VERSION "created by canmatrix"

NS_ :

BS_:

BU_: RadarRearRight RadarRearLeft

BO_ 1310 RRR_Obj07A: 64 Vector__XXX
 SG_ RRR_Obj07A_CRC : 0|16@1+ (1,0) [0|65535] "" Vector__XXX
 SG_ RRR_Obj07A_Ay : 103|9@1+ (0.0625,-16) [-16|15.9375] "m/s^2" Vector__XXX
 SG_ RRR_Obj07A_HeadingYawAngle : 112|9@1+ (0.0175,-4.48) [-3.15|3.15] "rad" Vector__XXX
 SG_ RRR_Obj07A_Length : 121|7@1+ (0.125,0) [0|15.875] "m" Vector__XXX
 SG_ RRR_Obj07A_Width : 128|7@1+ (0.125,0) [0|15.875] "m" Vector__XXX
 SG_ RRR_Obj07A_Height : 135|7@1+ (0.125,0) [0|15.875] "m" Vector__XXX
 SG_ RRR_Obj07A_DxVnce : 142|12@1+ (0.01,0) [0|30] "m^2" Vector__XXX
 SG_ RRR_Obj07A_DyVnce : 154|12@1+ (0.01,0) [0|30] "m^2" Vector__XXX
 SG_ RRR_Obj07A_DzVnce : 166|10@1+ (0.01,0) [0|10] "m^2" Vector__XXX
 SG_ RRR_Obj07A_AliveCtr : 16|8@1+ (1,0) [0|254] "" Vector__XXX
 SG_ RRR_Obj07A_VxVnce : 176|12@1+ (0.01,0) [0|30] "m^2/s^2" Vector__XXX
 SG_ RRR_Obj07A_VyVnce : 188|12@1+ (0.01,0) [0|30] "m^2/s^2" Vector__XXX
 SG_ RRR_Obj07A_AxVnce : 200|12@1+ (0.01,0) [0|30] "m^2/s^4" Vector__XXX
 SG_ RRR_Obj07A_AyVnce : 212|12@1+ (0.01,0) [0|30] "m^2/s^4" Vector__XXX
 SG_ RRR_Obj07A_RefPosIndex : 224|4@1+ (1,0) [0|15] "" Vector__XXX
 SG_ RRR_Obj07A_DxDyCoVnce : 228|12@1+ (0.01,0) [0|30] "m^2" Vector__XXX
 SG_ RRR_Obj07A_DxVxCoVnce : 240|12@1+ (0.01,0) [0|30] "m^2/s" Vector__XXX
 SG_ RRR_Obj07A_BlockCtr : 24|4@1+ (1,0) [0|15] "" Vector__XXX
 SG_ RRR_Obj07A_DyVxCoVnce : 252|12@1+ (0.01,0) [0|30] "m^2/s" Vector__XXX
 SG_ RRR_Obj07A_DxVyCoVnce : 264|12@1+ (0.01,0) [0|30] "m^2/s" Vector__XXX
 SG_ RRR_Obj07A_DyVyCoVnce : 276|12@1+ (0.01,0) [0|30] "m^2/s" Vector__XXX
 SG_ RRR_Obj07A_VxVyCoVnce : 288|12@1+ (0.01,0) [0|30] "m^2/s^2" Vector__XXX
 SG_ RRR_Obj07A_DxAxCoVnce : 300|12@1+ (0.01,0) [0|30] "m^2/s^2" Vector__XXX
 SG_ RRR_Obj07A_DyAxCoVnce : 312|12@1+ (0.01,0) [0|30] "m^2/s^2" Vector__XXX
 SG_ RRR_Obj07A_VxAxCoVnce : 324|12@1+ (0.01,0) [0|30] "m^2/s^3" Vector__XXX
 SG_ RRR_Obj07A_ObjectID : 32|7@1+ (1,0) [0|127] "" Vector__XXX
 SG_ RRR_Obj07A_VyAxCoVnce : 336|12@1+ (0.01,0) [0|30] "m^2/s^3" Vector__XXX
 SG_ RRR_Obj07A_DxAyCoVnce : 348|12@1+ (0.01,0) [0|30] "m^2/s^2" Vector__XXX
 SG_ RRR_Obj07A_DyAyCoVnce : 360|12@1+ (0.01,0) [0|30] "m^2/s^2" Vector__XXX
 SG_ RRR_Obj07A_VxAyCoVnce : 372|12@1+ (0.01,0) [0|30] "m^2/s^3" Vector__XXX
 SG_ RRR_Obj07A_VyAyCoVnce : 384|12@1+ (0.01,0) [0|30] "m^2/s^3" Vector__XXX
 SG_ RRR_Obj07A_AxAyCoVnce : 396|12@1+ (0.01,0) [0|30] "m^2/s^4" Vector__XXX
 SG_ RRR_Obj07A_Measured : 39|1@1+ (1,0) [0|1] "" Vector__XXX
 SG_ RRR_Obj07A_HeadingYawVnce : 408|12@1+ (0.0003,0) [0|1] "rad^2" Vector__XXX
 SG_ RRR_Obj07A_Dx : 40|13@1+ (0.0625,-256) [-256|255.9375] "m" Vector__XXX
 SG_ RRR_Obj07A_LengthVnce : 420|12@1+ (0.01,0) [0|30] "m^2" Vector__XXX
 SG_ RRR_Obj07A_WidthVnce : 432|12@1+ (0.01,0) [0|30] "m^2" Vector__XXX
 SG_ RRR_Obj07A_HeightVnce : 444|12@1+ (0.01,0) [0|30] "m^2" Vector__XXX
 SG_ RRR_Obj07A_ExistProb : 456|6@1+ (2,0) [0|100] "%" Vector__XXX
 SG_ RRR_Obj07A_ProbObstacle : 462|6@1+ (2,0) [0|100] "%" Vector__XXX
 SG_ RRR_Obj07A_ProbNonObstacle : 468|6@1+ (2,0) [0|100] "%" Vector__XXX
 SG_ RRR_Obj07A_ProbMobileObst : 474|6@1+ (2,0) [0|100] "%" Vector__XXX
 SG_ RRR_Obj07A_FV : 487|8@0+ (1,0) [0|255] "" Vector__XXX
 SG_ RRR_Obj07A_MAC : 495|24@0+ (1,0) [0|16777215] "" Vector__XXX
 SG_ RRR_Obj07A_Dz : 53|6@1+ (0.25,-5) [-5|10.75] "m" Vector__XXX
 SG_ RRR_Obj07A_Dy : 59|11@1+ (0.125,-128) [-128|127.875] "m" Vector__XXX
 SG_ RRR_Obj07A_Valid : 70|1@1+ (1,0) [0|1] "" Vector__XXX
 SG_ RRR_Obj07A_Vx : 71|12@1+ (0.0625,-128) [-128|127.9375] "m/s" Vector__XXX
 SG_ RRR_Obj07A_Vy : 83|10@1+ (0.125,-64) [-64|63.875] "m/s" Vector__XXX
 SG_ RRR_Obj07A_Ax : 93|10@1+ (0.03125,-16) [-16|15.96875] "m/s^2" Vector__XXX

BO_ 1311 RRR_Obj07B: 16 Vector__XXX
 SG_ RRR_Obj07B_CRC : 0|16@1+ (1,0) [0|65535] "" Vector__XXX
 SG_ RRR_Obj07B_MAC : 111|24@0+ (1,0) [0|16777215] "" Vector__XXX
 SG_ RRR_Obj07B_AliveCtr : 16|8@1+ (1,0) [0|254] "" Vector__XXX
 SG_ RRR_Obj07B_BlockCtr : 24|4@1+ (1,0) [0|15] "" Vector__XXX
 SG_ RRR_Obj07B_ProbMob4PlusWhl : 28|6@1+ (2,0) [0|100] "%" Vector__XXX
 SG_ RRR_Obj07B_ProbMob2Whl : 34|6@1+ (2,0) [0|100] "%" Vector__XXX
 SG_ RRR_Obj07B_ProbMobPed : 40|6@1+ (2,0) [0|100] "%" Vector__XXX
 SG_ RRR_Obj07B_Prob4PlusWhlCAR : 46|6@1+ (2,0) [0|100] "%" Vector__XXX
 SG_ RRR_Obj07B_Prob4PlusWhlbHGV : 52|6@1+ (2,0) [0|100] "%" Vector__XXX
 SG_ RRR_Obj07B_ProbGNDReflex : 58|6@1+ (2,0) [0|100] "%" Vector__XXX
 SG_ RRR_Obj07B_ProbStatBarrier : 64|6@1+ (2,0) [0|100] "%" Vector__XXX
 SG_ RRR_Obj07B_ProbStatObst : 70|6@1+ (2,0) [0|100] "%" Vector__XXX
 SG_ RRR_Obj07B_MovingProbability : 76|6@1+ (2,0) [0|100] "%" Vector__XXX
 SG_ RRR_Obj07B_MovingObserved : 82|6@1+ (2,0) [0|100] "%" Vector__XXX
 SG_ RRR_Obj07B_FV : 103|8@0+ (1,0) [0|255] "" Vector__XXX

BO_ 1312 RRR_Obj08A: 64 Vector__XXX
 SG_ RRR_Obj08A_CRC : 0|16@1+ (1,0) [0|65535] "" Vector__XXX
 SG_ RRR_Obj08A_Ay : 103|9@1+ (0.0625,-16) [-16|15.9375] "m/s^2" Vector__XXX
 SG_ RRR_Obj08A_HeadingYawAngle : 112|9@1+ (0.0175,-4.48) [-3.15|3.15] "rad" Vector__XXX
 SG_ RRR_Obj08A_Length : 121|7@1+ (0.125,0) [0|15.875] "m" Vector__XXX
 SG_ RRR_Obj08A_Width : 128|7@1+ (0.125,0) [0|15.875] "m" Vector__XXX
 SG_ RRR_Obj08A_Height : 135|7@1+ (0.125,0) [0|15.875] "m" Vector__XXX
 SG_ RRR_Obj08A_DxVnce : 142|12@1+ (0.01,0) [0|30] "m^2" Vector__XXX
 SG_ RRR_Obj08A_DyVnce : 154|12@1+ (0.01,0) [0|30] "m^2" Vector__XXX
 SG_ RRR_Obj08A_DzVnce : 166|10@1+ (0.01,0) [0|10] "m^2" Vector__XXX
 SG_ RRR_Obj08A_AliveCtr : 16|8@1+ (1,0) [0|254] "" Vector__XXX
 SG_ RRR_Obj08A_VxVnce : 176|12@1+ (0.01,0) [0|30] "m^2/s^2" Vector__XXX
 SG_ RRR_Obj08A_VyVnce : 188|12@1+ (0.01,0) [0|30] "m^2/s^2" Vector__XXX
 SG_ RRR_Obj08A_AxVnce : 200|12@1+ (0.01,0) [0|30] "m^2/s^4" Vector__XXX
 SG_ RRR_Obj08A_AyVnce : 212|12@1+ (0.01,0) [0|30] "m^2/s^4" Vector__XXX
 SG_ RRR_Obj08A_RefPosIndex : 224|4@1+ (1,0) [0|15] "" Vector__XXX
 SG_ RRR_Obj08A_DxDyCoVnce : 228|12@1+ (0.01,0) [0|30] "m^2" Vector__XXX
 SG_ RRR_Obj08A_DxVxCoVnce : 240|12@1+ (0.01,0) [0|30] "m^2/s" Vector__XXX
 SG_ RRR_Obj08A_BlockCtr : 24|4@1+ (1,0) [0|15] "" Vector__XXX
 SG_ RRR_Obj08A_DyVxCoVnce : 252|12@1+ (0.01,0) [0|30] "m^2/s" Vector__XXX
 SG_ RRR_Obj08A_DxVyCoVnce : 264|12@1+ (0.01,0) [0|30] "m^2/s" Vector__XXX
 SG_ RRR_Obj08A_DyVyCoVnce : 276|12@1+ (0.01,0) [0|30] "m^2/s" Vector__XXX
 SG_ RRR_Obj08A_VxVyCoVnce : 288|12@1+ (0.01,0) [0|30] "m^2/s^2" Vector__XXX
 SG_ RRR_Obj08A_DxAxCoVnce : 300|12@1+ (0.01,0) [0|30] "m^2/s^2" Vector__XXX
 SG_ RRR_Obj08A_DyAxCoVnce : 312|12@1+ (0.01,0) [0|30] "m^2/s^2" Vector__XXX
 SG_ RRR_Obj08A_VxAxCoVnce : 324|12@1+ (0.01,0) [0|30] "m^2/s^3" Vector__XXX
 SG_ RRR_Obj08A_ObjectID : 32|7@1+ (1,0) [0|127] "" Vector__XXX
 SG_ RRR_Obj08A_VyAxCoVnce : 336|12@1+ (0.01,0) [0|30] "m^2/s^3" Vector__XXX
 SG_ RRR_Obj08A_DxAyCoVnce : 348|12@1+ (0.01,0) [0|30] "m^2/s^2" Vector__XXX
 SG_ RRR_Obj08A_DyAyCoVnce : 360|12@1+ (0.01,0) [0|30] "m^2/s^2" Vector__XXX
 SG_ RRR_Obj08A_VxAyCoVnce : 372|12@1+ (0.01,0) [0|30] "m^2/s^3" Vector__XXX
 SG_ RRR_Obj08A_VyAyCoVnce : 384|12@1+ (0.01,0) [0|30] "m^2/s^3" Vector__XXX
 SG_ RRR_Obj08A_AxAyCoVnce : 396|12@1+ (0.01,0) [0|30] "m^2/s^4" Vector__XXX
 SG_ RRR_Obj08A_Measured : 39|1@1+ (1,0) [0|1] "" Vector__XXX
 SG_ RRR_Obj08A_HeadingYawVnce : 408|12@1+ (0.0003,0) [0|1] "rad^2" Vector__XXX
 SG_ RRR_Obj08A_Dx : 40|13@1+ (0.0625,-256) [-256|255.9375] "m" Vector__XXX
 SG_ RRR_Obj08A_LengthVnce : 420|12@1+ (0.01,0) [0|30] "m^2" Vector__XXX
 SG_ RRR_Obj08A_WidthVnce : 432|12@1+ (0.01,0) [0|30] "m^2" Vector__XXX
 SG_ RRR_Obj08A_HeightVnce : 444|12@1+ (0.01,0) [0|30] "m^2" Vector__XXX
 SG_ RRR_Obj08A_ExistProb : 456|6@1+ (2,0) [0|100] "%" Vector__XXX
 SG_ RRR_Obj08A_ProbObstacle : 462|6@1+ (2,0) [0|100] "%" Vector__XXX
 SG_ RRR_Obj08A_ProbNonObstacle : 468|6@1+ (2,0) [0|100] "%" Vector__XXX
 SG_ RRR_Obj08A_ProbMobileObst : 474|6@1+ (2,0) [0|100] "%" Vector__XXX
 SG_ RRR_Obj08A_FV : 487|8@0+ (1,0) [0|255] "" Vector__XXX
 SG_ RRR_Obj08A_MAC : 495|24@0+ (1,0) [0|16777215] "" Vector__XXX
 SG_ RRR_Obj08A_Dz : 53|6@1+ (0.25,-5) [-5|10.75] "m" Vector__XXX
 SG_ RRR_Obj08A_Dy : 59|11@1+ (0.125,-128) [-128|127.875] "m" Vector__XXX
 SG_ RRR_Obj08A_Valid : 70|1@1+ (1,0) [0|1] "" Vector__XXX
 SG_ RRR_Obj08A_Vx : 71|12@1+ (0.0625,-128) [-128|127.9375] "m/s" Vector__XXX
 SG_ RRR_Obj08A_Vy : 83|10@1+ (0.125,-64) [-64|63.875] "m/s" Vector__XXX
 SG_ RRR_Obj08A_Ax : 93|10@1+ (0.03125,-16) [-16|15.96875] "m/s^2" Vector__XXX

BO_ 1313 RRR_Obj08B: 16 Vector__XXX
 SG_ RRR_Obj08B_CRC : 0|16@1+ (1,0) [0|65535] "" Vector__XXX
 SG_ RRR_Obj08B_MAC : 111|24@0+ (1,0) [0|16777215] "" Vector__XXX
 SG_ RRR_Obj08B_AliveCtr : 16|8@1+ (1,0) [0|254] "" Vector__XXX
 SG_ RRR_Obj08B_BlockCtr : 24|4@1+ (1,0) [0|15] "" Vector__XXX
 SG_ RRR_Obj08B_ProbMob4PlusWhl : 28|6@1+ (2,0) [0|100] "%" Vector__XXX
 SG_ RRR_Obj08B_ProbMob2Whl : 34|6@1+ (2,0) [0|100] "%" Vector__XXX
 SG_ RRR_Obj08B_ProbMobPed : 40|6@1+ (2,0) [0|100] "%" Vector__XXX
 SG_ RRR_Obj08B_Prob4PlusWhlCAR : 46|6@1+ (2,0) [0|100] "%" Vector__XXX
 SG_ RRR_Obj08B_Prob4PlusWhlbHGV : 52|6@1+ (2,0) [0|100] "%" Vector__XXX
 SG_ RRR_Obj08B_ProbGNDReflex : 58|6@1+ (2,0) [0|100] "%" Vector__XXX
 SG_ RRR_Obj08B_ProbStatBarrier : 64|6@1+ (2,0) [0|100] "%" Vector__XXX
 SG_ RRR_Obj08B_ProbStatObst : 70|6@1+ (2,0) [0|100] "%" Vector__XXX
 SG_ RRR_Obj08B_MovingProbability : 76|6@1+ (2,0) [0|100] "%" Vector__XXX
 SG_ RRR_Obj08B_MovingObserved : 82|6@1+ (2,0) [0|100] "%" Vector__XXX
 SG_ RRR_Obj08B_FV : 103|8@0+ (1,0) [0|255] "" Vector__XXX

BO_ 1314 RRR_Obj09A: 64 Vector__XXX
 SG_ RRR_Obj09A_CRC : 0|16@1+ (1,0) [0|65535] "" Vector__XXX
 SG_ RRR_Obj09A_Ay : 103|9@1+ (0.0625,-16) [-16|15.9375] "m/s^2" Vector__XXX
 SG_ RRR_Obj09A_HeadingYawAngle : 112|9@1+ (0.0175,-4.48) [-3.15|3.15] "rad" Vector__XXX
 SG_ RRR_Obj09A_Length : 121|7@1+ (0.125,0) [0|15.875] "m" Vector__XXX
 SG_ RRR_Obj09A_Width : 128|7@1+ (0.125,0) [0|15.875] "m" Vector__XXX
 SG_ RRR_Obj09A_Height : 135|7@1+ (0.125,0) [0|15.875] "m" Vector__XXX
 SG_ RRR_Obj09A_DxVnce : 142|12@1+ (0.01,0) [0|30] "m^2" Vector__XXX
 SG_ RRR_Obj09A_DyVnce : 154|12@1+ (0.01,0) [0|30] "m^2" Vector__XXX
 SG_ RRR_Obj09A_DzVnce : 166|10@1+ (0.01,0) [0|10] "m^2" Vector__XXX
 SG_ RRR_Obj09A_AliveCtr : 16|8@1+ (1,0) [0|254] "" Vector__XXX
 SG_ RRR_Obj09A_VxVnce : 176|12@1+ (0.01,0) [0|30] "m^2/s^2" Vector__XXX
 SG_ RRR_Obj09A_VyVnce : 188|12@1+ (0.01,0) [0|30] "m^2/s^2" Vector__XXX
 SG_ RRR_Obj09A_AxVnce : 200|12@1+ (0.01,0) [0|30] "m^2/s^4" Vector__XXX
 SG_ RRR_Obj09A_AyVnce : 212|12@1+ (0.01,0) [0|30] "m^2/s^4" Vector__XXX
 SG_ RRR_Obj09A_RefPosIndex : 224|4@1+ (1,0) [0|15] "" Vector__XXX
 SG_ RRR_Obj09A_DxDyCoVnce : 228|12@1+ (0.01,0) [0|30] "m^2" Vector__XXX
 SG_ RRR_Obj09A_DxVxCoVnce : 240|12@1+ (0.01,0) [0|30] "m^2/s" Vector__XXX
 SG_ RRR_Obj09A_BlockCtr : 24|4@1+ (1,0) [0|15] "" Vector__XXX
 SG_ RRR_Obj09A_DyVxCoVnce : 252|12@1+ (0.01,0) [0|30] "m^2/s" Vector__XXX
 SG_ RRR_Obj09A_DxVyCoVnce : 264|12@1+ (0.01,0) [0|30] "m^2/s" Vector__XXX
 SG_ RRR_Obj09A_DyVyCoVnce : 276|12@1+ (0.01,0) [0|30] "m^2/s" Vector__XXX
 SG_ RRR_Obj09A_VxVyCoVnce : 288|12@1+ (0.01,0) [0|30] "m^2/s^2" Vector__XXX
 SG_ RRR_Obj09A_DxAxCoVnce : 300|12@1+ (0.01,0) [0|30] "m^2/s^2" Vector__XXX
 SG_ RRR_Obj09A_DyAxCoVnce : 312|12@1+ (0.01,0) [0|30] "m^2/s^2" Vector__XXX
 SG_ RRR_Obj09A_VxAxCoVnce : 324|12@1+ (0.01,0) [0|30] "m^2/s^3" Vector__XXX
 SG_ RRR_Obj09A_ObjectID : 32|7@1+ (1,0) [0|127] "" Vector__XXX
 SG_ RRR_Obj09A_VyAxCoVnce : 336|12@1+ (0.01,0) [0|30] "m^2/s^3" Vector__XXX
 SG_ RRR_Obj09A_DxAyCoVnce : 348|12@1+ (0.01,0) [0|30] "m^2/s^2" Vector__XXX
 SG_ RRR_Obj09A_DyAyCoVnce : 360|12@1+ (0.01,0) [0|30] "m^2/s^2" Vector__XXX
 SG_ RRR_Obj09A_VxAyCoVnce : 372|12@1+ (0.01,0) [0|30] "m^2/s^3" Vector__XXX
 SG_ RRR_Obj09A_VyAyCoVnce : 384|12@1+ (0.01,0) [0|30] "m^2/s^3" Vector__XXX
 SG_ RRR_Obj09A_AxAyCoVnce : 396|12@1+ (0.01,0) [0|30] "m^2/s^4" Vector__XXX
 SG_ RRR_Obj09A_Measured : 39|1@1+ (1,0) [0|1] "" Vector__XXX
 SG_ RRR_Obj09A_HeadingYawVnce : 408|12@1+ (0.0003,0) [0|1] "rad^2" Vector__XXX
 SG_ RRR_Obj09A_Dx : 40|13@1+ (0.0625,-256) [-256|255.9375] "m" Vector__XXX
 SG_ RRR_Obj09A_LengthVnce : 420|12@1+ (0.01,0) [0|30] "m^2" Vector__XXX
 SG_ RRR_Obj09A_WidthVnce : 432|12@1+ (0.01,0) [0|30] "m^2" Vector__XXX
 SG_ RRR_Obj09A_HeightVnce : 444|12@1+ (0.01,0) [0|30] "m^2" Vector__XXX
 SG_ RRR_Obj09A_ExistProb : 456|6@1+ (2,0) [0|100] "%" Vector__XXX
 SG_ RRR_Obj09A_ProbObstacle : 462|6@1+ (2,0) [0|100] "%" Vector__XXX
 SG_ RRR_Obj09A_ProbNonObstacle : 468|6@1+ (2,0) [0|100] "%" Vector__XXX
 SG_ RRR_Obj09A_ProbMobileObst : 474|6@1+ (2,0) [0|100] "%" Vector__XXX
 SG_ RRR_Obj09A_FV : 487|8@0+ (1,0) [0|255] "" Vector__XXX
 SG_ RRR_Obj09A_MAC : 495|24@0+ (1,0) [0|16777215] "" Vector__XXX
 SG_ RRR_Obj09A_Dz : 53|6@1+ (0.25,-5) [-5|10.75] "m" Vector__XXX
 SG_ RRR_Obj09A_Dy : 59|11@1+ (0.125,-128) [-128|127.875] "m" Vector__XXX
 SG_ RRR_Obj09A_Valid : 70|1@1+ (1,0) [0|1] "" Vector__XXX
 SG_ RRR_Obj09A_Vx : 71|12@1+ (0.0625,-128) [-128|127.9375] "m/s" Vector__XXX
 SG_ RRR_Obj09A_Vy : 83|10@1+ (0.125,-64) [-64|63.875] "m/s" Vector__XXX
 SG_ RRR_Obj09A_Ax : 93|10@1+ (0.03125,-16) [-16|15.96875] "m/s^2" Vector__XXX

BO_ 1315 RRR_Obj09B: 16 Vector__XXX
 SG_ RRR_Obj09B_CRC : 0|16@1+ (1,0) [0|65535] "" Vector__XXX
 SG_ RRR_Obj09B_MAC : 111|24@0+ (1,0) [0|16777215] "" Vector__XXX
 SG_ RRR_Obj09B_AliveCtr : 16|8@1+ (1,0) [0|254] "" Vector__XXX
 SG_ RRR_Obj09B_BlockCtr : 24|4@1+ (1,0) [0|15] "" Vector__XXX
 SG_ RRR_Obj09B_ProbMob4PlusWhl : 28|6@1+ (2,0) [0|100] "%" Vector__XXX
 SG_ RRR_Obj09B_ProbMob2Whl : 34|6@1+ (2,0) [0|100] "%" Vector__XXX
 SG_ RRR_Obj09B_ProbMobPed : 40|6@1+ (2,0) [0|100] "%" Vector__XXX
 SG_ RRR_Obj09B_Prob4PlusWhlCAR : 46|6@1+ (2,0) [0|100] "%" Vector__XXX
 SG_ RRR_Obj09B_Prob4PlusWhlbHGV : 52|6@1+ (2,0) [0|100] "%" Vector__XXX
 SG_ RRR_Obj09B_ProbGNDReflex : 58|6@1+ (2,0) [0|100] "%" Vector__XXX
 SG_ RRR_Obj09B_ProbStatBarrier : 64|6@1+ (2,0) [0|100] "%" Vector__XXX
 SG_ RRR_Obj09B_ProbStatObst : 70|6@1+ (2,0) [0|100] "%" Vector__XXX
 SG_ RRR_Obj09B_MovingProbability : 76|6@1+ (2,0) [0|100] "%" Vector__XXX
 SG_ RRR_Obj09B_MovingObserved : 82|6@1+ (2,0) [0|100] "%" Vector__XXX
 SG_ RRR_Obj09B_FV : 103|8@0+ (1,0) [0|255] "" Vector__XXX

BO_ 1316 RRR_Obj10A: 64 Vector__XXX
 SG_ RRR_Obj10A_CRC : 0|16@1+ (1,0) [0|65535] "" Vector__XXX
 SG_ RRR_Obj10A_Ay : 103|9@1+ (0.0625,-16) [-16|15.9375] "m/s^2" Vector__XXX
 SG_ RRR_Obj10A_HeadingYawAngle : 112|9@1+ (0.0175,-4.48) [-3.15|3.15] "rad" Vector__XXX
 SG_ RRR_Obj10A_Length : 121|7@1+ (0.125,0) [0|15.875] "m" Vector__XXX
 SG_ RRR_Obj10A_Width : 128|7@1+ (0.125,0) [0|15.875] "m" Vector__XXX
 SG_ RRR_Obj10A_Height : 135|7@1+ (0.125,0) [0|15.875] "m" Vector__XXX
 SG_ RRR_Obj10A_DxVnce : 142|12@1+ (0.01,0) [0|30] "m^2" Vector__XXX
 SG_ RRR_Obj10A_DyVnce : 154|12@1+ (0.01,0) [0|30] "m^2" Vector__XXX
 SG_ RRR_Obj10A_DzVnce : 166|10@1+ (0.01,0) [0|10] "m^2" Vector__XXX
 SG_ RRR_Obj10A_AliveCtr : 16|8@1+ (1,0) [0|254] "" Vector__XXX
 SG_ RRR_Obj10A_VxVnce : 176|12@1+ (0.01,0) [0|30] "m^2/s^2" Vector__XXX
 SG_ RRR_Obj10A_VyVnce : 188|12@1+ (0.01,0) [0|30] "m^2/s^2" Vector__XXX
 SG_ RRR_Obj10A_AxVnce : 200|12@1+ (0.01,0) [0|30] "m^2/s^4" Vector__XXX
 SG_ RRR_Obj10A_AyVnce : 212|12@1+ (0.01,0) [0|30] "m^2/s^4" Vector__XXX
 SG_ RRR_Obj10A_RefPosIndex : 224|4@1+ (1,0) [0|15] "" Vector__XXX
 SG_ RRR_Obj10A_DxDyCoVnce : 228|12@1+ (0.01,0) [0|30] "m^2" Vector__XXX
 SG_ RRR_Obj10A_DxVxCoVnce : 240|12@1+ (0.01,0) [0|30] "m^2/s" Vector__XXX
 SG_ RRR_Obj10A_BlockCtr : 24|4@1+ (1,0) [0|15] "" Vector__XXX
 SG_ RRR_Obj10A_DyVxCoVnce : 252|12@1+ (0.01,0) [0|30] "m^2/s" Vector__XXX
 SG_ RRR_Obj10A_DxVyCoVnce : 264|12@1+ (0.01,0) [0|30] "m^2/s" Vector__XXX
 SG_ RRR_Obj10A_DyVyCoVnce : 276|12@1+ (0.01,0) [0|30] "m^2/s" Vector__XXX
 SG_ RRR_Obj10A_VxVyCoVnce : 288|12@1+ (0.01,0) [0|30] "m^2/s^2" Vector__XXX
 SG_ RRR_Obj10A_DxAxCoVnce : 300|12@1+ (0.01,0) [0|30] "m^2/s^2" Vector__XXX
 SG_ RRR_Obj10A_DyAxCoVnce : 312|12@1+ (0.01,0) [0|30] "m^2/s^2" Vector__XXX
 SG_ RRR_Obj10A_VxAxCoVnce : 324|12@1+ (0.01,0) [0|30] "m^2/s^3" Vector__XXX
 SG_ RRR_Obj10A_ObjectID : 32|7@1+ (1,0) [0|127] "" Vector__XXX
 SG_ RRR_Obj10A_VyAxCoVnce : 336|12@1+ (0.01,0) [0|30] "m^2/s^3" Vector__XXX
 SG_ RRR_Obj10A_DxAyCoVnce : 348|12@1+ (0.01,0) [0|30] "m^2/s^2" Vector__XXX
 SG_ RRR_Obj10A_DyAyCoVnce : 360|12@1+ (0.01,0) [0|30] "m^2/s^2" Vector__XXX
 SG_ RRR_Obj10A_VxAyCoVnce : 372|12@1+ (0.01,0) [0|30] "m^2/s^3" Vector__XXX
 SG_ RRR_Obj10A_VyAyCoVnce : 384|12@1+ (0.01,0) [0|30] "m^2/s^3" Vector__XXX
 SG_ RRR_Obj10A_AxAyCoVnce : 396|12@1+ (0.01,0) [0|30] "m^2/s^4" Vector__XXX
 SG_ RRR_Obj10A_Measured : 39|1@1+ (1,0) [0|1] "" Vector__XXX
 SG_ RRR_Obj10A_HeadingYawVnce : 408|12@1+ (0.0003,0) [0|1] "rad^2" Vector__XXX
 SG_ RRR_Obj10A_Dx : 40|13@1+ (0.0625,-256) [-256|255.9375] "m" Vector__XXX
 SG_ RRR_Obj10A_LengthVnce : 420|12@1+ (0.01,0) [0|30] "m^2" Vector__XXX
 SG_ RRR_Obj10A_WidthVnce : 432|12@1+ (0.01,0) [0|30] "m^2" Vector__XXX
 SG_ RRR_Obj10A_HeightVnce : 444|12@1+ (0.01,0) [0|30] "m^2" Vector__XXX
 SG_ RRR_Obj10A_ExistProb : 456|6@1+ (2,0) [0|100] "%" Vector__XXX
 SG_ RRR_Obj10A_ProbObstacle : 462|6@1+ (2,0) [0|100] "%" Vector__XXX
 SG_ RRR_Obj10A_ProbNonObstacle : 468|6@1+ (2,0) [0|100] "%" Vector__XXX
 SG_ RRR_Obj10A_ProbMobileObst : 474|6@1+ (2,0) [0|100] "%" Vector__XXX
 SG_ RRR_Obj10A_FV : 487|8@0+ (1,0) [0|255] "" Vector__XXX
 SG_ RRR_Obj10A_MAC : 495|24@0+ (1,0) [0|16777215] "" Vector__XXX
 SG_ RRR_Obj10A_Dz : 53|6@1+ (0.25,-5) [-5|10.75] "m" Vector__XXX
 SG_ RRR_Obj10A_Dy : 59|11@1+ (0.125,-128) [-128|127.875] "m" Vector__XXX
 SG_ RRR_Obj10A_Valid : 70|1@1+ (1,0) [0|1] "" Vector__XXX
 SG_ RRR_Obj10A_Vx : 71|12@1+ (0.0625,-128) [-128|127.9375] "m/s" Vector__XXX
 SG_ RRR_Obj10A_Vy : 83|10@1+ (0.125,-64) [-64|63.875] "m/s" Vector__XXX
 SG_ RRR_Obj10A_Ax : 93|10@1+ (0.03125,-16) [-16|15.96875] "m/s^2" Vector__XXX

BO_ 1317 RRR_Obj10B: 16 Vector__XXX
 SG_ RRR_Obj10B_CRC : 0|16@1+ (1,0) [0|65535] "" Vector__XXX
 SG_ RRR_Obj10B_MAC : 111|24@0+ (1,0) [0|16777215] "" Vector__XXX
 SG_ RRR_Obj10B_AliveCtr : 16|8@1+ (1,0) [0|254] "" Vector__XXX
 SG_ RRR_Obj10B_BlockCtr : 24|4@1+ (1,0) [0|15] "" Vector__XXX
 SG_ RRR_Obj10B_ProbMob4PlusWhl : 28|6@1+ (2,0) [0|100] "%" Vector__XXX
 SG_ RRR_Obj10B_ProbMob2Whl : 34|6@1+ (2,0) [0|100] "%" Vector__XXX
 SG_ RRR_Obj10B_ProbMobPed : 40|6@1+ (2,0) [0|100] "%" Vector__XXX
 SG_ RRR_Obj10B_Prob4PlusWhlCAR : 46|6@1+ (2,0) [0|100] "%" Vector__XXX
 SG_ RRR_Obj10B_Prob4PlusWhlbHGV : 52|6@1+ (2,0) [0|100] "%" Vector__XXX
 SG_ RRR_Obj10B_ProbGNDReflex : 58|6@1+ (2,0) [0|100] "%" Vector__XXX
 SG_ RRR_Obj10B_ProbStatBarrier : 64|6@1+ (2,0) [0|100] "%" Vector__XXX
 SG_ RRR_Obj10B_ProbStatObst : 70|6@1+ (2,0) [0|100] "%" Vector__XXX
 SG_ RRR_Obj10B_MovingProbability : 76|6@1+ (2,0) [0|100] "%" Vector__XXX
 SG_ RRR_Obj10B_MovingObserved : 82|6@1+ (2,0) [0|100] "%" Vector__XXX
 SG_ RRR_Obj10B_FV : 103|8@0+ (1,0) [0|255] "" Vector__XXX

BO_ 1318 RRR_Obj11A: 64 Vector__XXX
 SG_ RRR_Obj11A_CRC : 0|16@1+ (1,0) [0|65535] "" Vector__XXX
 SG_ RRR_Obj11A_Ay : 103|9@1+ (0.0625,-16) [-16|15.9375] "m/s^2" Vector__XXX
 SG_ RRR_Obj11A_HeadingYawAngle : 112|9@1+ (0.0175,-4.48) [-3.15|3.15] "rad" Vector__XXX
 SG_ RRR_Obj11A_Length : 121|7@1+ (0.125,0) [0|15.875] "m" Vector__XXX
 SG_ RRR_Obj11A_Width : 128|7@1+ (0.125,0) [0|15.875] "m" Vector__XXX
 SG_ RRR_Obj11A_Height : 135|7@1+ (0.125,0) [0|15.875] "m" Vector__XXX
 SG_ RRR_Obj11A_DxVnce : 142|12@1+ (0.01,0) [0|30] "m^2" Vector__XXX
 SG_ RRR_Obj11A_DyVnce : 154|12@1+ (0.01,0) [0|30] "m^2" Vector__XXX
 SG_ RRR_Obj11A_DzVnce : 166|10@1+ (0.01,0) [0|10] "m^2" Vector__XXX
 SG_ RRR_Obj11A_AliveCtr : 16|8@1+ (1,0) [0|254] "" Vector__XXX
 SG_ RRR_Obj11A_VxVnce : 176|12@1+ (0.01,0) [0|30] "m^2/s^2" Vector__XXX
 SG_ RRR_Obj11A_VyVnce : 188|12@1+ (0.01,0) [0|30] "m^2/s^2" Vector__XXX
 SG_ RRR_Obj11A_AxVnce : 200|12@1+ (0.01,0) [0|30] "m^2/s^4" Vector__XXX
 SG_ RRR_Obj11A_AyVnce : 212|12@1+ (0.01,0) [0|30] "m^2/s^4" Vector__XXX
 SG_ RRR_Obj11A_RefPosIndex : 224|4@1+ (1,0) [0|15] "" Vector__XXX
 SG_ RRR_Obj11A_DxDyCoVnce : 228|12@1+ (0.01,0) [0|30] "m^2" Vector__XXX
 SG_ RRR_Obj11A_DxVxCoVnce : 240|12@1+ (0.01,0) [0|30] "m^2/s" Vector__XXX
 SG_ RRR_Obj11A_BlockCtr : 24|4@1+ (1,0) [0|15] "" Vector__XXX
 SG_ RRR_Obj11A_DyVxCoVnce : 252|12@1+ (0.01,0) [0|30] "m^2/s" Vector__XXX
 SG_ RRR_Obj11A_DxVyCoVnce : 264|12@1+ (0.01,0) [0|30] "m^2/s" Vector__XXX
 SG_ RRR_Obj11A_DyVyCoVnce : 276|12@1+ (0.01,0) [0|30] "m^2/s" Vector__XXX
 SG_ RRR_Obj11A_VxVyCoVnce : 288|12@1+ (0.01,0) [0|30] "m^2/s^2" Vector__XXX
 SG_ RRR_Obj11A_DxAxCoVnce : 300|12@1+ (0.01,0) [0|30] "m^2/s^2" Vector__XXX
 SG_ RRR_Obj11A_DyAxCoVnce : 312|12@1+ (0.01,0) [0|30] "m^2/s^2" Vector__XXX
 SG_ RRR_Obj11A_VxAxCoVnce : 324|12@1+ (0.01,0) [0|30] "m^2/s^3" Vector__XXX
 SG_ RRR_Obj11A_ObjectID : 32|7@1+ (1,0) [0|127] "" Vector__XXX
 SG_ RRR_Obj11A_VyAxCoVnce : 336|12@1+ (0.01,0) [0|30] "m^2/s^3" Vector__XXX
 SG_ RRR_Obj11A_DxAyCoVnce : 348|12@1+ (0.01,0) [0|30] "m^2/s^2" Vector__XXX
 SG_ RRR_Obj11A_DyAyCoVnce : 360|12@1+ (0.01,0) [0|30] "m^2/s^2" Vector__XXX
 SG_ RRR_Obj11A_VxAyCoVnce : 372|12@1+ (0.01,0) [0|30] "m^2/s^3" Vector__XXX
 SG_ RRR_Obj11A_VyAyCoVnce : 384|12@1+ (0.01,0) [0|30] "m^2/s^3" Vector__XXX
 SG_ RRR_Obj11A_AxAyCoVnce : 396|12@1+ (0.01,0) [0|30] "m^2/s^4" Vector__XXX
 SG_ RRR_Obj11A_Measured : 39|1@1+ (1,0) [0|1] "" Vector__XXX
 SG_ RRR_Obj11A_HeadingYawVnce : 408|12@1+ (0.0003,0) [0|1] "rad^2" Vector__XXX
 SG_ RRR_Obj11A_Dx : 40|13@1+ (0.0625,-256) [-256|255.9375] "m" Vector__XXX
 SG_ RRR_Obj11A_LengthVnce : 420|12@1+ (0.01,0) [0|30] "m^2" Vector__XXX
 SG_ RRR_Obj11A_WidthVnce : 432|12@1+ (0.01,0) [0|30] "m^2" Vector__XXX
 SG_ RRR_Obj11A_HeightVnce : 444|12@1+ (0.01,0) [0|30] "m^2" Vector__XXX
 SG_ RRR_Obj11A_ExistProb : 456|6@1+ (2,0) [0|100] "%" Vector__XXX
 SG_ RRR_Obj11A_ProbObstacle : 462|6@1+ (2,0) [0|100] "%" Vector__XXX
 SG_ RRR_Obj11A_ProbNonObstacle : 468|6@1+ (2,0) [0|100] "%" Vector__XXX
 SG_ RRR_Obj11A_ProbMobileObst : 474|6@1+ (2,0) [0|100] "%" Vector__XXX
 SG_ RRR_Obj11A_FV : 487|8@0+ (1,0) [0|255] "" Vector__XXX
 SG_ RRR_Obj11A_MAC : 495|24@0+ (1,0) [0|16777215] "" Vector__XXX
 SG_ RRR_Obj11A_Dz : 53|6@1+ (0.25,-5) [-5|10.75] "m" Vector__XXX
 SG_ RRR_Obj11A_Dy : 59|11@1+ (0.125,-128) [-128|127.875] "m" Vector__XXX
 SG_ RRR_Obj11A_Valid : 70|1@1+ (1,0) [0|1] "" Vector__XXX
 SG_ RRR_Obj11A_Vx : 71|12@1+ (0.0625,-128) [-128|127.9375] "m/s" Vector__XXX
 SG_ RRR_Obj11A_Vy : 83|10@1+ (0.125,-64) [-64|63.875] "m/s" Vector__XXX
 SG_ RRR_Obj11A_Ax : 93|10@1+ (0.03125,-16) [-16|15.96875] "m/s^2" Vector__XXX

BO_ 1319 RRR_Obj11B: 16 Vector__XXX
 SG_ RRR_Obj11B_CRC : 0|16@1+ (1,0) [0|65535] "" Vector__XXX
 SG_ RRR_Obj11B_MAC : 111|24@0+ (1,0) [0|16777215] "" Vector__XXX
 SG_ RRR_Obj11B_AliveCtr : 16|8@1+ (1,0) [0|254] "" Vector__XXX
 SG_ RRR_Obj11B_BlockCtr : 24|4@1+ (1,0) [0|15] "" Vector__XXX
 SG_ RRR_Obj11B_ProbMob4PlusWhl : 28|6@1+ (2,0) [0|100] "%" Vector__XXX
 SG_ RRR_Obj11B_ProbMob2Whl : 34|6@1+ (2,0) [0|100] "%" Vector__XXX
 SG_ RRR_Obj11B_ProbMobPed : 40|6@1+ (2,0) [0|100] "%" Vector__XXX
 SG_ RRR_Obj11B_Prob4PlusWhlCAR : 46|6@1+ (2,0) [0|100] "%" Vector__XXX
 SG_ RRR_Obj11B_Prob4PlusWhlbHGV : 52|6@1+ (2,0) [0|100] "%" Vector__XXX
 SG_ RRR_Obj11B_ProbGNDReflex : 58|6@1+ (2,0) [0|100] "%" Vector__XXX
 SG_ RRR_Obj11B_ProbStatBarrier : 64|6@1+ (2,0) [0|100] "%" Vector__XXX
 SG_ RRR_Obj11B_ProbStatObst : 70|6@1+ (2,0) [0|100] "%" Vector__XXX
 SG_ RRR_Obj11B_MovingProbability : 76|6@1+ (2,0) [0|100] "%" Vector__XXX
 SG_ RRR_Obj11B_MovingObserved : 82|6@1+ (2,0) [0|100] "%" Vector__XXX
 SG_ RRR_Obj11B_FV : 103|8@0+ (1,0) [0|255] "" Vector__XXX

BO_ 1320 RRR_Obj12A: 64 Vector__XXX
 SG_ RRR_Obj12A_CRC : 0|16@1+ (1,0) [0|65535] "" Vector__XXX
 SG_ RRR_Obj12A_Ay : 103|9@1+ (0.0625,-16) [-16|15.9375] "m/s^2" Vector__XXX
 SG_ RRR_Obj12A_HeadingYawAngle : 112|9@1+ (0.0175,-4.48) [-3.15|3.15] "rad" Vector__XXX
 SG_ RRR_Obj12A_Length : 121|7@1+ (0.125,0) [0|15.875] "m" Vector__XXX
 SG_ RRR_Obj12A_Width : 128|7@1+ (0.125,0) [0|15.875] "m" Vector__XXX
 SG_ RRR_Obj12A_Height : 135|7@1+ (0.125,0) [0|15.875] "m" Vector__XXX
 SG_ RRR_Obj12A_DxVnce : 142|12@1+ (0.01,0) [0|30] "m^2" Vector__XXX
 SG_ RRR_Obj12A_DyVnce : 154|12@1+ (0.01,0) [0|30] "m^2" Vector__XXX
 SG_ RRR_Obj12A_DzVnce : 166|10@1+ (0.01,0) [0|10] "m^2" Vector__XXX
 SG_ RRR_Obj12A_AliveCtr : 16|8@1+ (1,0) [0|254] "" Vector__XXX
 SG_ RRR_Obj12A_VxVnce : 176|12@1+ (0.01,0) [0|30] "m^2/s^2" Vector__XXX
 SG_ RRR_Obj12A_VyVnce : 188|12@1+ (0.01,0) [0|30] "m^2/s^2" Vector__XXX
 SG_ RRR_Obj12A_AxVnce : 200|12@1+ (0.01,0) [0|30] "m^2/s^4" Vector__XXX
 SG_ RRR_Obj12A_AyVnce : 212|12@1+ (0.01,0) [0|30] "m^2/s^4" Vector__XXX
 SG_ RRR_Obj12A_RefPosIndex : 224|4@1+ (1,0) [0|15] "" Vector__XXX
 SG_ RRR_Obj12A_DxDyCoVnce : 228|12@1+ (0.01,0) [0|30] "m^2" Vector__XXX
 SG_ RRR_Obj12A_DxVxCoVnce : 240|12@1+ (0.01,0) [0|30] "m^2/s" Vector__XXX
 SG_ RRR_Obj12A_BlockCtr : 24|4@1+ (1,0) [0|15] "" Vector__XXX
 SG_ RRR_Obj12A_DyVxCoVnce : 252|12@1+ (0.01,0) [0|30] "m^2/s" Vector__XXX
 SG_ RRR_Obj12A_DxVyCoVnce : 264|12@1+ (0.01,0) [0|30] "m^2/s" Vector__XXX
 SG_ RRR_Obj12A_DyVyCoVnce : 276|12@1+ (0.01,0) [0|30] "m^2/s" Vector__XXX
 SG_ RRR_Obj12A_VxVyCoVnce : 288|12@1+ (0.01,0) [0|30] "m^2/s^2" Vector__XXX
 SG_ RRR_Obj12A_DxAxCoVnce : 300|12@1+ (0.01,0) [0|30] "m^2/s^2" Vector__XXX
 SG_ RRR_Obj12A_DyAxCoVnce : 312|12@1+ (0.01,0) [0|30] "m^2/s^2" Vector__XXX
 SG_ RRR_Obj12A_VxAxCoVnce : 324|12@1+ (0.01,0) [0|30] "m^2/s^3" Vector__XXX
 SG_ RRR_Obj12A_ObjectID : 32|7@1+ (1,0) [0|127] "" Vector__XXX
 SG_ RRR_Obj12A_VyAxCoVnce : 336|12@1+ (0.01,0) [0|30] "m^2/s^3" Vector__XXX
 SG_ RRR_Obj12A_DxAyCoVnce : 348|12@1+ (0.01,0) [0|30] "m^2/s^2" Vector__XXX
 SG_ RRR_Obj12A_DyAyCoVnce : 360|12@1+ (0.01,0) [0|30] "m^2/s^2" Vector__XXX
 SG_ RRR_Obj12A_VxAyCoVnce : 372|12@1+ (0.01,0) [0|30] "m^2/s^3" Vector__XXX
 SG_ RRR_Obj12A_VyAyCoVnce : 384|12@1+ (0.01,0) [0|30] "m^2/s^3" Vector__XXX
 SG_ RRR_Obj12A_AxAyCoVnce : 396|12@1+ (0.01,0) [0|30] "m^2/s^4" Vector__XXX
 SG_ RRR_Obj12A_Measured : 39|1@1+ (1,0) [0|1] "" Vector__XXX
 SG_ RRR_Obj12A_HeadingYawVnce : 408|12@1+ (0.0003,0) [0|1] "rad^2" Vector__XXX
 SG_ RRR_Obj12A_Dx : 40|13@1+ (0.0625,-256) [-256|255.9375] "m" Vector__XXX
 SG_ RRR_Obj12A_LengthVnce : 420|12@1+ (0.01,0) [0|30] "m^2" Vector__XXX
 SG_ RRR_Obj12A_WidthVnce : 432|12@1+ (0.01,0) [0|30] "m^2" Vector__XXX
 SG_ RRR_Obj12A_HeightVnce : 444|12@1+ (0.01,0) [0|30] "m^2" Vector__XXX
 SG_ RRR_Obj12A_ExistProb : 456|6@1+ (2,0) [0|100] "%" Vector__XXX
 SG_ RRR_Obj12A_ProbObstacle : 462|6@1+ (2,0) [0|100] "%" Vector__XXX
 SG_ RRR_Obj12A_ProbNonObstacle : 468|6@1+ (2,0) [0|100] "%" Vector__XXX
 SG_ RRR_Obj12A_ProbMobileObst : 474|6@1+ (2,0) [0|100] "%" Vector__XXX
 SG_ RRR_Obj12A_FV : 487|8@0+ (1,0) [0|255] "" Vector__XXX
 SG_ RRR_Obj12A_MAC : 495|24@0+ (1,0) [0|16777215] "" Vector__XXX
 SG_ RRR_Obj12A_Dz : 53|6@1+ (0.25,-5) [-5|10.75] "m" Vector__XXX
 SG_ RRR_Obj12A_Dy : 59|11@1+ (0.125,-128) [-128|127.875] "m" Vector__XXX
 SG_ RRR_Obj12A_Valid : 70|1@1+ (1,0) [0|1] "" Vector__XXX
 SG_ RRR_Obj12A_Vx : 71|12@1+ (0.0625,-128) [-128|127.9375] "m/s" Vector__XXX
 SG_ RRR_Obj12A_Vy : 83|10@1+ (0.125,-64) [-64|63.875] "m/s" Vector__XXX
 SG_ RRR_Obj12A_Ax : 93|10@1+ (0.03125,-16) [-16|15.96875] "m/s^2" Vector__XXX

BO_ 1321 RRR_Obj12B: 16 Vector__XXX
 SG_ RRR_Obj12B_CRC : 0|16@1+ (1,0) [0|65535] "" Vector__XXX
 SG_ RRR_Obj12B_MAC : 111|24@0+ (1,0) [0|16777215] "" Vector__XXX
 SG_ RRR_Obj12B_AliveCtr : 16|8@1+ (1,0) [0|254] "" Vector__XXX
 SG_ RRR_Obj12B_BlockCtr : 24|4@1+ (1,0) [0|15] "" Vector__XXX
 SG_ RRR_Obj12B_ProbMob4PlusWhl : 28|6@1+ (2,0) [0|100] "%" Vector__XXX
 SG_ RRR_Obj12B_ProbMob2Whl : 34|6@1+ (2,0) [0|100] "%" Vector__XXX
 SG_ RRR_Obj12B_ProbMobPed : 40|6@1+ (2,0) [0|100] "%" Vector__XXX
 SG_ RRR_Obj12B_Prob4PlusWhlCAR : 46|6@1+ (2,0) [0|100] "%" Vector__XXX
 SG_ RRR_Obj12B_Prob4PlusWhlbHGV : 52|6@1+ (2,0) [0|100] "%" Vector__XXX
 SG_ RRR_Obj12B_ProbGNDReflex : 58|6@1+ (2,0) [0|100] "%" Vector__XXX
 SG_ RRR_Obj12B_ProbStatBarrier : 64|6@1+ (2,0) [0|100] "%" Vector__XXX
 SG_ RRR_Obj12B_ProbStatObst : 70|6@1+ (2,0) [0|100] "%" Vector__XXX
 SG_ RRR_Obj12B_MovingProbability : 76|6@1+ (2,0) [0|100] "%" Vector__XXX
 SG_ RRR_Obj12B_MovingObserved : 82|6@1+ (2,0) [0|100] "%" Vector__XXX
 SG_ RRR_Obj12B_FV : 103|8@0+ (1,0) [0|255] "" Vector__XXX

BO_ 1322 RRR_Obj13A: 64 Vector__XXX
 SG_ RRR_Obj13A_CRC : 0|16@1+ (1,0) [0|65535] "" Vector__XXX
 SG_ RRR_Obj13A_Ay : 103|9@1+ (0.0625,-16) [-16|15.9375] "m/s^2" Vector__XXX
 SG_ RRR_Obj13A_HeadingYawAngle : 112|9@1+ (0.0175,-4.48) [-3.15|3.15] "rad" Vector__XXX
 SG_ RRR_Obj13A_Length : 121|7@1+ (0.125,0) [0|15.875] "m" Vector__XXX
 SG_ RRR_Obj13A_Width : 128|7@1+ (0.125,0) [0|15.875] "m" Vector__XXX
 SG_ RRR_Obj13A_Height : 135|7@1+ (0.125,0) [0|15.875] "m" Vector__XXX
 SG_ RRR_Obj13A_DxVnce : 142|12@1+ (0.01,0) [0|30] "m^2" Vector__XXX
 SG_ RRR_Obj13A_DyVnce : 154|12@1+ (0.01,0) [0|30] "m^2" Vector__XXX
 SG_ RRR_Obj13A_DzVnce : 166|10@1+ (0.01,0) [0|10] "m^2" Vector__XXX
 SG_ RRR_Obj13A_AliveCtr : 16|8@1+ (1,0) [0|254] "" Vector__XXX
 SG_ RRR_Obj13A_VxVnce : 176|12@1+ (0.01,0) [0|30] "m^2/s^2" Vector__XXX
 SG_ RRR_Obj13A_VyVnce : 188|12@1+ (0.01,0) [0|30] "m^2/s^2" Vector__XXX
 SG_ RRR_Obj13A_AxVnce : 200|12@1+ (0.01,0) [0|30] "m^2/s^4" Vector__XXX
 SG_ RRR_Obj13A_AyVnce : 212|12@1+ (0.01,0) [0|30] "m^2/s^4" Vector__XXX
 SG_ RRR_Obj13A_RefPosIndex : 224|4@1+ (1,0) [0|15] "" Vector__XXX
 SG_ RRR_Obj13A_DxDyCoVnce : 228|12@1+ (0.01,0) [0|30] "m^2" Vector__XXX
 SG_ RRR_Obj13A_DxVxCoVnce : 240|12@1+ (0.01,0) [0|30] "m^2/s" Vector__XXX
 SG_ RRR_Obj13A_BlockCtr : 24|4@1+ (1,0) [0|15] "" Vector__XXX
 SG_ RRR_Obj13A_DyVxCoVnce : 252|12@1+ (0.01,0) [0|30] "m^2/s" Vector__XXX
 SG_ RRR_Obj13A_DxVyCoVnce : 264|12@1+ (0.01,0) [0|30] "m^2/s" Vector__XXX
 SG_ RRR_Obj13A_DyVyCoVnce : 276|12@1+ (0.01,0) [0|30] "m^2/s" Vector__XXX
 SG_ RRR_Obj13A_VxVyCoVnce : 288|12@1+ (0.01,0) [0|30] "m^2/s^2" Vector__XXX
 SG_ RRR_Obj13A_DxAxCoVnce : 300|12@1+ (0.01,0) [0|30] "m^2/s^2" Vector__XXX
 SG_ RRR_Obj13A_DyAxCoVnce : 312|12@1+ (0.01,0) [0|30] "m^2/s^2" Vector__XXX
 SG_ RRR_Obj13A_VxAxCoVnce : 324|12@1+ (0.01,0) [0|30] "m^2/s^3" Vector__XXX
 SG_ RRR_Obj13A_ObjectID : 32|7@1+ (1,0) [0|127] "" Vector__XXX
 SG_ RRR_Obj13A_VyAxCoVnce : 336|12@1+ (0.01,0) [0|30] "m^2/s^3" Vector__XXX
 SG_ RRR_Obj13A_DxAyCoVnce : 348|12@1+ (0.01,0) [0|30] "m^2/s^2" Vector__XXX
 SG_ RRR_Obj13A_DyAyCoVnce : 360|12@1+ (0.01,0) [0|30] "m^2/s^2" Vector__XXX
 SG_ RRR_Obj13A_VxAyCoVnce : 372|12@1+ (0.01,0) [0|30] "m^2/s^3" Vector__XXX
 SG_ RRR_Obj13A_VyAyCoVnce : 384|12@1+ (0.01,0) [0|30] "m^2/s^3" Vector__XXX
 SG_ RRR_Obj13A_AxAyCoVnce : 396|12@1+ (0.01,0) [0|30] "m^2/s^4" Vector__XXX
 SG_ RRR_Obj13A_Measured : 39|1@1+ (1,0) [0|1] "" Vector__XXX
 SG_ RRR_Obj13A_HeadingYawVnce : 408|12@1+ (0.0003,0) [0|1] "rad^2" Vector__XXX
 SG_ RRR_Obj13A_Dx : 40|13@1+ (0.0625,-256) [-256|255.9375] "m" Vector__XXX
 SG_ RRR_Obj13A_LengthVnce : 420|12@1+ (0.01,0) [0|30] "m^2" Vector__XXX
 SG_ RRR_Obj13A_WidthVnce : 432|12@1+ (0.01,0) [0|30] "m^2" Vector__XXX
 SG_ RRR_Obj13A_HeightVnce : 444|12@1+ (0.01,0) [0|30] "m^2" Vector__XXX
 SG_ RRR_Obj13A_ExistProb : 456|6@1+ (2,0) [0|100] "%" Vector__XXX
 SG_ RRR_Obj13A_ProbObstacle : 462|6@1+ (2,0) [0|100] "%" Vector__XXX
 SG_ RRR_Obj13A_ProbNonObstacle : 468|6@1+ (2,0) [0|100] "%" Vector__XXX
 SG_ RRR_Obj13A_ProbMobileObst : 474|6@1+ (2,0) [0|100] "%" Vector__XXX
 SG_ RRR_Obj13A_FV : 487|8@0+ (1,0) [0|255] "" Vector__XXX
 SG_ RRR_Obj13A_MAC : 495|24@0+ (1,0) [0|16777215] "" Vector__XXX
 SG_ RRR_Obj13A_Dz : 53|6@1+ (0.25,-5) [-5|10.75] "m" Vector__XXX
 SG_ RRR_Obj13A_Dy : 59|11@1+ (0.125,-128) [-128|127.875] "m" Vector__XXX
 SG_ RRR_Obj13A_Valid : 70|1@1+ (1,0) [0|1] "" Vector__XXX
 SG_ RRR_Obj13A_Vx : 71|12@1+ (0.0625,-128) [-128|127.9375] "m/s" Vector__XXX
 SG_ RRR_Obj13A_Vy : 83|10@1+ (0.125,-64) [-64|63.875] "m/s" Vector__XXX
 SG_ RRR_Obj13A_Ax : 93|10@1+ (0.03125,-16) [-16|15.96875] "m/s^2" Vector__XXX

BO_ 1323 RRR_Obj13B: 16 Vector__XXX
 SG_ RRR_Obj13B_CRC : 0|16@1+ (1,0) [0|65535] "" Vector__XXX
 SG_ RRR_Obj13B_MAC : 111|24@0+ (1,0) [0|16777215] "" Vector__XXX
 SG_ RRR_Obj13B_AliveCtr : 16|8@1+ (1,0) [0|254] "" Vector__XXX
 SG_ RRR_Obj13B_BlockCtr : 24|4@1+ (1,0) [0|15] "" Vector__XXX
 SG_ RRR_Obj13B_ProbMob4PlusWhl : 28|6@1+ (2,0) [0|100] "%" Vector__XXX
 SG_ RRR_Obj13B_ProbMob2Whl : 34|6@1+ (2,0) [0|100] "%" Vector__XXX
 SG_ RRR_Obj13B_ProbMobPed : 40|6@1+ (2,0) [0|100] "%" Vector__XXX
 SG_ RRR_Obj13B_Prob4PlusWhlCAR : 46|6@1+ (2,0) [0|100] "%" Vector__XXX
 SG_ RRR_Obj13B_Prob4PlusWhlbHGV : 52|6@1+ (2,0) [0|100] "%" Vector__XXX
 SG_ RRR_Obj13B_ProbGNDReflex : 58|6@1+ (2,0) [0|100] "%" Vector__XXX
 SG_ RRR_Obj13B_ProbStatBarrier : 64|6@1+ (2,0) [0|100] "%" Vector__XXX
 SG_ RRR_Obj13B_ProbStatObst : 70|6@1+ (2,0) [0|100] "%" Vector__XXX
 SG_ RRR_Obj13B_MovingProbability : 76|6@1+ (2,0) [0|100] "%" Vector__XXX
 SG_ RRR_Obj13B_MovingObserved : 82|6@1+ (2,0) [0|100] "%" Vector__XXX
 SG_ RRR_Obj13B_FV : 103|8@0+ (1,0) [0|255] "" Vector__XXX

BO_ 1324 RRR_Obj14A: 64 Vector__XXX
 SG_ RRR_Obj14A_CRC : 0|16@1+ (1,0) [0|65535] "" Vector__XXX
 SG_ RRR_Obj14A_Ay : 103|9@1+ (0.0625,-16) [-16|15.9375] "m/s^2" Vector__XXX
 SG_ RRR_Obj14A_HeadingYawAngle : 112|9@1+ (0.0175,-4.48) [-3.15|3.15] "rad" Vector__XXX
 SG_ RRR_Obj14A_Length : 121|7@1+ (0.125,0) [0|15.875] "m" Vector__XXX
 SG_ RRR_Obj14A_Width : 128|7@1+ (0.125,0) [0|15.875] "m" Vector__XXX
 SG_ RRR_Obj14A_Height : 135|7@1+ (0.125,0) [0|15.875] "m" Vector__XXX
 SG_ RRR_Obj14A_DxVnce : 142|12@1+ (0.01,0) [0|30] "m^2" Vector__XXX
 SG_ RRR_Obj14A_DyVnce : 154|12@1+ (0.01,0) [0|30] "m^2" Vector__XXX
 SG_ RRR_Obj14A_DzVnce : 166|10@1+ (0.01,0) [0|10] "m^2" Vector__XXX
 SG_ RRR_Obj14A_AliveCtr : 16|8@1+ (1,0) [0|254] "" Vector__XXX
 SG_ RRR_Obj14A_VxVnce : 176|12@1+ (0.01,0) [0|30] "m^2/s^2" Vector__XXX
 SG_ RRR_Obj14A_VyVnce : 188|12@1+ (0.01,0) [0|30] "m^2/s^2" Vector__XXX
 SG_ RRR_Obj14A_AxVnce : 200|12@1+ (0.01,0) [0|30] "m^2/s^4" Vector__XXX
 SG_ RRR_Obj14A_AyVnce : 212|12@1+ (0.01,0) [0|30] "m^2/s^4" Vector__XXX
 SG_ RRR_Obj14A_RefPosIndex : 224|4@1+ (1,0) [0|15] "" Vector__XXX
 SG_ RRR_Obj14A_DxDyCoVnce : 228|12@1+ (0.01,0) [0|30] "m^2" Vector__XXX
 SG_ RRR_Obj14A_DxVxCoVnce : 240|12@1+ (0.01,0) [0|30] "m^2/s" Vector__XXX
 SG_ RRR_Obj14A_BlockCtr : 24|4@1+ (1,0) [0|15] "" Vector__XXX
 SG_ RRR_Obj14A_DyVxCoVnce : 252|12@1+ (0.01,0) [0|30] "m^2/s" Vector__XXX
 SG_ RRR_Obj14A_DxVyCoVnce : 264|12@1+ (0.01,0) [0|30] "m^2/s" Vector__XXX
 SG_ RRR_Obj14A_DyVyCoVnce : 276|12@1+ (0.01,0) [0|30] "m^2/s" Vector__XXX
 SG_ RRR_Obj14A_VxVyCoVnce : 288|12@1+ (0.01,0) [0|30] "m^2/s^2" Vector__XXX
 SG_ RRR_Obj14A_DxAxCoVnce : 300|12@1+ (0.01,0) [0|30] "m^2/s^2" Vector__XXX
 SG_ RRR_Obj14A_DyAxCoVnce : 312|12@1+ (0.01,0) [0|30] "m^2/s^2" Vector__XXX
 SG_ RRR_Obj14A_VxAxCoVnce : 324|12@1+ (0.01,0) [0|30] "m^2/s^3" Vector__XXX
 SG_ RRR_Obj14A_ObjectID : 32|7@1+ (1,0) [0|127] "" Vector__XXX
 SG_ RRR_Obj14A_VyAxCoVnce : 336|12@1+ (0.01,0) [0|30] "m^2/s^3" Vector__XXX
 SG_ RRR_Obj14A_DxAyCoVnce : 348|12@1+ (0.01,0) [0|30] "m^2/s^2" Vector__XXX
 SG_ RRR_Obj14A_DyAyCoVnce : 360|12@1+ (0.01,0) [0|30] "m^2/s^2" Vector__XXX
 SG_ RRR_Obj14A_VxAyCoVnce : 372|12@1+ (0.01,0) [0|30] "m^2/s^3" Vector__XXX
 SG_ RRR_Obj14A_VyAyCoVnce : 384|12@1+ (0.01,0) [0|30] "m^2/s^3" Vector__XXX
 SG_ RRR_Obj14A_AxAyCoVnce : 396|12@1+ (0.01,0) [0|30] "m^2/s^4" Vector__XXX
 SG_ RRR_Obj14A_Measured : 39|1@1+ (1,0) [0|1] "" Vector__XXX
 SG_ RRR_Obj14A_HeadingYawVnce : 408|12@1+ (0.0003,0) [0|1] "rad^2" Vector__XXX
 SG_ RRR_Obj14A_Dx : 40|13@1+ (0.0625,-256) [-256|255.9375] "m" Vector__XXX
 SG_ RRR_Obj14A_LengthVnce : 420|12@1+ (0.01,0) [0|30] "m^2" Vector__XXX
 SG_ RRR_Obj14A_WidthVnce : 432|12@1+ (0.01,0) [0|30] "m^2" Vector__XXX
 SG_ RRR_Obj14A_HeightVnce : 444|12@1+ (0.01,0) [0|30] "m^2" Vector__XXX
 SG_ RRR_Obj14A_ExistProb : 456|6@1+ (2,0) [0|100] "%" Vector__XXX
 SG_ RRR_Obj14A_ProbObstacle : 462|6@1+ (2,0) [0|100] "%" Vector__XXX
 SG_ RRR_Obj14A_ProbNonObstacle : 468|6@1+ (2,0) [0|100] "%" Vector__XXX
 SG_ RRR_Obj14A_ProbMobileObst : 474|6@1+ (2,0) [0|100] "%" Vector__XXX
 SG_ RRR_Obj14A_FV : 487|8@0+ (1,0) [0|255] "" Vector__XXX
 SG_ RRR_Obj14A_MAC : 495|24@0+ (1,0) [0|16777215] "" Vector__XXX
 SG_ RRR_Obj14A_Dz : 53|6@1+ (0.25,-5) [-5|10.75] "m" Vector__XXX
 SG_ RRR_Obj14A_Dy : 59|11@1+ (0.125,-128) [-128|127.875] "m" Vector__XXX
 SG_ RRR_Obj14A_Valid : 70|1@1+ (1,0) [0|1] "" Vector__XXX
 SG_ RRR_Obj14A_Vx : 71|12@1+ (0.0625,-128) [-128|127.9375] "m/s" Vector__XXX
 SG_ RRR_Obj14A_Vy : 83|10@1+ (0.125,-64) [-64|63.875] "m/s" Vector__XXX
 SG_ RRR_Obj14A_Ax : 93|10@1+ (0.03125,-16) [-16|15.96875] "m/s^2" Vector__XXX

BO_ 1325 RRR_Obj14B: 16 Vector__XXX
 SG_ RRR_Obj14B_CRC : 0|16@1+ (1,0) [0|65535] "" Vector__XXX
 SG_ RRR_Obj14B_MAC : 111|24@0+ (1,0) [0|16777215] "" Vector__XXX
 SG_ RRR_Obj14B_AliveCtr : 16|8@1+ (1,0) [0|254] "" Vector__XXX
 SG_ RRR_Obj14B_BlockCtr : 24|4@1+ (1,0) [0|15] "" Vector__XXX
 SG_ RRR_Obj14B_ProbMob4PlusWhl : 28|6@1+ (2,0) [0|100] "%" Vector__XXX
 SG_ RRR_Obj14B_ProbMob2Whl : 34|6@1+ (2,0) [0|100] "%" Vector__XXX
 SG_ RRR_Obj14B_ProbMobPed : 40|6@1+ (2,0) [0|100] "%" Vector__XXX
 SG_ RRR_Obj14B_Prob4PlusWhlCAR : 46|6@1+ (2,0) [0|100] "%" Vector__XXX
 SG_ RRR_Obj14B_Prob4PlusWhlbHGV : 52|6@1+ (2,0) [0|100] "%" Vector__XXX
 SG_ RRR_Obj14B_ProbGNDReflex : 58|6@1+ (2,0) [0|100] "%" Vector__XXX
 SG_ RRR_Obj14B_ProbStatBarrier : 64|6@1+ (2,0) [0|100] "%" Vector__XXX
 SG_ RRR_Obj14B_ProbStatObst : 70|6@1+ (2,0) [0|100] "%" Vector__XXX
 SG_ RRR_Obj14B_MovingProbability : 76|6@1+ (2,0) [0|100] "%" Vector__XXX
 SG_ RRR_Obj14B_MovingObserved : 82|6@1+ (2,0) [0|100] "%" Vector__XXX
 SG_ RRR_Obj14B_FV : 103|8@0+ (1,0) [0|255] "" Vector__XXX

BO_ 1326 RRR_Obj15A: 64 Vector__XXX
 SG_ RRR_Obj15A_CRC : 0|16@1+ (1,0) [0|65535] "" Vector__XXX
 SG_ RRR_Obj15A_Ay : 103|9@1+ (0.0625,-16) [-16|15.9375] "m/s^2" Vector__XXX
 SG_ RRR_Obj15A_HeadingYawAngle : 112|9@1+ (0.0175,-4.48) [-3.15|3.15] "rad" Vector__XXX
 SG_ RRR_Obj15A_Length : 121|7@1+ (0.125,0) [0|15.875] "m" Vector__XXX
 SG_ RRR_Obj15A_Width : 128|7@1+ (0.125,0) [0|15.875] "m" Vector__XXX
 SG_ RRR_Obj15A_Height : 135|7@1+ (0.125,0) [0|15.875] "m" Vector__XXX
 SG_ RRR_Obj15A_DxVnce : 142|12@1+ (0.01,0) [0|30] "m^2" Vector__XXX
 SG_ RRR_Obj15A_DyVnce : 154|12@1+ (0.01,0) [0|30] "m^2" Vector__XXX
 SG_ RRR_Obj15A_DzVnce : 166|10@1+ (0.01,0) [0|10] "m^2" Vector__XXX
 SG_ RRR_Obj15A_AliveCtr : 16|8@1+ (1,0) [0|254] "" Vector__XXX
 SG_ RRR_Obj15A_VxVnce : 176|12@1+ (0.01,0) [0|30] "m^2/s^2" Vector__XXX
 SG_ RRR_Obj15A_VyVnce : 188|12@1+ (0.01,0) [0|30] "m^2/s^2" Vector__XXX
 SG_ RRR_Obj15A_AxVnce : 200|12@1+ (0.01,0) [0|30] "m^2/s^4" Vector__XXX
 SG_ RRR_Obj15A_AyVnce : 212|12@1+ (0.01,0) [0|30] "m^2/s^4" Vector__XXX
 SG_ RRR_Obj15A_RefPosIndex : 224|4@1+ (1,0) [0|15] "" Vector__XXX
 SG_ RRR_Obj15A_DxDyCoVnce : 228|12@1+ (0.01,0) [0|30] "m^2" Vector__XXX
 SG_ RRR_Obj15A_DxVxCoVnce : 240|12@1+ (0.01,0) [0|30] "m^2/s" Vector__XXX
 SG_ RRR_Obj15A_BlockCtr : 24|4@1+ (1,0) [0|15] "" Vector__XXX
 SG_ RRR_Obj15A_DyVxCoVnce : 252|12@1+ (0.01,0) [0|30] "m^2/s" Vector__XXX
 SG_ RRR_Obj15A_DxVyCoVnce : 264|12@1+ (0.01,0) [0|30] "m^2/s" Vector__XXX
 SG_ RRR_Obj15A_DyVyCoVnce : 276|12@1+ (0.01,0) [0|30] "m^2/s" Vector__XXX
 SG_ RRR_Obj15A_VxVyCoVnce : 288|12@1+ (0.01,0) [0|30] "m^2/s^2" Vector__XXX
 SG_ RRR_Obj15A_DxAxCoVnce : 300|12@1+ (0.01,0) [0|30] "m^2/s^2" Vector__XXX
 SG_ RRR_Obj15A_DyAxCoVnce : 312|12@1+ (0.01,0) [0|30] "m^2/s^2" Vector__XXX
 SG_ RRR_Obj15A_VxAxCoVnce : 324|12@1+ (0.01,0) [0|30] "m^2/s^3" Vector__XXX
 SG_ RRR_Obj15A_ObjectID : 32|7@1+ (1,0) [0|127] "" Vector__XXX
 SG_ RRR_Obj15A_VyAxCoVnce : 336|12@1+ (0.01,0) [0|30] "m^2/s^3" Vector__XXX
 SG_ RRR_Obj15A_DxAyCoVnce : 348|12@1+ (0.01,0) [0|30] "m^2/s^2" Vector__XXX
 SG_ RRR_Obj15A_DyAyCoVnce : 360|12@1+ (0.01,0) [0|30] "m^2/s^2" Vector__XXX
 SG_ RRR_Obj15A_VxAyCoVnce : 372|12@1+ (0.01,0) [0|30] "m^2/s^3" Vector__XXX
 SG_ RRR_Obj15A_VyAyCoVnce : 384|12@1+ (0.01,0) [0|30] "m^2/s^3" Vector__XXX
 SG_ RRR_Obj15A_AxAyCoVnce : 396|12@1+ (0.01,0) [0|30] "m^2/s^4" Vector__XXX
 SG_ RRR_Obj15A_Measured : 39|1@1+ (1,0) [0|1] "" Vector__XXX
 SG_ RRR_Obj15A_HeadingYawVnce : 408|12@1+ (0.0003,0) [0|1] "rad^2" Vector__XXX
 SG_ RRR_Obj15A_Dx : 40|13@1+ (0.0625,-256) [-256|255.9375] "m" Vector__XXX
 SG_ RRR_Obj15A_LengthVnce : 420|12@1+ (0.01,0) [0|30] "m^2" Vector__XXX
 SG_ RRR_Obj15A_WidthVnce : 432|12@1+ (0.01,0) [0|30] "m^2" Vector__XXX
 SG_ RRR_Obj15A_HeightVnce : 444|12@1+ (0.01,0) [0|30] "m^2" Vector__XXX
 SG_ RRR_Obj15A_ExistProb : 456|6@1+ (2,0) [0|100] "%" Vector__XXX
 SG_ RRR_Obj15A_ProbObstacle : 462|6@1+ (2,0) [0|100] "%" Vector__XXX
 SG_ RRR_Obj15A_ProbNonObstacle : 468|6@1+ (2,0) [0|100] "%" Vector__XXX
 SG_ RRR_Obj15A_ProbMobileObst : 474|6@1+ (2,0) [0|100] "%" Vector__XXX
 SG_ RRR_Obj15A_FV : 487|8@0+ (1,0) [0|255] "" Vector__XXX
 SG_ RRR_Obj15A_MAC : 495|24@0+ (1,0) [0|16777215] "" Vector__XXX
 SG_ RRR_Obj15A_Dz : 53|6@1+ (0.25,-5) [-5|10.75] "m" Vector__XXX
 SG_ RRR_Obj15A_Dy : 59|11@1+ (0.125,-128) [-128|127.875] "m" Vector__XXX
 SG_ RRR_Obj15A_Valid : 70|1@1+ (1,0) [0|1] "" Vector__XXX
 SG_ RRR_Obj15A_Vx : 71|12@1+ (0.0625,-128) [-128|127.9375] "m/s" Vector__XXX
 SG_ RRR_Obj15A_Vy : 83|10@1+ (0.125,-64) [-64|63.875] "m/s" Vector__XXX
 SG_ RRR_Obj15A_Ax : 93|10@1+ (0.03125,-16) [-16|15.96875] "m/s^2" Vector__XXX

BO_ 1327 RRR_Obj15B: 16 Vector__XXX
 SG_ RRR_Obj15B_CRC : 0|16@1+ (1,0) [0|65535] "" Vector__XXX
 SG_ RRR_Obj15B_MAC : 111|24@0+ (1,0) [0|16777215] "" Vector__XXX
 SG_ RRR_Obj15B_AliveCtr : 16|8@1+ (1,0) [0|254] "" Vector__XXX
 SG_ RRR_Obj15B_BlockCtr : 24|4@1+ (1,0) [0|15] "" Vector__XXX
 SG_ RRR_Obj15B_ProbMob4PlusWhl : 28|6@1+ (2,0) [0|100] "%" Vector__XXX
 SG_ RRR_Obj15B_ProbMob2Whl : 34|6@1+ (2,0) [0|100] "%" Vector__XXX
 SG_ RRR_Obj15B_ProbMobPed : 40|6@1+ (2,0) [0|100] "%" Vector__XXX
 SG_ RRR_Obj15B_Prob4PlusWhlCAR : 46|6@1+ (2,0) [0|100] "%" Vector__XXX
 SG_ RRR_Obj15B_Prob4PlusWhlbHGV : 52|6@1+ (2,0) [0|100] "%" Vector__XXX
 SG_ RRR_Obj15B_ProbGNDReflex : 58|6@1+ (2,0) [0|100] "%" Vector__XXX
 SG_ RRR_Obj15B_ProbStatBarrier : 64|6@1+ (2,0) [0|100] "%" Vector__XXX
 SG_ RRR_Obj15B_ProbStatObst : 70|6@1+ (2,0) [0|100] "%" Vector__XXX
 SG_ RRR_Obj15B_MovingProbability : 76|6@1+ (2,0) [0|100] "%" Vector__XXX
 SG_ RRR_Obj15B_MovingObserved : 82|6@1+ (2,0) [0|100] "%" Vector__XXX
 SG_ RRR_Obj15B_FV : 103|8@0+ (1,0) [0|255] "" Vector__XXX

BO_ 1328 RRR_Obj16A: 64 Vector__XXX
 SG_ RRR_Obj16A_CRC : 0|16@1+ (1,0) [0|65535] "" Vector__XXX
 SG_ RRR_Obj16A_Ay : 103|9@1+ (0.0625,-16) [-16|15.9375] "m/s^2" Vector__XXX
 SG_ RRR_Obj16A_HeadingYawAngle : 112|9@1+ (0.0175,-4.48) [-3.15|3.15] "rad" Vector__XXX
 SG_ RRR_Obj16A_Length : 121|7@1+ (0.125,0) [0|15.875] "m" Vector__XXX
 SG_ RRR_Obj16A_Width : 128|7@1+ (0.125,0) [0|15.875] "m" Vector__XXX
 SG_ RRR_Obj16A_Height : 135|7@1+ (0.125,0) [0|15.875] "m" Vector__XXX
 SG_ RRR_Obj16A_DxVnce : 142|12@1+ (0.01,0) [0|30] "m^2" Vector__XXX
 SG_ RRR_Obj16A_DyVnce : 154|12@1+ (0.01,0) [0|30] "m^2" Vector__XXX
 SG_ RRR_Obj16A_DzVnce : 166|10@1+ (0.01,0) [0|10] "m^2" Vector__XXX
 SG_ RRR_Obj16A_AliveCtr : 16|8@1+ (1,0) [0|254] "" Vector__XXX
 SG_ RRR_Obj16A_VxVnce : 176|12@1+ (0.01,0) [0|30] "m^2/s^2" Vector__XXX
 SG_ RRR_Obj16A_VyVnce : 188|12@1+ (0.01,0) [0|30] "m^2/s^2" Vector__XXX
 SG_ RRR_Obj16A_AxVnce : 200|12@1+ (0.01,0) [0|30] "m^2/s^4" Vector__XXX
 SG_ RRR_Obj16A_AyVnce : 212|12@1+ (0.01,0) [0|30] "m^2/s^4" Vector__XXX
 SG_ RRR_Obj16A_RefPosIndex : 224|4@1+ (1,0) [0|15] "" Vector__XXX
 SG_ RRR_Obj16A_DxDyCoVnce : 228|12@1+ (0.01,0) [0|30] "m^2" Vector__XXX
 SG_ RRR_Obj16A_DxVxCoVnce : 240|12@1+ (0.01,0) [0|30] "m^2/s" Vector__XXX
 SG_ RRR_Obj16A_BlockCtr : 24|4@1+ (1,0) [0|15] "" Vector__XXX
 SG_ RRR_Obj16A_DyVxCoVnce : 252|12@1+ (0.01,0) [0|30] "m^2/s" Vector__XXX
 SG_ RRR_Obj16A_DxVyCoVnce : 264|12@1+ (0.01,0) [0|30] "m^2/s" Vector__XXX
 SG_ RRR_Obj16A_DyVyCoVnce : 276|12@1+ (0.01,0) [0|30] "m^2/s" Vector__XXX
 SG_ RRR_Obj16A_VxVyCoVnce : 288|12@1+ (0.01,0) [0|30] "m^2/s^2" Vector__XXX
 SG_ RRR_Obj16A_DxAxCoVnce : 300|12@1+ (0.01,0) [0|30] "m^2/s^2" Vector__XXX
 SG_ RRR_Obj16A_DyAxCoVnce : 312|12@1+ (0.01,0) [0|30] "m^2/s^2" Vector__XXX
 SG_ RRR_Obj16A_VxAxCoVnce : 324|12@1+ (0.01,0) [0|30] "m^2/s^3" Vector__XXX
 SG_ RRR_Obj16A_ObjectID : 32|7@1+ (1,0) [0|127] "" Vector__XXX
 SG_ RRR_Obj16A_VyAxCoVnce : 336|12@1+ (0.01,0) [0|30] "m^2/s^3" Vector__XXX
 SG_ RRR_Obj16A_DxAyCoVnce : 348|12@1+ (0.01,0) [0|30] "m^2/s^2" Vector__XXX
 SG_ RRR_Obj16A_DyAyCoVnce : 360|12@1+ (0.01,0) [0|30] "m^2/s^2" Vector__XXX
 SG_ RRR_Obj16A_VxAyCoVnce : 372|12@1+ (0.01,0) [0|30] "m^2/s^3" Vector__XXX
 SG_ RRR_Obj16A_VyAyCoVnce : 384|12@1+ (0.01,0) [0|30] "m^2/s^3" Vector__XXX
 SG_ RRR_Obj16A_AxAyCoVnce : 396|12@1+ (0.01,0) [0|30] "m^2/s^4" Vector__XXX
 SG_ RRR_Obj16A_Measured : 39|1@1+ (1,0) [0|1] "" Vector__XXX
 SG_ RRR_Obj16A_HeadingYawVnce : 408|12@1+ (0.0003,0) [0|1] "rad^2" Vector__XXX
 SG_ RRR_Obj16A_Dx : 40|13@1+ (0.0625,-256) [-256|255.9375] "m" Vector__XXX
 SG_ RRR_Obj16A_LengthVnce : 420|12@1+ (0.01,0) [0|30] "m^2" Vector__XXX
 SG_ RRR_Obj16A_WidthVnce : 432|12@1+ (0.01,0) [0|30] "m^2" Vector__XXX
 SG_ RRR_Obj16A_HeightVnce : 444|12@1+ (0.01,0) [0|30] "m^2" Vector__XXX
 SG_ RRR_Obj16A_ExistProb : 456|6@1+ (2,0) [0|100] "%" Vector__XXX
 SG_ RRR_Obj16A_ProbObstacle : 462|6@1+ (2,0) [0|100] "%" Vector__XXX
 SG_ RRR_Obj16A_ProbNonObstacle : 468|6@1+ (2,0) [0|100] "%" Vector__XXX
 SG_ RRR_Obj16A_ProbMobileObst : 474|6@1+ (2,0) [0|100] "%" Vector__XXX
 SG_ RRR_Obj16A_FV : 487|8@0+ (1,0) [0|255] "" Vector__XXX
 SG_ RRR_Obj16A_MAC : 495|24@0+ (1,0) [0|16777215] "" Vector__XXX
 SG_ RRR_Obj16A_Dz : 53|6@1+ (0.25,-5) [-5|10.75] "m" Vector__XXX
 SG_ RRR_Obj16A_Dy : 59|11@1+ (0.125,-128) [-128|127.875] "m" Vector__XXX
 SG_ RRR_Obj16A_Valid : 70|1@1+ (1,0) [0|1] "" Vector__XXX
 SG_ RRR_Obj16A_Vx : 71|12@1+ (0.0625,-128) [-128|127.9375] "m/s" Vector__XXX
 SG_ RRR_Obj16A_Vy : 83|10@1+ (0.125,-64) [-64|63.875] "m/s" Vector__XXX
 SG_ RRR_Obj16A_Ax : 93|10@1+ (0.03125,-16) [-16|15.96875] "m/s^2" Vector__XXX

BO_ 1329 RRR_Obj16B: 16 Vector__XXX
 SG_ RRR_Obj16B_CRC : 0|16@1+ (1,0) [0|65535] "" Vector__XXX
 SG_ RRR_Obj16B_MAC : 111|24@0+ (1,0) [0|16777215] "" Vector__XXX
 SG_ RRR_Obj16B_AliveCtr : 16|8@1+ (1,0) [0|254] "" Vector__XXX
 SG_ RRR_Obj16B_BlockCtr : 24|4@1+ (1,0) [0|15] "" Vector__XXX
 SG_ RRR_Obj16B_ProbMob4PlusWhl : 28|6@1+ (2,0) [0|100] "%" Vector__XXX
 SG_ RRR_Obj16B_ProbMob2Whl : 34|6@1+ (2,0) [0|100] "%" Vector__XXX
 SG_ RRR_Obj16B_ProbMobPed : 40|6@1+ (2,0) [0|100] "%" Vector__XXX
 SG_ RRR_Obj16B_Prob4PlusWhlCAR : 46|6@1+ (2,0) [0|100] "%" Vector__XXX
 SG_ RRR_Obj16B_Prob4PlusWhlbHGV : 52|6@1+ (2,0) [0|100] "%" Vector__XXX
 SG_ RRR_Obj16B_ProbGNDReflex : 58|6@1+ (2,0) [0|100] "%" Vector__XXX
 SG_ RRR_Obj16B_ProbStatBarrier : 64|6@1+ (2,0) [0|100] "%" Vector__XXX
 SG_ RRR_Obj16B_ProbStatObst : 70|6@1+ (2,0) [0|100] "%" Vector__XXX
 SG_ RRR_Obj16B_MovingProbability : 76|6@1+ (2,0) [0|100] "%" Vector__XXX
 SG_ RRR_Obj16B_MovingObserved : 82|6@1+ (2,0) [0|100] "%" Vector__XXX
 SG_ RRR_Obj16B_FV : 103|8@0+ (1,0) [0|255] "" Vector__XXX

BO_ 1330 RRR_Obj17A: 64 Vector__XXX
 SG_ RRR_Obj17A_CRC : 0|16@1+ (1,0) [0|65535] "" Vector__XXX
 SG_ RRR_Obj17A_Ay : 103|9@1+ (0.0625,-16) [-16|15.9375] "m/s^2" Vector__XXX
 SG_ RRR_Obj17A_HeadingYawAngle : 112|9@1+ (0.0175,-4.48) [-3.15|3.15] "rad" Vector__XXX
 SG_ RRR_Obj17A_Length : 121|7@1+ (0.125,0) [0|15.875] "m" Vector__XXX
 SG_ RRR_Obj17A_Width : 128|7@1+ (0.125,0) [0|15.875] "m" Vector__XXX
 SG_ RRR_Obj17A_Height : 135|7@1+ (0.125,0) [0|15.875] "m" Vector__XXX
 SG_ RRR_Obj17A_DxVnce : 142|12@1+ (0.01,0) [0|30] "m^2" Vector__XXX
 SG_ RRR_Obj17A_DyVnce : 154|12@1+ (0.01,0) [0|30] "m^2" Vector__XXX
 SG_ RRR_Obj17A_DzVnce : 166|10@1+ (0.01,0) [0|10] "m^2" Vector__XXX
 SG_ RRR_Obj17A_AliveCtr : 16|8@1+ (1,0) [0|254] "" Vector__XXX
 SG_ RRR_Obj17A_VxVnce : 176|12@1+ (0.01,0) [0|30] "m^2/s^2" Vector__XXX
 SG_ RRR_Obj17A_VyVnce : 188|12@1+ (0.01,0) [0|30] "m^2/s^2" Vector__XXX
 SG_ RRR_Obj17A_AxVnce : 200|12@1+ (0.01,0) [0|30] "m^2/s^4" Vector__XXX
 SG_ RRR_Obj17A_AyVnce : 212|12@1+ (0.01,0) [0|30] "m^2/s^4" Vector__XXX
 SG_ RRR_Obj17A_RefPosIndex : 224|4@1+ (1,0) [0|15] "" Vector__XXX
 SG_ RRR_Obj17A_DxDyCoVnce : 228|12@1+ (0.01,0) [0|30] "m^2" Vector__XXX
 SG_ RRR_Obj17A_DxVxCoVnce : 240|12@1+ (0.01,0) [0|30] "m^2/s" Vector__XXX
 SG_ RRR_Obj17A_BlockCtr : 24|4@1+ (1,0) [0|15] "" Vector__XXX
 SG_ RRR_Obj17A_DyVxCoVnce : 252|12@1+ (0.01,0) [0|30] "m^2/s" Vector__XXX
 SG_ RRR_Obj17A_DxVyCoVnce : 264|12@1+ (0.01,0) [0|30] "m^2/s" Vector__XXX
 SG_ RRR_Obj17A_DyVyCoVnce : 276|12@1+ (0.01,0) [0|30] "m^2/s" Vector__XXX
 SG_ RRR_Obj17A_VxVyCoVnce : 288|12@1+ (0.01,0) [0|30] "m^2/s^2" Vector__XXX
 SG_ RRR_Obj17A_DxAxCoVnce : 300|12@1+ (0.01,0) [0|30] "m^2/s^2" Vector__XXX
 SG_ RRR_Obj17A_DyAxCoVnce : 312|12@1+ (0.01,0) [0|30] "m^2/s^2" Vector__XXX
 SG_ RRR_Obj17A_VxAxCoVnce : 324|12@1+ (0.01,0) [0|30] "m^2/s^3" Vector__XXX
 SG_ RRR_Obj17A_ObjectID : 32|7@1+ (1,0) [0|127] "" Vector__XXX
 SG_ RRR_Obj17A_VyAxCoVnce : 336|12@1+ (0.01,0) [0|30] "m^2/s^3" Vector__XXX
 SG_ RRR_Obj17A_DxAyCoVnce : 348|12@1+ (0.01,0) [0|30] "m^2/s^2" Vector__XXX
 SG_ RRR_Obj17A_DyAyCoVnce : 360|12@1+ (0.01,0) [0|30] "m^2/s^2" Vector__XXX
 SG_ RRR_Obj17A_VxAyCoVnce : 372|12@1+ (0.01,0) [0|30] "m^2/s^3" Vector__XXX
 SG_ RRR_Obj17A_VyAyCoVnce : 384|12@1+ (0.01,0) [0|30] "m^2/s^3" Vector__XXX
 SG_ RRR_Obj17A_AxAyCoVnce : 396|12@1+ (0.01,0) [0|30] "m^2/s^4" Vector__XXX
 SG_ RRR_Obj17A_Measured : 39|1@1+ (1,0) [0|1] "" Vector__XXX
 SG_ RRR_Obj17A_HeadingYawVnce : 408|12@1+ (0.0003,0) [0|1] "rad^2" Vector__XXX
 SG_ RRR_Obj17A_Dx : 40|13@1+ (0.0625,-256) [-256|255.9375] "m" Vector__XXX
 SG_ RRR_Obj17A_LengthVnce : 420|12@1+ (0.01,0) [0|30] "m^2" Vector__XXX
 SG_ RRR_Obj17A_WidthVnce : 432|12@1+ (0.01,0) [0|30] "m^2" Vector__XXX
 SG_ RRR_Obj17A_HeightVnce : 444|12@1+ (0.01,0) [0|30] "m^2" Vector__XXX
 SG_ RRR_Obj17A_ExistProb : 456|6@1+ (2,0) [0|100] "%" Vector__XXX
 SG_ RRR_Obj17A_ProbObstacle : 462|6@1+ (2,0) [0|100] "%" Vector__XXX
 SG_ RRR_Obj17A_ProbNonObstacle : 468|6@1+ (2,0) [0|100] "%" Vector__XXX
 SG_ RRR_Obj17A_ProbMobileObst : 474|6@1+ (2,0) [0|100] "%" Vector__XXX
 SG_ RRR_Obj17A_FV : 487|8@0+ (1,0) [0|255] "" Vector__XXX
 SG_ RRR_Obj17A_MAC : 495|24@0+ (1,0) [0|16777215] "" Vector__XXX
 SG_ RRR_Obj17A_Dz : 53|6@1+ (0.25,-5) [-5|10.75] "m" Vector__XXX
 SG_ RRR_Obj17A_Dy : 59|11@1+ (0.125,-128) [-128|127.875] "m" Vector__XXX
 SG_ RRR_Obj17A_Valid : 70|1@1+ (1,0) [0|1] "" Vector__XXX
 SG_ RRR_Obj17A_Vx : 71|12@1+ (0.0625,-128) [-128|127.9375] "m/s" Vector__XXX
 SG_ RRR_Obj17A_Vy : 83|10@1+ (0.125,-64) [-64|63.875] "m/s" Vector__XXX
 SG_ RRR_Obj17A_Ax : 93|10@1+ (0.03125,-16) [-16|15.96875] "m/s^2" Vector__XXX

BO_ 1331 RRR_Obj17B: 16 Vector__XXX
 SG_ RRR_Obj17B_CRC : 0|16@1+ (1,0) [0|65535] "" Vector__XXX
 SG_ RRR_Obj17B_MAC : 111|24@0+ (1,0) [0|16777215] "" Vector__XXX
 SG_ RRR_Obj17B_AliveCtr : 16|8@1+ (1,0) [0|254] "" Vector__XXX
 SG_ RRR_Obj17B_BlockCtr : 24|4@1+ (1,0) [0|15] "" Vector__XXX
 SG_ RRR_Obj17B_ProbMob4PlusWhl : 28|6@1+ (2,0) [0|100] "%" Vector__XXX
 SG_ RRR_Obj17B_ProbMob2Whl : 34|6@1+ (2,0) [0|100] "%" Vector__XXX
 SG_ RRR_Obj17B_ProbMobPed : 40|6@1+ (2,0) [0|100] "%" Vector__XXX
 SG_ RRR_Obj17B_Prob4PlusWhlCAR : 46|6@1+ (2,0) [0|100] "%" Vector__XXX
 SG_ RRR_Obj17B_Prob4PlusWhlbHGV : 52|6@1+ (2,0) [0|100] "%" Vector__XXX
 SG_ RRR_Obj17B_ProbGNDReflex : 58|6@1+ (2,0) [0|100] "%" Vector__XXX
 SG_ RRR_Obj17B_ProbStatBarrier : 64|6@1+ (2,0) [0|100] "%" Vector__XXX
 SG_ RRR_Obj17B_ProbStatObst : 70|6@1+ (2,0) [0|100] "%" Vector__XXX
 SG_ RRR_Obj17B_MovingProbability : 76|6@1+ (2,0) [0|100] "%" Vector__XXX
 SG_ RRR_Obj17B_MovingObserved : 82|6@1+ (2,0) [0|100] "%" Vector__XXX
 SG_ RRR_Obj17B_FV : 103|8@0+ (1,0) [0|255] "" Vector__XXX

BO_ 1332 RRR_Obj18A: 64 Vector__XXX
 SG_ RRR_Obj18A_CRC : 0|16@1+ (1,0) [0|65535] "" Vector__XXX
 SG_ RRR_Obj18A_Ay : 103|9@1+ (0.0625,-16) [-16|15.9375] "m/s^2" Vector__XXX
 SG_ RRR_Obj18A_HeadingYawAngle : 112|9@1+ (0.0175,-4.48) [-3.15|3.15] "rad" Vector__XXX
 SG_ RRR_Obj18A_Length : 121|7@1+ (0.125,0) [0|15.875] "m" Vector__XXX
 SG_ RRR_Obj18A_Width : 128|7@1+ (0.125,0) [0|15.875] "m" Vector__XXX
 SG_ RRR_Obj18A_Height : 135|7@1+ (0.125,0) [0|15.875] "m" Vector__XXX
 SG_ RRR_Obj18A_DxVnce : 142|12@1+ (0.01,0) [0|30] "m^2" Vector__XXX
 SG_ RRR_Obj18A_DyVnce : 154|12@1+ (0.01,0) [0|30] "m^2" Vector__XXX
 SG_ RRR_Obj18A_DzVnce : 166|10@1+ (0.01,0) [0|10] "m^2" Vector__XXX
 SG_ RRR_Obj18A_AliveCtr : 16|8@1+ (1,0) [0|254] "" Vector__XXX
 SG_ RRR_Obj18A_VxVnce : 176|12@1+ (0.01,0) [0|30] "m^2/s^2" Vector__XXX
 SG_ RRR_Obj18A_VyVnce : 188|12@1+ (0.01,0) [0|30] "m^2/s^2" Vector__XXX
 SG_ RRR_Obj18A_AxVnce : 200|12@1+ (0.01,0) [0|30] "m^2/s^4" Vector__XXX
 SG_ RRR_Obj18A_AyVnce : 212|12@1+ (0.01,0) [0|30] "m^2/s^4" Vector__XXX
 SG_ RRR_Obj18A_RefPosIndex : 224|4@1+ (1,0) [0|15] "" Vector__XXX
 SG_ RRR_Obj18A_DxDyCoVnce : 228|12@1+ (0.01,0) [0|30] "m^2" Vector__XXX
 SG_ RRR_Obj18A_DxVxCoVnce : 240|12@1+ (0.01,0) [0|30] "m^2/s" Vector__XXX
 SG_ RRR_Obj18A_BlockCtr : 24|4@1+ (1,0) [0|15] "" Vector__XXX
 SG_ RRR_Obj18A_DyVxCoVnce : 252|12@1+ (0.01,0) [0|30] "m^2/s" Vector__XXX
 SG_ RRR_Obj18A_DxVyCoVnce : 264|12@1+ (0.01,0) [0|30] "m^2/s" Vector__XXX
 SG_ RRR_Obj18A_DyVyCoVnce : 276|12@1+ (0.01,0) [0|30] "m^2/s" Vector__XXX
 SG_ RRR_Obj18A_VxVyCoVnce : 288|12@1+ (0.01,0) [0|30] "m^2/s^2" Vector__XXX
 SG_ RRR_Obj18A_DxAxCoVnce : 300|12@1+ (0.01,0) [0|30] "m^2/s^2" Vector__XXX
 SG_ RRR_Obj18A_DyAxCoVnce : 312|12@1+ (0.01,0) [0|30] "m^2/s^2" Vector__XXX
 SG_ RRR_Obj18A_VxAxCoVnce : 324|12@1+ (0.01,0) [0|30] "m^2/s^3" Vector__XXX
 SG_ RRR_Obj18A_ObjectID : 32|7@1+ (1,0) [0|127] "" Vector__XXX
 SG_ RRR_Obj18A_VyAxCoVnce : 336|12@1+ (0.01,0) [0|30] "m^2/s^3" Vector__XXX
 SG_ RRR_Obj18A_DxAyCoVnce : 348|12@1+ (0.01,0) [0|30] "m^2/s^2" Vector__XXX
 SG_ RRR_Obj18A_DyAyCoVnce : 360|12@1+ (0.01,0) [0|30] "m^2/s^2" Vector__XXX
 SG_ RRR_Obj18A_VxAyCoVnce : 372|12@1+ (0.01,0) [0|30] "m^2/s^3" Vector__XXX
 SG_ RRR_Obj18A_VyAyCoVnce : 384|12@1+ (0.01,0) [0|30] "m^2/s^3" Vector__XXX
 SG_ RRR_Obj18A_AxAyCoVnce : 396|12@1+ (0.01,0) [0|30] "m^2/s^4" Vector__XXX
 SG_ RRR_Obj18A_Measured : 39|1@1+ (1,0) [0|1] "" Vector__XXX
 SG_ RRR_Obj18A_HeadingYawVnce : 408|12@1+ (0.0003,0) [0|1] "rad^2" Vector__XXX
 SG_ RRR_Obj18A_Dx : 40|13@1+ (0.0625,-256) [-256|255.9375] "m" Vector__XXX
 SG_ RRR_Obj18A_LengthVnce : 420|12@1+ (0.01,0) [0|30] "m^2" Vector__XXX
 SG_ RRR_Obj18A_WidthVnce : 432|12@1+ (0.01,0) [0|30] "m^2" Vector__XXX
 SG_ RRR_Obj18A_HeightVnce : 444|12@1+ (0.01,0) [0|30] "m^2" Vector__XXX
 SG_ RRR_Obj18A_ExistProb : 456|6@1+ (2,0) [0|100] "%" Vector__XXX
 SG_ RRR_Obj18A_ProbObstacle : 462|6@1+ (2,0) [0|100] "%" Vector__XXX
 SG_ RRR_Obj18A_ProbNonObstacle : 468|6@1+ (2,0) [0|100] "%" Vector__XXX
 SG_ RRR_Obj18A_ProbMobileObst : 474|6@1+ (2,0) [0|100] "%" Vector__XXX
 SG_ RRR_Obj18A_FV : 487|8@0+ (1,0) [0|255] "" Vector__XXX
 SG_ RRR_Obj18A_MAC : 495|24@0+ (1,0) [0|16777215] "" Vector__XXX
 SG_ RRR_Obj18A_Dz : 53|6@1+ (0.25,-5) [-5|10.75] "m" Vector__XXX
 SG_ RRR_Obj18A_Dy : 59|11@1+ (0.125,-128) [-128|127.875] "m" Vector__XXX
 SG_ RRR_Obj18A_Valid : 70|1@1+ (1,0) [0|1] "" Vector__XXX
 SG_ RRR_Obj18A_Vx : 71|12@1+ (0.0625,-128) [-128|127.9375] "m/s" Vector__XXX
 SG_ RRR_Obj18A_Vy : 83|10@1+ (0.125,-64) [-64|63.875] "m/s" Vector__XXX
 SG_ RRR_Obj18A_Ax : 93|10@1+ (0.03125,-16) [-16|15.96875] "m/s^2" Vector__XXX

BO_ 1333 RRR_Obj18B: 16 Vector__XXX
 SG_ RRR_Obj18B_CRC : 0|16@1+ (1,0) [0|65535] "" Vector__XXX
 SG_ RRR_Obj18B_MAC : 111|24@0+ (1,0) [0|16777215] "" Vector__XXX
 SG_ RRR_Obj18B_AliveCtr : 16|8@1+ (1,0) [0|254] "" Vector__XXX
 SG_ RRR_Obj18B_BlockCtr : 24|4@1+ (1,0) [0|15] "" Vector__XXX
 SG_ RRR_Obj18B_ProbMob4PlusWhl : 28|6@1+ (2,0) [0|100] "%" Vector__XXX
 SG_ RRR_Obj18B_ProbMob2Whl : 34|6@1+ (2,0) [0|100] "%" Vector__XXX
 SG_ RRR_Obj18B_ProbMobPed : 40|6@1+ (2,0) [0|100] "%" Vector__XXX
 SG_ RRR_Obj18B_Prob4PlusWhlCAR : 46|6@1+ (2,0) [0|100] "%" Vector__XXX
 SG_ RRR_Obj18B_Prob4PlusWhlbHGV : 52|6@1+ (2,0) [0|100] "%" Vector__XXX
 SG_ RRR_Obj18B_ProbGNDReflex : 58|6@1+ (2,0) [0|100] "%" Vector__XXX
 SG_ RRR_Obj18B_ProbStatBarrier : 64|6@1+ (2,0) [0|100] "%" Vector__XXX
 SG_ RRR_Obj18B_ProbStatObst : 70|6@1+ (2,0) [0|100] "%" Vector__XXX
 SG_ RRR_Obj18B_MovingProbability : 76|6@1+ (2,0) [0|100] "%" Vector__XXX
 SG_ RRR_Obj18B_MovingObserved : 82|6@1+ (2,0) [0|100] "%" Vector__XXX
 SG_ RRR_Obj18B_FV : 103|8@0+ (1,0) [0|255] "" Vector__XXX

BO_ 1334 RRR_Obj19A: 64 Vector__XXX
 SG_ RRR_Obj19A_CRC : 0|16@1+ (1,0) [0|65535] "" Vector__XXX
 SG_ RRR_Obj19A_Ay : 103|9@1+ (0.0625,-16) [-16|15.9375] "m/s^2" Vector__XXX
 SG_ RRR_Obj19A_HeadingYawAngle : 112|9@1+ (0.0175,-4.48) [-3.15|3.15] "rad" Vector__XXX
 SG_ RRR_Obj19A_Length : 121|7@1+ (0.125,0) [0|15.875] "m" Vector__XXX
 SG_ RRR_Obj19A_Width : 128|7@1+ (0.125,0) [0|15.875] "m" Vector__XXX
 SG_ RRR_Obj19A_Height : 135|7@1+ (0.125,0) [0|15.875] "m" Vector__XXX
 SG_ RRR_Obj19A_DxVnce : 142|12@1+ (0.01,0) [0|30] "m^2" Vector__XXX
 SG_ RRR_Obj19A_DyVnce : 154|12@1+ (0.01,0) [0|30] "m^2" Vector__XXX
 SG_ RRR_Obj19A_DzVnce : 166|10@1+ (0.01,0) [0|10] "m^2" Vector__XXX
 SG_ RRR_Obj19A_AliveCtr : 16|8@1+ (1,0) [0|254] "" Vector__XXX
 SG_ RRR_Obj19A_VxVnce : 176|12@1+ (0.01,0) [0|30] "m^2/s^2" Vector__XXX
 SG_ RRR_Obj19A_VyVnce : 188|12@1+ (0.01,0) [0|30] "m^2/s^2" Vector__XXX
 SG_ RRR_Obj19A_AxVnce : 200|12@1+ (0.01,0) [0|30] "m^2/s^4" Vector__XXX
 SG_ RRR_Obj19A_AyVnce : 212|12@1+ (0.01,0) [0|30] "m^2/s^4" Vector__XXX
 SG_ RRR_Obj19A_RefPosIndex : 224|4@1+ (1,0) [0|15] "" Vector__XXX
 SG_ RRR_Obj19A_DxDyCoVnce : 228|12@1+ (0.01,0) [0|30] "m^2" Vector__XXX
 SG_ RRR_Obj19A_DxVxCoVnce : 240|12@1+ (0.01,0) [0|30] "m^2/s" Vector__XXX
 SG_ RRR_Obj19A_BlockCtr : 24|4@1+ (1,0) [0|15] "" Vector__XXX
 SG_ RRR_Obj19A_DyVxCoVnce : 252|12@1+ (0.01,0) [0|30] "m^2/s" Vector__XXX
 SG_ RRR_Obj19A_DxVyCoVnce : 264|12@1+ (0.01,0) [0|30] "m^2/s" Vector__XXX
 SG_ RRR_Obj19A_DyVyCoVnce : 276|12@1+ (0.01,0) [0|30] "m^2/s" Vector__XXX
 SG_ RRR_Obj19A_VxVyCoVnce : 288|12@1+ (0.01,0) [0|30] "m^2/s^2" Vector__XXX
 SG_ RRR_Obj19A_DxAxCoVnce : 300|12@1+ (0.01,0) [0|30] "m^2/s^2" Vector__XXX
 SG_ RRR_Obj19A_DyAxCoVnce : 312|12@1+ (0.01,0) [0|30] "m^2/s^2" Vector__XXX
 SG_ RRR_Obj19A_VxAxCoVnce : 324|12@1+ (0.01,0) [0|30] "m^2/s^3" Vector__XXX
 SG_ RRR_Obj19A_ObjectID : 32|7@1+ (1,0) [0|127] "" Vector__XXX
 SG_ RRR_Obj19A_VyAxCoVnce : 336|12@1+ (0.01,0) [0|30] "m^2/s^3" Vector__XXX
 SG_ RRR_Obj19A_DxAyCoVnce : 348|12@1+ (0.01,0) [0|30] "m^2/s^2" Vector__XXX
 SG_ RRR_Obj19A_DyAyCoVnce : 360|12@1+ (0.01,0) [0|30] "m^2/s^2" Vector__XXX
 SG_ RRR_Obj19A_VxAyCoVnce : 372|12@1+ (0.01,0) [0|30] "m^2/s^3" Vector__XXX
 SG_ RRR_Obj19A_VyAyCoVnce : 384|12@1+ (0.01,0) [0|30] "m^2/s^3" Vector__XXX
 SG_ RRR_Obj19A_AxAyCoVnce : 396|12@1+ (0.01,0) [0|30] "m^2/s^4" Vector__XXX
 SG_ RRR_Obj19A_Measured : 39|1@1+ (1,0) [0|1] "" Vector__XXX
 SG_ RRR_Obj19A_HeadingYawVnce : 408|12@1+ (0.0003,0) [0|1] "rad^2" Vector__XXX
 SG_ RRR_Obj19A_Dx : 40|13@1+ (0.0625,-256) [-256|255.9375] "m" Vector__XXX
 SG_ RRR_Obj19A_LengthVnce : 420|12@1+ (0.01,0) [0|30] "m^2" Vector__XXX
 SG_ RRR_Obj19A_WidthVnce : 432|12@1+ (0.01,0) [0|30] "m^2" Vector__XXX
 SG_ RRR_Obj19A_HeightVnce : 444|12@1+ (0.01,0) [0|30] "m^2" Vector__XXX
 SG_ RRR_Obj19A_ExistProb : 456|6@1+ (2,0) [0|100] "%" Vector__XXX
 SG_ RRR_Obj19A_ProbObstacle : 462|6@1+ (2,0) [0|100] "%" Vector__XXX
 SG_ RRR_Obj19A_ProbNonObstacle : 468|6@1+ (2,0) [0|100] "%" Vector__XXX
 SG_ RRR_Obj19A_ProbMobileObst : 474|6@1+ (2,0) [0|100] "%" Vector__XXX
 SG_ RRR_Obj19A_FV : 487|8@0+ (1,0) [0|255] "" Vector__XXX
 SG_ RRR_Obj19A_MAC : 495|24@0+ (1,0) [0|16777215] "" Vector__XXX
 SG_ RRR_Obj19A_Dz : 53|6@1+ (0.25,-5) [-5|10.75] "m" Vector__XXX
 SG_ RRR_Obj19A_Dy : 59|11@1+ (0.125,-128) [-128|127.875] "m" Vector__XXX
 SG_ RRR_Obj19A_Valid : 70|1@1+ (1,0) [0|1] "" Vector__XXX
 SG_ RRR_Obj19A_Vx : 71|12@1+ (0.0625,-128) [-128|127.9375] "m/s" Vector__XXX
 SG_ RRR_Obj19A_Vy : 83|10@1+ (0.125,-64) [-64|63.875] "m/s" Vector__XXX
 SG_ RRR_Obj19A_Ax : 93|10@1+ (0.03125,-16) [-16|15.96875] "m/s^2" Vector__XXX

BO_ 1335 RRR_Obj19B: 16 Vector__XXX
 SG_ RRR_Obj19B_CRC : 0|16@1+ (1,0) [0|65535] "" Vector__XXX
 SG_ RRR_Obj19B_MAC : 111|24@0+ (1,0) [0|16777215] "" Vector__XXX
 SG_ RRR_Obj19B_AliveCtr : 16|8@1+ (1,0) [0|254] "" Vector__XXX
 SG_ RRR_Obj19B_BlockCtr : 24|4@1+ (1,0) [0|15] "" Vector__XXX
 SG_ RRR_Obj19B_ProbMob4PlusWhl : 28|6@1+ (2,0) [0|100] "%" Vector__XXX
 SG_ RRR_Obj19B_ProbMob2Whl : 34|6@1+ (2,0) [0|100] "%" Vector__XXX
 SG_ RRR_Obj19B_ProbMobPed : 40|6@1+ (2,0) [0|100] "%" Vector__XXX
 SG_ RRR_Obj19B_Prob4PlusWhlCAR : 46|6@1+ (2,0) [0|100] "%" Vector__XXX
 SG_ RRR_Obj19B_Prob4PlusWhlbHGV : 52|6@1+ (2,0) [0|100] "%" Vector__XXX
 SG_ RRR_Obj19B_ProbGNDReflex : 58|6@1+ (2,0) [0|100] "%" Vector__XXX
 SG_ RRR_Obj19B_ProbStatBarrier : 64|6@1+ (2,0) [0|100] "%" Vector__XXX
 SG_ RRR_Obj19B_ProbStatObst : 70|6@1+ (2,0) [0|100] "%" Vector__XXX
 SG_ RRR_Obj19B_MovingProbability : 76|6@1+ (2,0) [0|100] "%" Vector__XXX
 SG_ RRR_Obj19B_MovingObserved : 82|6@1+ (2,0) [0|100] "%" Vector__XXX
 SG_ RRR_Obj19B_FV : 103|8@0+ (1,0) [0|255] "" Vector__XXX

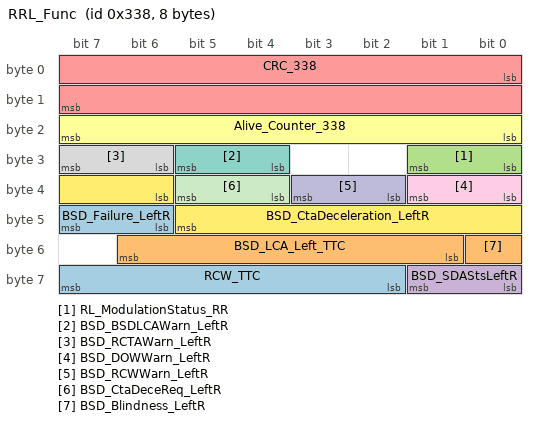
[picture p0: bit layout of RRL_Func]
BO_ 824 RRL_Func: 8 RadarRearLeft
 SG_ RCW_TTC : 58|6@1+ (0.1,0) [0|6.3] "s"  RadarRearRight
 SG_ BSD_LCA_Left_TTC : 49|6@1+ (0.1,0) [0|6.3] "s"  RadarRearRight
 SG_ RL_ModulationStatus_RR : 24|2@1+ (1,0) [0|3] ""  RadarRearRight
 SG_ BSD_SDAStsLeftR : 56|2@1+ (1,0) [0|3] ""  RadarRearRight
 SG_ CRC_338 : 0|16@1+ (1,0) [0|65535] ""  RadarRearRight
 SG_ Alive_Counter_338 : 16|8@1+ (1,0) [0|254] ""  RadarRearRight
 SG_ BSD_BSDLCAWarn_LeftR : 28|2@1+ (1,0) [0|3] ""  RadarRearRight
 SG_ BSD_RCTAWarn_LeftR : 30|2@1+ (1,0) [0|3] ""  RadarRearRight
 SG_ BSD_DOWWarn_LeftR : 32|2@1+ (1,0) [0|3] ""  RadarRearRight
 SG_ BSD_RCWWarn_LeftR : 34|2@1+ (1,0) [0|3] ""  RadarRearRight
 SG_ BSD_CtaDeceReq_LeftR : 36|2@1+ (1,0) [0|3] ""  RadarRearRight
 SG_ BSD_CtaDeceleration_LeftR : 38|8@1+ (0.05,-10) [-10|2.75] "m/s^2"  RadarRearRight
 SG_ BSD_Failure_LeftR : 46|2@1+ (1,0) [0|3] ""  RadarRearRight
 SG_ BSD_Blindness_LeftR : 48|1@1+ (1,0) [0|1] ""  RadarRearRight

BO_ 1336 RRR_Func: 16 RadarRearRight
 SG_ BSD_SDAStsRightL : 24|2@1+ (1,0) [0|3] ""  RadarRearLeft
 SG_ CRC_538 : 0|16@1+ (1,0) [0|65535] ""  RadarRearLeft
 SG_ Alive_Counter_538 : 16|8@1+ (1,0) [0|254] ""  RadarRearLeft
 SG_ BSD_LcaSwitch_RightL : 28|1@1+ (1,0) [0|1] ""  RadarRearLeft
 SG_ BSD_CtaSwitch_RightL : 29|1@1+ (1,0) [0|1] ""  RadarRearLeft
 SG_ BSD_DowSwitch_RightL : 30|1@1+ (1,0) [0|1] ""  RadarRearLeft
 SG_ BSD_RcwSwitch_RightL : 31|1@1+ (1,0) [0|1] ""  RadarRearLeft
 SG_ BSD_CtaBrakeSwitch_RightL : 32|1@1+ (1,0) [0|1] ""  RadarRearLeft
 SG_ BSD_Failure_RightL : 33|2@1+ (1,0) [0|3] ""  RadarRearLeft
 SG_ BSD_Blindness_RightL : 35|1@1+ (1,0) [0|1] ""  RadarRearLeft

CM_ SG_ 1310 RRR_Obj07A_CRC "CRC - Autosar E2E Profile 5";
CM_ SG_ 1310 RRR_Obj07A_Ay "Object acceleration in Y direction";
CM_ SG_ 1310 RRR_Obj07A_HeadingYawAngle "Object heading yaw angle";
CM_ SG_ 1310 RRR_Obj07A_Length "Object Length";
CM_ SG_ 1310 RRR_Obj07A_Width "Object Width";
CM_ SG_ 1310 RRR_Obj07A_Height "Object Height";
CM_ SG_ 1310 RRR_Obj07A_DxVnce "Variance of object position in X direction";
CM_ SG_ 1310 RRR_Obj07A_DyVnce "Variance of object position in Y direction";
CM_ SG_ 1310 RRR_Obj07A_DzVnce "Variance of object position in Z direction";
CM_ SG_ 1310 RRR_Obj07A_AliveCtr "Alive counter - Autosar E2E Profile 5";
CM_ SG_ 1310 RRR_Obj07A_VxVnce "Variance of object velocity in X direction";
CM_ SG_ 1310 RRR_Obj07A_VyVnce "Variance of object velocity in Y direction";
CM_ SG_ 1310 RRR_Obj07A_AxVnce "Variance of object acceleration in X direction";
CM_ SG_ 1310 RRR_Obj07A_AyVnce "Variance of object acceleration in Y direction";
CM_ SG_ 1310 RRR_Obj07A_RefPosIndex "Reference Position of the detected objects";
CM_ SG_ 1310 RRR_Obj07A_DxDyCoVnce "Correlation coefficient of Dx and Dy";
CM_ SG_ 1310 RRR_Obj07A_DxVxCoVnce "Correlation coefficient of Dx and Vx";
CM_ SG_ 1310 RRR_Obj07A_BlockCtr "Block-Counter";
CM_ SG_ 1310 RRR_Obj07A_DyVxCoVnce "Correlation coefficient of Dy and Ax";
CM_ SG_ 1310 RRR_Obj07A_DxVyCoVnce "Correlation coefficient of Dx and Vy";
CM_ SG_ 1310 RRR_Obj07A_DyVyCoVnce "Correlation coefficient of Dy and Vy";
CM_ SG_ 1310 RRR_Obj07A_VxVyCoVnce "Correlation coefficient of Vx and Vy";
CM_ SG_ 1310 RRR_Obj07A_DxAxCoVnce "Correlation coefficient of Dx and Ax";
CM_ SG_ 1310 RRR_Obj07A_DyAxCoVnce "Correlation coefficient of Dy and Ax";
CM_ SG_ 1310 RRR_Obj07A_VxAxCoVnce "Correlation coefficient of Vx and Ax";
CM_ SG_ 1310 RRR_Obj07A_ObjectID "Unique Object ID";
CM_ SG_ 1310 RRR_Obj07A_VyAxCoVnce "Correlation coefficient of Vy and Ax";
CM_ SG_ 1310 RRR_Obj07A_DxAyCoVnce "Correlation coefficient of Dx and Ay";
CM_ SG_ 1310 RRR_Obj07A_DyAyCoVnce "Correlation coefficient of Dy and Ay";
CM_ SG_ 1310 RRR_Obj07A_VxAyCoVnce "Correlation coefficient of Vx and Ay";
CM_ SG_ 1310 RRR_Obj07A_VyAyCoVnce "Correlation coefficient of Vy and Ay";
CM_ SG_ 1310 RRR_Obj07A_AxAyCoVnce "Correlation coefficient of Ax and Ay";
CM_ SG_ 1310 RRR_Obj07A_Measured "Object is measured or not";
CM_ SG_ 1310 RRR_Obj07A_HeadingYawVnce "Variance of Object heading yaw angle";
CM_ SG_ 1310 RRR_Obj07A_Dx "Object position in X direction";
CM_ SG_ 1310 RRR_Obj07A_LengthVnce "Variance of Object Length";
CM_ SG_ 1310 RRR_Obj07A_WidthVnce "Variance of Object Width";
CM_ SG_ 1310 RRR_Obj07A_HeightVnce "Variance of Object Height";
CM_ SG_ 1310 RRR_Obj07A_ExistProb "Existence probability of object";
CM_ SG_ 1310 RRR_Obj07A_ProbObstacle "Probability of the object being an Obstacle";
CM_ SG_ 1310 RRR_Obj07A_ProbNonObstacle "Probability of the object being a Non-Obstacle";
CM_ SG_ 1310 RRR_Obj07A_ProbMobileObst "Probability of the object being a mobile obstacle";
CM_ SG_ 1310 RRR_Obj07A_FV "SecOC Freshness Value (Profile 1)";
CM_ SG_ 1310 RRR_Obj07A_MAC "SecOC MAC (Profile 1)";
CM_ SG_ 1310 RRR_Obj07A_Dz "Object position in Z direction";
CM_ SG_ 1310 RRR_Obj07A_Dy "Object position in Y direction";
CM_ SG_ 1310 RRR_Obj07A_Valid "Object is valid or not";
CM_ SG_ 1310 RRR_Obj07A_Vx "Object velocity in X direction";
CM_ SG_ 1310 RRR_Obj07A_Vy "Object velocity in Y direction";
CM_ SG_ 1310 RRR_Obj07A_Ax "Object acceleration in X direction";
CM_ SG_ 1311 RRR_Obj07B_CRC "CRC - Autosar E2E Profile 5";
CM_ SG_ 1311 RRR_Obj07B_MAC "SecOC MAC (Profile 1)";
CM_ SG_ 1311 RRR_Obj07B_AliveCtr "Alive counter - Autosar E2E Profile 5";
CM_ SG_ 1311 RRR_Obj07B_BlockCtr "Block-Counter";
CM_ SG_ 1311 RRR_Obj07B_ProbMob4PlusWhl "Probability of a mobile object which has 4 or more wheels";
CM_ SG_ 1311 RRR_Obj07B_ProbMob2Whl "Probability of a mobile object being 2-wheels vehicle";
CM_ SG_ 1311 RRR_Obj07B_ProbMobPed "Probability of a mobile object being a pedestrian";
CM_ SG_ 1311 RRR_Obj07B_Prob4PlusWhlCAR "Probability of a mobile object which has 4 or more wheels--passenger car";
CM_ SG_ 1311 RRR_Obj07B_Prob4PlusWhlbHGV "Probability of a mobile object which has 4 or more wheels--commercial vehicle(Turck)";
CM_ SG_ 1311 RRR_Obj07B_ProbGNDReflex "Probability of the object being a ground reflex";
CM_ SG_ 1311 RRR_Obj07B_ProbStatBarrier "Probability of the object being a stationary road barrier";
CM_ SG_ 1311 RRR_Obj07B_ProbStatObst "Probability of the object being a stationary obstacle";
CM_ SG_ 1311 RRR_Obj07B_MovingProbability "Object has been observed moving over the ground";
CM_ SG_ 1311 RRR_Obj07B_MovingObserved "Object has been observed moving over the ground since it was first detected";
CM_ SG_ 1311 RRR_Obj07B_FV "SecOC Freshness Value (Profile 1)";
CM_ SG_ 1312 RRR_Obj08A_CRC "CRC - Autosar E2E Profile 5";
CM_ SG_ 1312 RRR_Obj08A_Ay "Object acceleration in Y direction";
CM_ SG_ 1312 RRR_Obj08A_HeadingYawAngle "Object heading yaw angle";
CM_ SG_ 1312 RRR_Obj08A_Length "Object Length";
CM_ SG_ 1312 RRR_Obj08A_Width "Object Width";
CM_ SG_ 1312 RRR_Obj08A_Height "Object Height";
CM_ SG_ 1312 RRR_Obj08A_DxVnce "Variance of object position in X direction";
CM_ SG_ 1312 RRR_Obj08A_DyVnce "Variance of object position in Y direction";
CM_ SG_ 1312 RRR_Obj08A_DzVnce "Variance of object position in Z direction";
CM_ SG_ 1312 RRR_Obj08A_AliveCtr "Alive counter - Autosar E2E Profile 5";
CM_ SG_ 1312 RRR_Obj08A_VxVnce "Variance of object velocity in X direction";
CM_ SG_ 1312 RRR_Obj08A_VyVnce "Variance of object velocity in Y direction";
CM_ SG_ 1312 RRR_Obj08A_AxVnce "Variance of object acceleration in X direction";
CM_ SG_ 1312 RRR_Obj08A_AyVnce "Variance of object acceleration in Y direction";
CM_ SG_ 1312 RRR_Obj08A_RefPosIndex "Reference Position of the detected objects";
CM_ SG_ 1312 RRR_Obj08A_DxDyCoVnce "Correlation coefficient of Dx and Dy";
CM_ SG_ 1312 RRR_Obj08A_DxVxCoVnce "Correlation coefficient of Dx and Vx";
CM_ SG_ 1312 RRR_Obj08A_BlockCtr "Block-Counter";
CM_ SG_ 1312 RRR_Obj08A_DyVxCoVnce "Correlation coefficient of Dy and Ax";
CM_ SG_ 1312 RRR_Obj08A_DxVyCoVnce "Correlation coefficient of Dx and Vy";
CM_ SG_ 1312 RRR_Obj08A_DyVyCoVnce "Correlation coefficient of Dy and Vy";
CM_ SG_ 1312 RRR_Obj08A_VxVyCoVnce "Correlation coefficient of Vx and Vy";
CM_ SG_ 1312 RRR_Obj08A_DxAxCoVnce "Correlation coefficient of Dx and Ax";
CM_ SG_ 1312 RRR_Obj08A_DyAxCoVnce "Correlation coefficient of Dy and Ax";
CM_ SG_ 1312 RRR_Obj08A_VxAxCoVnce "Correlation coefficient of Vx and Ax";
CM_ SG_ 1312 RRR_Obj08A_ObjectID "Unique Object ID";
CM_ SG_ 1312 RRR_Obj08A_VyAxCoVnce "Correlation coefficient of Vy and Ax";
CM_ SG_ 1312 RRR_Obj08A_DxAyCoVnce "Correlation coefficient of Dx and Ay";
CM_ SG_ 1312 RRR_Obj08A_DyAyCoVnce "Correlation coefficient of Dy and Ay";
CM_ SG_ 1312 RRR_Obj08A_VxAyCoVnce "Correlation coefficient of Vx and Ay";
CM_ SG_ 1312 RRR_Obj08A_VyAyCoVnce "Correlation coefficient of Vy and Ay";
CM_ SG_ 1312 RRR_Obj08A_AxAyCoVnce "Correlation coefficient of Ax and Ay";
CM_ SG_ 1312 RRR_Obj08A_Measured "Object is measured or not";
CM_ SG_ 1312 RRR_Obj08A_HeadingYawVnce "Variance of Object heading yaw angle";
CM_ SG_ 1312 RRR_Obj08A_Dx "Object position in X direction";
CM_ SG_ 1312 RRR_Obj08A_LengthVnce "Variance of Object Length";
CM_ SG_ 1312 RRR_Obj08A_WidthVnce "Variance of Object Width";
CM_ SG_ 1312 RRR_Obj08A_HeightVnce "Variance of Object Height";
CM_ SG_ 1312 RRR_Obj08A_ExistProb "Existence probability of object";
CM_ SG_ 1312 RRR_Obj08A_ProbObstacle "Probability of the object being an Obstacle";
CM_ SG_ 1312 RRR_Obj08A_ProbNonObstacle "Probability of the object being a Non-Obstacle";
CM_ SG_ 1312 RRR_Obj08A_ProbMobileObst "Probability of the object being a mobile obstacle";
CM_ SG_ 1312 RRR_Obj08A_FV "SecOC Freshness Value (Profile 1)";
CM_ SG_ 1312 RRR_Obj08A_MAC "SecOC MAC (Profile 1)";
CM_ SG_ 1312 RRR_Obj08A_Dz "Object position in Z direction";
CM_ SG_ 1312 RRR_Obj08A_Dy "Object position in Y direction";
CM_ SG_ 1312 RRR_Obj08A_Valid "Object is valid or not";
CM_ SG_ 1312 RRR_Obj08A_Vx "Object velocity in X direction";
CM_ SG_ 1312 RRR_Obj08A_Vy "Object velocity in Y direction";
CM_ SG_ 1312 RRR_Obj08A_Ax "Object acceleration in X direction";
CM_ SG_ 1313 RRR_Obj08B_CRC "CRC - Autosar E2E Profile 5";
CM_ SG_ 1313 RRR_Obj08B_MAC "SecOC MAC (Profile 1)";
CM_ SG_ 1313 RRR_Obj08B_AliveCtr "Alive counter - Autosar E2E Profile 5";
CM_ SG_ 1313 RRR_Obj08B_BlockCtr "Block-Counter";
CM_ SG_ 1313 RRR_Obj08B_ProbMob4PlusWhl "Probability of a mobile object which has 4 or more wheels";
CM_ SG_ 1313 RRR_Obj08B_ProbMob2Whl "Probability of a mobile object being 2-wheels vehicle";
CM_ SG_ 1313 RRR_Obj08B_ProbMobPed "Probability of a mobile object being a pedestrian";
CM_ SG_ 1313 RRR_Obj08B_Prob4PlusWhlCAR "Probability of a mobile object which has 4 or more wheels--passenger car";
CM_ SG_ 1313 RRR_Obj08B_Prob4PlusWhlbHGV "Probability of a mobile object which has 4 or more wheels--commercial vehicle(Turck)";
CM_ SG_ 1313 RRR_Obj08B_ProbGNDReflex "Probability of the object being a ground reflex";
CM_ SG_ 1313 RRR_Obj08B_ProbStatBarrier "Probability of the object being a stationary road barrier";
CM_ SG_ 1313 RRR_Obj08B_ProbStatObst "Probability of the object being a stationary obstacle";
CM_ SG_ 1313 RRR_Obj08B_MovingProbability "Object has been observed moving over the ground";
CM_ SG_ 1313 RRR_Obj08B_MovingObserved "Object has been observed moving over the ground since it was first detected";
CM_ SG_ 1313 RRR_Obj08B_FV "SecOC Freshness Value (Profile 1)";
CM_ SG_ 1314 RRR_Obj09A_CRC "CRC - Autosar E2E Profile 5";
CM_ SG_ 1314 RRR_Obj09A_Ay "Object acceleration in Y direction";
CM_ SG_ 1314 RRR_Obj09A_HeadingYawAngle "Object heading yaw angle";
CM_ SG_ 1314 RRR_Obj09A_Length "Object Length";
CM_ SG_ 1314 RRR_Obj09A_Width "Object Width";
CM_ SG_ 1314 RRR_Obj09A_Height "Object Height";
CM_ SG_ 1314 RRR_Obj09A_DxVnce "Variance of object position in X direction";
CM_ SG_ 1314 RRR_Obj09A_DyVnce "Variance of object position in Y direction";
CM_ SG_ 1314 RRR_Obj09A_DzVnce "Variance of object position in Z direction";
CM_ SG_ 1314 RRR_Obj09A_AliveCtr "Alive counter - Autosar E2E Profile 5";
CM_ SG_ 1314 RRR_Obj09A_VxVnce "Variance of object velocity in X direction";
CM_ SG_ 1314 RRR_Obj09A_VyVnce "Variance of object velocity in Y direction";
CM_ SG_ 1314 RRR_Obj09A_AxVnce "Variance of object acceleration in X direction";
CM_ SG_ 1314 RRR_Obj09A_AyVnce "Variance of object acceleration in Y direction";
CM_ SG_ 1314 RRR_Obj09A_RefPosIndex "Reference Position of the detected objects";
CM_ SG_ 1314 RRR_Obj09A_DxDyCoVnce "Correlation coefficient of Dx and Dy";
CM_ SG_ 1314 RRR_Obj09A_DxVxCoVnce "Correlation coefficient of Dx and Vx";
CM_ SG_ 1314 RRR_Obj09A_BlockCtr "Block-Counter";
CM_ SG_ 1314 RRR_Obj09A_DyVxCoVnce "Correlation coefficient of Dy and Ax";
CM_ SG_ 1314 RRR_Obj09A_DxVyCoVnce "Correlation coefficient of Dx and Vy";
CM_ SG_ 1314 RRR_Obj09A_DyVyCoVnce "Correlation coefficient of Dy and Vy";
CM_ SG_ 1314 RRR_Obj09A_VxVyCoVnce "Correlation coefficient of Vx and Vy";
CM_ SG_ 1314 RRR_Obj09A_DxAxCoVnce "Correlation coefficient of Dx and Ax";
CM_ SG_ 1314 RRR_Obj09A_DyAxCoVnce "Correlation coefficient of Dy and Ax";
CM_ SG_ 1314 RRR_Obj09A_VxAxCoVnce "Correlation coefficient of Vx and Ax";
CM_ SG_ 1314 RRR_Obj09A_ObjectID "Unique Object ID";
CM_ SG_ 1314 RRR_Obj09A_VyAxCoVnce "Correlation coefficient of Vy and Ax";
CM_ SG_ 1314 RRR_Obj09A_DxAyCoVnce "Correlation coefficient of Dx and Ay";
CM_ SG_ 1314 RRR_Obj09A_DyAyCoVnce "Correlation coefficient of Dy and Ay";
CM_ SG_ 1314 RRR_Obj09A_VxAyCoVnce "Correlation coefficient of Vx and Ay";
CM_ SG_ 1314 RRR_Obj09A_VyAyCoVnce "Correlation coefficient of Vy and Ay";
CM_ SG_ 1314 RRR_Obj09A_AxAyCoVnce "Correlation coefficient of Ax and Ay";
CM_ SG_ 1314 RRR_Obj09A_Measured "Object is measured or not";
CM_ SG_ 1314 RRR_Obj09A_HeadingYawVnce "Variance of Object heading yaw angle";
CM_ SG_ 1314 RRR_Obj09A_Dx "Object position in X direction";
CM_ SG_ 1314 RRR_Obj09A_LengthVnce "Variance of Object Length";
CM_ SG_ 1314 RRR_Obj09A_WidthVnce "Variance of Object Width";
CM_ SG_ 1314 RRR_Obj09A_HeightVnce "Variance of Object Height";
CM_ SG_ 1314 RRR_Obj09A_ExistProb "Existence probability of object";
CM_ SG_ 1314 RRR_Obj09A_ProbObstacle "Probability of the object being an Obstacle";
CM_ SG_ 1314 RRR_Obj09A_ProbNonObstacle "Probability of the object being a Non-Obstacle";
CM_ SG_ 1314 RRR_Obj09A_ProbMobileObst "Probability of the object being a mobile obstacle";
CM_ SG_ 1314 RRR_Obj09A_FV "SecOC Freshness Value (Profile 1)";
CM_ SG_ 1314 RRR_Obj09A_MAC "SecOC MAC (Profile 1)";
CM_ SG_ 1314 RRR_Obj09A_Dz "Object position in Z direction";
CM_ SG_ 1314 RRR_Obj09A_Dy "Object position in Y direction";
CM_ SG_ 1314 RRR_Obj09A_Valid "Object is valid or not";
CM_ SG_ 1314 RRR_Obj09A_Vx "Object velocity in X direction";
CM_ SG_ 1314 RRR_Obj09A_Vy "Object velocity in Y direction";
CM_ SG_ 1314 RRR_Obj09A_Ax "Object acceleration in X direction";
CM_ SG_ 1315 RRR_Obj09B_CRC "CRC - Autosar E2E Profile 5";
CM_ SG_ 1315 RRR_Obj09B_MAC "SecOC MAC (Profile 1)";
CM_ SG_ 1315 RRR_Obj09B_AliveCtr "Alive counter - Autosar E2E Profile 5";
CM_ SG_ 1315 RRR_Obj09B_BlockCtr "Block-Counter";
CM_ SG_ 1315 RRR_Obj09B_ProbMob4PlusWhl "Probability of a mobile object which has 4 or more wheels";
CM_ SG_ 1315 RRR_Obj09B_ProbMob2Whl "Probability of a mobile object being 2-wheels vehicle";
CM_ SG_ 1315 RRR_Obj09B_ProbMobPed "Probability of a mobile object being a pedestrian";
CM_ SG_ 1315 RRR_Obj09B_Prob4PlusWhlCAR "Probability of a mobile object which has 4 or more wheels--passenger car";
CM_ SG_ 1315 RRR_Obj09B_Prob4PlusWhlbHGV "Probability of a mobile object which has 4 or more wheels--commercial vehicle(Turck)";
CM_ SG_ 1315 RRR_Obj09B_ProbGNDReflex "Probability of the object being a ground reflex";
CM_ SG_ 1315 RRR_Obj09B_ProbStatBarrier "Probability of the object being a stationary road barrier";
CM_ SG_ 1315 RRR_Obj09B_ProbStatObst "Probability of the object being a stationary obstacle";
CM_ SG_ 1315 RRR_Obj09B_MovingProbability "Object has been observed moving over the ground";
CM_ SG_ 1315 RRR_Obj09B_MovingObserved "Object has been observed moving over the ground since it was first detected";
CM_ SG_ 1315 RRR_Obj09B_FV "SecOC Freshness Value (Profile 1)";
CM_ SG_ 1316 RRR_Obj10A_CRC "CRC - Autosar E2E Profile 5";
CM_ SG_ 1316 RRR_Obj10A_Ay "Object acceleration in Y direction";
CM_ SG_ 1316 RRR_Obj10A_HeadingYawAngle "Object heading yaw angle";
CM_ SG_ 1316 RRR_Obj10A_Length "Object Length";
CM_ SG_ 1316 RRR_Obj10A_Width "Object Width";
CM_ SG_ 1316 RRR_Obj10A_Height "Object Height";
CM_ SG_ 1316 RRR_Obj10A_DxVnce "Variance of object position in X direction";
CM_ SG_ 1316 RRR_Obj10A_DyVnce "Variance of object position in Y direction";
CM_ SG_ 1316 RRR_Obj10A_DzVnce "Variance of object position in Z direction";
CM_ SG_ 1316 RRR_Obj10A_AliveCtr "Alive counter - Autosar E2E Profile 5";
CM_ SG_ 1316 RRR_Obj10A_VxVnce "Variance of object velocity in X direction";
CM_ SG_ 1316 RRR_Obj10A_VyVnce "Variance of object velocity in Y direction";
CM_ SG_ 1316 RRR_Obj10A_AxVnce "Variance of object acceleration in X direction";
CM_ SG_ 1316 RRR_Obj10A_AyVnce "Variance of object acceleration in Y direction";
CM_ SG_ 1316 RRR_Obj10A_RefPosIndex "Reference Position of the detected objects";
CM_ SG_ 1316 RRR_Obj10A_DxDyCoVnce "Correlation coefficient of Dx and Dy";
CM_ SG_ 1316 RRR_Obj10A_DxVxCoVnce "Correlation coefficient of Dx and Vx";
CM_ SG_ 1316 RRR_Obj10A_BlockCtr "Block-Counter";
CM_ SG_ 1316 RRR_Obj10A_DyVxCoVnce "Correlation coefficient of Dy and Ax";
CM_ SG_ 1316 RRR_Obj10A_DxVyCoVnce "Correlation coefficient of Dx and Vy";
CM_ SG_ 1316 RRR_Obj10A_DyVyCoVnce "Correlation coefficient of Dy and Vy";
CM_ SG_ 1316 RRR_Obj10A_VxVyCoVnce "Correlation coefficient of Vx and Vy";
CM_ SG_ 1316 RRR_Obj10A_DxAxCoVnce "Correlation coefficient of Dx and Ax";
CM_ SG_ 1316 RRR_Obj10A_DyAxCoVnce "Correlation coefficient of Dy and Ax";
CM_ SG_ 1316 RRR_Obj10A_VxAxCoVnce "Correlation coefficient of Vx and Ax";
CM_ SG_ 1316 RRR_Obj10A_ObjectID "Unique Object ID";
CM_ SG_ 1316 RRR_Obj10A_VyAxCoVnce "Correlation coefficient of Vy and Ax";
CM_ SG_ 1316 RRR_Obj10A_DxAyCoVnce "Correlation coefficient of Dx and Ay";
CM_ SG_ 1316 RRR_Obj10A_DyAyCoVnce "Correlation coefficient of Dy and Ay";
CM_ SG_ 1316 RRR_Obj10A_VxAyCoVnce "Correlation coefficient of Vx and Ay";
CM_ SG_ 1316 RRR_Obj10A_VyAyCoVnce "Correlation coefficient of Vy and Ay";
CM_ SG_ 1316 RRR_Obj10A_AxAyCoVnce "Correlation coefficient of Ax and Ay";
CM_ SG_ 1316 RRR_Obj10A_Measured "Object is measured or not";
CM_ SG_ 1316 RRR_Obj10A_HeadingYawVnce "Variance of Object heading yaw angle";
CM_ SG_ 1316 RRR_Obj10A_Dx "Object position in X direction";
CM_ SG_ 1316 RRR_Obj10A_LengthVnce "Variance of Object Length";
CM_ SG_ 1316 RRR_Obj10A_WidthVnce "Variance of Object Width";
CM_ SG_ 1316 RRR_Obj10A_HeightVnce "Variance of Object Height";
CM_ SG_ 1316 RRR_Obj10A_ExistProb "Existence probability of object";
CM_ SG_ 1316 RRR_Obj10A_ProbObstacle "Probability of the object being an Obstacle";
CM_ SG_ 1316 RRR_Obj10A_ProbNonObstacle "Probability of the object being a Non-Obstacle";
CM_ SG_ 1316 RRR_Obj10A_ProbMobileObst "Probability of the object being a mobile obstacle";
CM_ SG_ 1316 RRR_Obj10A_FV "SecOC Freshness Value (Profile 1)";
CM_ SG_ 1316 RRR_Obj10A_MAC "SecOC MAC (Profile 1)";
CM_ SG_ 1316 RRR_Obj10A_Dz "Object position in Z direction";
CM_ SG_ 1316 RRR_Obj10A_Dy "Object position in Y direction";
CM_ SG_ 1316 RRR_Obj10A_Valid "Object is valid or not";
CM_ SG_ 1316 RRR_Obj10A_Vx "Object velocity in X direction";
CM_ SG_ 1316 RRR_Obj10A_Vy "Object velocity in Y direction";
CM_ SG_ 1316 RRR_Obj10A_Ax "Object acceleration in X direction";
CM_ SG_ 1317 RRR_Obj10B_CRC "CRC - Autosar E2E Profile 5";
CM_ SG_ 1317 RRR_Obj10B_MAC "SecOC MAC (Profile 1)";
CM_ SG_ 1317 RRR_Obj10B_AliveCtr "Alive counter - Autosar E2E Profile 5";
CM_ SG_ 1317 RRR_Obj10B_BlockCtr "Block-Counter";
CM_ SG_ 1317 RRR_Obj10B_ProbMob4PlusWhl "Probability of a mobile object which has 4 or more wheels";
CM_ SG_ 1317 RRR_Obj10B_ProbMob2Whl "Probability of a mobile object being 2-wheels vehicle";
CM_ SG_ 1317 RRR_Obj10B_ProbMobPed "Probability of a mobile object being a pedestrian";
CM_ SG_ 1317 RRR_Obj10B_Prob4PlusWhlCAR "Probability of a mobile object which has 4 or more wheels--passenger car";
CM_ SG_ 1317 RRR_Obj10B_Prob4PlusWhlbHGV "Probability of a mobile object which has 4 or more wheels--commercial vehicle(Turck)";
CM_ SG_ 1317 RRR_Obj10B_ProbGNDReflex "Probability of the object being a ground reflex";
CM_ SG_ 1317 RRR_Obj10B_ProbStatBarrier "Probability of the object being a stationary road barrier";
CM_ SG_ 1317 RRR_Obj10B_ProbStatObst "Probability of the object being a stationary obstacle";
CM_ SG_ 1317 RRR_Obj10B_MovingProbability "Object has been observed moving over the ground";
CM_ SG_ 1317 RRR_Obj10B_MovingObserved "Object has been observed moving over the ground since it was first detected";
CM_ SG_ 1317 RRR_Obj10B_FV "SecOC Freshness Value (Profile 1)";
CM_ SG_ 1318 RRR_Obj11A_CRC "CRC - Autosar E2E Profile 5";
CM_ SG_ 1318 RRR_Obj11A_Ay "Object acceleration in Y direction";
CM_ SG_ 1318 RRR_Obj11A_HeadingYawAngle "Object heading yaw angle";
CM_ SG_ 1318 RRR_Obj11A_Length "Object Length";
CM_ SG_ 1318 RRR_Obj11A_Width "Object Width";
CM_ SG_ 1318 RRR_Obj11A_Height "Object Height";
CM_ SG_ 1318 RRR_Obj11A_DxVnce "Variance of object position in X direction";
CM_ SG_ 1318 RRR_Obj11A_DyVnce "Variance of object position in Y direction";
CM_ SG_ 1318 RRR_Obj11A_DzVnce "Variance of object position in Z direction";
CM_ SG_ 1318 RRR_Obj11A_AliveCtr "Alive counter - Autosar E2E Profile 5";
CM_ SG_ 1318 RRR_Obj11A_VxVnce "Variance of object velocity in X direction";
CM_ SG_ 1318 RRR_Obj11A_VyVnce "Variance of object velocity in Y direction";
CM_ SG_ 1318 RRR_Obj11A_AxVnce "Variance of object acceleration in X direction";
CM_ SG_ 1318 RRR_Obj11A_AyVnce "Variance of object acceleration in Y direction";
CM_ SG_ 1318 RRR_Obj11A_RefPosIndex "Reference Position of the detected objects";
CM_ SG_ 1318 RRR_Obj11A_DxDyCoVnce "Correlation coefficient of Dx and Dy";
CM_ SG_ 1318 RRR_Obj11A_DxVxCoVnce "Correlation coefficient of Dx and Vx";
CM_ SG_ 1318 RRR_Obj11A_BlockCtr "Block-Counter";
CM_ SG_ 1318 RRR_Obj11A_DyVxCoVnce "Correlation coefficient of Dy and Ax";
CM_ SG_ 1318 RRR_Obj11A_DxVyCoVnce "Correlation coefficient of Dx and Vy";
CM_ SG_ 1318 RRR_Obj11A_DyVyCoVnce "Correlation coefficient of Dy and Vy";
CM_ SG_ 1318 RRR_Obj11A_VxVyCoVnce "Correlation coefficient of Vx and Vy";
CM_ SG_ 1318 RRR_Obj11A_DxAxCoVnce "Correlation coefficient of Dx and Ax";
CM_ SG_ 1318 RRR_Obj11A_DyAxCoVnce "Correlation coefficient of Dy and Ax";
CM_ SG_ 1318 RRR_Obj11A_VxAxCoVnce "Correlation coefficient of Vx and Ax";
CM_ SG_ 1318 RRR_Obj11A_ObjectID "Unique Object ID";
CM_ SG_ 1318 RRR_Obj11A_VyAxCoVnce "Correlation coefficient of Vy and Ax";
CM_ SG_ 1318 RRR_Obj11A_DxAyCoVnce "Correlation coefficient of Dx and Ay";
CM_ SG_ 1318 RRR_Obj11A_DyAyCoVnce "Correlation coefficient of Dy and Ay";
CM_ SG_ 1318 RRR_Obj11A_VxAyCoVnce "Correlation coefficient of Vx and Ay";
CM_ SG_ 1318 RRR_Obj11A_VyAyCoVnce "Correlation coefficient of Vy and Ay";
CM_ SG_ 1318 RRR_Obj11A_AxAyCoVnce "Correlation coefficient of Ax and Ay";
CM_ SG_ 1318 RRR_Obj11A_Measured "Object is measured or not";
CM_ SG_ 1318 RRR_Obj11A_HeadingYawVnce "Variance of Object heading yaw angle";
CM_ SG_ 1318 RRR_Obj11A_Dx "Object position in X direction";
CM_ SG_ 1318 RRR_Obj11A_LengthVnce "Variance of Object Length";
CM_ SG_ 1318 RRR_Obj11A_WidthVnce "Variance of Object Width";
CM_ SG_ 1318 RRR_Obj11A_HeightVnce "Variance of Object Height";
CM_ SG_ 1318 RRR_Obj11A_ExistProb "Existence probability of object";
CM_ SG_ 1318 RRR_Obj11A_ProbObstacle "Probability of the object being an Obstacle";
CM_ SG_ 1318 RRR_Obj11A_ProbNonObstacle "Probability of the object being a Non-Obstacle";
CM_ SG_ 1318 RRR_Obj11A_ProbMobileObst "Probability of the object being a mobile obstacle";
CM_ SG_ 1318 RRR_Obj11A_FV "SecOC Freshness Value (Profile 1)";
CM_ SG_ 1318 RRR_Obj11A_MAC "SecOC MAC (Profile 1)";
CM_ SG_ 1318 RRR_Obj11A_Dz "Object position in Z direction";
CM_ SG_ 1318 RRR_Obj11A_Dy "Object position in Y direction";
CM_ SG_ 1318 RRR_Obj11A_Valid "Object is valid or not";
CM_ SG_ 1318 RRR_Obj11A_Vx "Object velocity in X direction";
CM_ SG_ 1318 RRR_Obj11A_Vy "Object velocity in Y direction";
CM_ SG_ 1318 RRR_Obj11A_Ax "Object acceleration in X direction";
CM_ SG_ 1319 RRR_Obj11B_CRC "CRC - Autosar E2E Profile 5";
CM_ SG_ 1319 RRR_Obj11B_MAC "SecOC MAC (Profile 1)";
CM_ SG_ 1319 RRR_Obj11B_AliveCtr "Alive counter - Autosar E2E Profile 5";
CM_ SG_ 1319 RRR_Obj11B_BlockCtr "Block-Counter";
CM_ SG_ 1319 RRR_Obj11B_ProbMob4PlusWhl "Probability of a mobile object which has 4 or more wheels";
CM_ SG_ 1319 RRR_Obj11B_ProbMob2Whl "Probability of a mobile object being 2-wheels vehicle";
CM_ SG_ 1319 RRR_Obj11B_ProbMobPed "Probability of a mobile object being a pedestrian";
CM_ SG_ 1319 RRR_Obj11B_Prob4PlusWhlCAR "Probability of a mobile object which has 4 or more wheels--passenger car";
CM_ SG_ 1319 RRR_Obj11B_Prob4PlusWhlbHGV "Probability of a mobile object which has 4 or more wheels--commercial vehicle(Turck)";
CM_ SG_ 1319 RRR_Obj11B_ProbGNDReflex "Probability of the object being a ground reflex";
CM_ SG_ 1319 RRR_Obj11B_ProbStatBarrier "Probability of the object being a stationary road barrier";
CM_ SG_ 1319 RRR_Obj11B_ProbStatObst "Probability of the object being a stationary obstacle";
CM_ SG_ 1319 RRR_Obj11B_MovingProbability "Object has been observed moving over the ground";
CM_ SG_ 1319 RRR_Obj11B_MovingObserved "Object has been observed moving over the ground since it was first detected";
CM_ SG_ 1319 RRR_Obj11B_FV "SecOC Freshness Value (Profile 1)";
CM_ SG_ 1320 RRR_Obj12A_CRC "CRC - Autosar E2E Profile 5";
CM_ SG_ 1320 RRR_Obj12A_Ay "Object acceleration in Y direction";
CM_ SG_ 1320 RRR_Obj12A_HeadingYawAngle "Object heading yaw angle";
CM_ SG_ 1320 RRR_Obj12A_Length "Object Length";
CM_ SG_ 1320 RRR_Obj12A_Width "Object Width";
CM_ SG_ 1320 RRR_Obj12A_Height "Object Height";
CM_ SG_ 1320 RRR_Obj12A_DxVnce "Variance of object position in X direction";
CM_ SG_ 1320 RRR_Obj12A_DyVnce "Variance of object position in Y direction";
CM_ SG_ 1320 RRR_Obj12A_DzVnce "Variance of object position in Z direction";
CM_ SG_ 1320 RRR_Obj12A_AliveCtr "Alive counter - Autosar E2E Profile 5";
CM_ SG_ 1320 RRR_Obj12A_VxVnce "Variance of object velocity in X direction";
CM_ SG_ 1320 RRR_Obj12A_VyVnce "Variance of object velocity in Y direction";
CM_ SG_ 1320 RRR_Obj12A_AxVnce "Variance of object acceleration in X direction";
CM_ SG_ 1320 RRR_Obj12A_AyVnce "Variance of object acceleration in Y direction";
CM_ SG_ 1320 RRR_Obj12A_RefPosIndex "Reference Position of the detected objects";
CM_ SG_ 1320 RRR_Obj12A_DxDyCoVnce "Correlation coefficient of Dx and Dy";
CM_ SG_ 1320 RRR_Obj12A_DxVxCoVnce "Correlation coefficient of Dx and Vx";
CM_ SG_ 1320 RRR_Obj12A_BlockCtr "Block-Counter";
CM_ SG_ 1320 RRR_Obj12A_DyVxCoVnce "Correlation coefficient of Dy and Ax";
CM_ SG_ 1320 RRR_Obj12A_DxVyCoVnce "Correlation coefficient of Dx and Vy";
CM_ SG_ 1320 RRR_Obj12A_DyVyCoVnce "Correlation coefficient of Dy and Vy";
CM_ SG_ 1320 RRR_Obj12A_VxVyCoVnce "Correlation coefficient of Vx and Vy";
CM_ SG_ 1320 RRR_Obj12A_DxAxCoVnce "Correlation coefficient of Dx and Ax";
CM_ SG_ 1320 RRR_Obj12A_DyAxCoVnce "Correlation coefficient of Dy and Ax";
CM_ SG_ 1320 RRR_Obj12A_VxAxCoVnce "Correlation coefficient of Vx and Ax";
CM_ SG_ 1320 RRR_Obj12A_ObjectID "Unique Object ID";
CM_ SG_ 1320 RRR_Obj12A_VyAxCoVnce "Correlation coefficient of Vy and Ax";
CM_ SG_ 1320 RRR_Obj12A_DxAyCoVnce "Correlation coefficient of Dx and Ay";
CM_ SG_ 1320 RRR_Obj12A_DyAyCoVnce "Correlation coefficient of Dy and Ay";
CM_ SG_ 1320 RRR_Obj12A_VxAyCoVnce "Correlation coefficient of Vx and Ay";
CM_ SG_ 1320 RRR_Obj12A_VyAyCoVnce "Correlation coefficient of Vy and Ay";
CM_ SG_ 1320 RRR_Obj12A_AxAyCoVnce "Correlation coefficient of Ax and Ay";
CM_ SG_ 1320 RRR_Obj12A_Measured "Object is measured or not";
CM_ SG_ 1320 RRR_Obj12A_HeadingYawVnce "Variance of Object heading yaw angle";
CM_ SG_ 1320 RRR_Obj12A_Dx "Object position in X direction";
CM_ SG_ 1320 RRR_Obj12A_LengthVnce "Variance of Object Length";
CM_ SG_ 1320 RRR_Obj12A_WidthVnce "Variance of Object Width";
CM_ SG_ 1320 RRR_Obj12A_HeightVnce "Variance of Object Height";
CM_ SG_ 1320 RRR_Obj12A_ExistProb "Existence probability of object";
CM_ SG_ 1320 RRR_Obj12A_ProbObstacle "Probability of the object being an Obstacle";
CM_ SG_ 1320 RRR_Obj12A_ProbNonObstacle "Probability of the object being a Non-Obstacle";
CM_ SG_ 1320 RRR_Obj12A_ProbMobileObst "Probability of the object being a mobile obstacle";
CM_ SG_ 1320 RRR_Obj12A_FV "SecOC Freshness Value (Profile 1)";
CM_ SG_ 1320 RRR_Obj12A_MAC "SecOC MAC (Profile 1)";
CM_ SG_ 1320 RRR_Obj12A_Dz "Object position in Z direction";
CM_ SG_ 1320 RRR_Obj12A_Dy "Object position in Y direction";
CM_ SG_ 1320 RRR_Obj12A_Valid "Object is valid or not";
CM_ SG_ 1320 RRR_Obj12A_Vx "Object velocity in X direction";
CM_ SG_ 1320 RRR_Obj12A_Vy "Object velocity in Y direction";
CM_ SG_ 1320 RRR_Obj12A_Ax "Object acceleration in X direction";
CM_ SG_ 1321 RRR_Obj12B_CRC "CRC - Autosar E2E Profile 5";
CM_ SG_ 1321 RRR_Obj12B_MAC "SecOC MAC (Profile 1)";
CM_ SG_ 1321 RRR_Obj12B_AliveCtr "Alive counter - Autosar E2E Profile 5";
CM_ SG_ 1321 RRR_Obj12B_BlockCtr "Block-Counter";
CM_ SG_ 1321 RRR_Obj12B_ProbMob4PlusWhl "Probability of a mobile object which has 4 or more wheels";
CM_ SG_ 1321 RRR_Obj12B_ProbMob2Whl "Probability of a mobile object being 2-wheels vehicle";
CM_ SG_ 1321 RRR_Obj12B_ProbMobPed "Probability of a mobile object being a pedestrian";
CM_ SG_ 1321 RRR_Obj12B_Prob4PlusWhlCAR "Probability of a mobile object which has 4 or more wheels--passenger car";
CM_ SG_ 1321 RRR_Obj12B_Prob4PlusWhlbHGV "Probability of a mobile object which has 4 or more wheels--commercial vehicle(Turck)";
CM_ SG_ 1321 RRR_Obj12B_ProbGNDReflex "Probability of the object being a ground reflex";
CM_ SG_ 1321 RRR_Obj12B_ProbStatBarrier "Probability of the object being a stationary road barrier";
CM_ SG_ 1321 RRR_Obj12B_ProbStatObst "Probability of the object being a stationary obstacle";
CM_ SG_ 1321 RRR_Obj12B_MovingProbability "Object has been observed moving over the ground";
CM_ SG_ 1321 RRR_Obj12B_MovingObserved "Object has been observed moving over the ground since it was first detected";
CM_ SG_ 1321 RRR_Obj12B_FV "SecOC Freshness Value (Profile 1)";
CM_ SG_ 1322 RRR_Obj13A_CRC "CRC - Autosar E2E Profile 5";
CM_ SG_ 1322 RRR_Obj13A_Ay "Object acceleration in Y direction";
CM_ SG_ 1322 RRR_Obj13A_HeadingYawAngle "Object heading yaw angle";
CM_ SG_ 1322 RRR_Obj13A_Length "Object Length";
CM_ SG_ 1322 RRR_Obj13A_Width "Object Width";
CM_ SG_ 1322 RRR_Obj13A_Height "Object Height";
CM_ SG_ 1322 RRR_Obj13A_DxVnce "Variance of object position in X direction";
CM_ SG_ 1322 RRR_Obj13A_DyVnce "Variance of object position in Y direction";
CM_ SG_ 1322 RRR_Obj13A_DzVnce "Variance of object position in Z direction";
CM_ SG_ 1322 RRR_Obj13A_AliveCtr "Alive counter - Autosar E2E Profile 5";
CM_ SG_ 1322 RRR_Obj13A_VxVnce "Variance of object velocity in X direction";
CM_ SG_ 1322 RRR_Obj13A_VyVnce "Variance of object velocity in Y direction";
CM_ SG_ 1322 RRR_Obj13A_AxVnce "Variance of object acceleration in X direction";
CM_ SG_ 1322 RRR_Obj13A_AyVnce "Variance of object acceleration in Y direction";
CM_ SG_ 1322 RRR_Obj13A_RefPosIndex "Reference Position of the detected objects";
CM_ SG_ 1322 RRR_Obj13A_DxDyCoVnce "Correlation coefficient of Dx and Dy";
CM_ SG_ 1322 RRR_Obj13A_DxVxCoVnce "Correlation coefficient of Dx and Vx";
CM_ SG_ 1322 RRR_Obj13A_BlockCtr "Block-Counter";
CM_ SG_ 1322 RRR_Obj13A_DyVxCoVnce "Correlation coefficient of Dy and Ax";
CM_ SG_ 1322 RRR_Obj13A_DxVyCoVnce "Correlation coefficient of Dx and Vy";
CM_ SG_ 1322 RRR_Obj13A_DyVyCoVnce "Correlation coefficient of Dy and Vy";
CM_ SG_ 1322 RRR_Obj13A_VxVyCoVnce "Correlation coefficient of Vx and Vy";
CM_ SG_ 1322 RRR_Obj13A_DxAxCoVnce "Correlation coefficient of Dx and Ax";
CM_ SG_ 1322 RRR_Obj13A_DyAxCoVnce "Correlation coefficient of Dy and Ax";
CM_ SG_ 1322 RRR_Obj13A_VxAxCoVnce "Correlation coefficient of Vx and Ax";
CM_ SG_ 1322 RRR_Obj13A_ObjectID "Unique Object ID";
CM_ SG_ 1322 RRR_Obj13A_VyAxCoVnce "Correlation coefficient of Vy and Ax";
CM_ SG_ 1322 RRR_Obj13A_DxAyCoVnce "Correlation coefficient of Dx and Ay";
CM_ SG_ 1322 RRR_Obj13A_DyAyCoVnce "Correlation coefficient of Dy and Ay";
CM_ SG_ 1322 RRR_Obj13A_VxAyCoVnce "Correlation coefficient of Vx and Ay";
CM_ SG_ 1322 RRR_Obj13A_VyAyCoVnce "Correlation coefficient of Vy and Ay";
CM_ SG_ 1322 RRR_Obj13A_AxAyCoVnce "Correlation coefficient of Ax and Ay";
CM_ SG_ 1322 RRR_Obj13A_Measured "Object is measured or not";
CM_ SG_ 1322 RRR_Obj13A_HeadingYawVnce "Variance of Object heading yaw angle";
CM_ SG_ 1322 RRR_Obj13A_Dx "Object position in X direction";
CM_ SG_ 1322 RRR_Obj13A_LengthVnce "Variance of Object Length";
CM_ SG_ 1322 RRR_Obj13A_WidthVnce "Variance of Object Width";
CM_ SG_ 1322 RRR_Obj13A_HeightVnce "Variance of Object Height";
CM_ SG_ 1322 RRR_Obj13A_ExistProb "Existence probability of object";
CM_ SG_ 1322 RRR_Obj13A_ProbObstacle "Probability of the object being an Obstacle";
CM_ SG_ 1322 RRR_Obj13A_ProbNonObstacle "Probability of the object being a Non-Obstacle";
CM_ SG_ 1322 RRR_Obj13A_ProbMobileObst "Probability of the object being a mobile obstacle";
CM_ SG_ 1322 RRR_Obj13A_FV "SecOC Freshness Value (Profile 1)";
CM_ SG_ 1322 RRR_Obj13A_MAC "SecOC MAC (Profile 1)";
CM_ SG_ 1322 RRR_Obj13A_Dz "Object position in Z direction";
CM_ SG_ 1322 RRR_Obj13A_Dy "Object position in Y direction";
CM_ SG_ 1322 RRR_Obj13A_Valid "Object is valid or not";
CM_ SG_ 1322 RRR_Obj13A_Vx "Object velocity in X direction";
CM_ SG_ 1322 RRR_Obj13A_Vy "Object velocity in Y direction";
CM_ SG_ 1322 RRR_Obj13A_Ax "Object acceleration in X direction";
CM_ SG_ 1323 RRR_Obj13B_CRC "CRC - Autosar E2E Profile 5";
CM_ SG_ 1323 RRR_Obj13B_MAC "SecOC MAC (Profile 1)";
CM_ SG_ 1323 RRR_Obj13B_AliveCtr "Alive counter - Autosar E2E Profile 5";
CM_ SG_ 1323 RRR_Obj13B_BlockCtr "Block-Counter";
CM_ SG_ 1323 RRR_Obj13B_ProbMob4PlusWhl "Probability of a mobile object which has 4 or more wheels";
CM_ SG_ 1323 RRR_Obj13B_ProbMob2Whl "Probability of a mobile object being 2-wheels vehicle";
CM_ SG_ 1323 RRR_Obj13B_ProbMobPed "Probability of a mobile object being a pedestrian";
CM_ SG_ 1323 RRR_Obj13B_Prob4PlusWhlCAR "Probability of a mobile object which has 4 or more wheels--passenger car";
CM_ SG_ 1323 RRR_Obj13B_Prob4PlusWhlbHGV "Probability of a mobile object which has 4 or more wheels--commercial vehicle(Turck)";
CM_ SG_ 1323 RRR_Obj13B_ProbGNDReflex "Probability of the object being a ground reflex";
CM_ SG_ 1323 RRR_Obj13B_ProbStatBarrier "Probability of the object being a stationary road barrier";
CM_ SG_ 1323 RRR_Obj13B_ProbStatObst "Probability of the object being a stationary obstacle";
CM_ SG_ 1323 RRR_Obj13B_MovingProbability "Object has been observed moving over the ground";
CM_ SG_ 1323 RRR_Obj13B_MovingObserved "Object has been observed moving over the ground since it was first detected";
CM_ SG_ 1323 RRR_Obj13B_FV "SecOC Freshness Value (Profile 1)";
CM_ SG_ 1324 RRR_Obj14A_CRC "CRC - Autosar E2E Profile 5";
CM_ SG_ 1324 RRR_Obj14A_Ay "Object acceleration in Y direction";
CM_ SG_ 1324 RRR_Obj14A_HeadingYawAngle "Object heading yaw angle";
CM_ SG_ 1324 RRR_Obj14A_Length "Object Length";
CM_ SG_ 1324 RRR_Obj14A_Width "Object Width";
CM_ SG_ 1324 RRR_Obj14A_Height "Object Height";
CM_ SG_ 1324 RRR_Obj14A_DxVnce "Variance of object position in X direction";
CM_ SG_ 1324 RRR_Obj14A_DyVnce "Variance of object position in Y direction";
CM_ SG_ 1324 RRR_Obj14A_DzVnce "Variance of object position in Z direction";
CM_ SG_ 1324 RRR_Obj14A_AliveCtr "Alive counter - Autosar E2E Profile 5";
CM_ SG_ 1324 RRR_Obj14A_VxVnce "Variance of object velocity in X direction";
CM_ SG_ 1324 RRR_Obj14A_VyVnce "Variance of object velocity in Y direction";
CM_ SG_ 1324 RRR_Obj14A_AxVnce "Variance of object acceleration in X direction";
CM_ SG_ 1324 RRR_Obj14A_AyVnce "Variance of object acceleration in Y direction";
CM_ SG_ 1324 RRR_Obj14A_RefPosIndex "Reference Position of the detected objects";
CM_ SG_ 1324 RRR_Obj14A_DxDyCoVnce "Correlation coefficient of Dx and Dy";
CM_ SG_ 1324 RRR_Obj14A_DxVxCoVnce "Correlation coefficient of Dx and Vx";
CM_ SG_ 1324 RRR_Obj14A_BlockCtr "Block-Counter";
CM_ SG_ 1324 RRR_Obj14A_DyVxCoVnce "Correlation coefficient of Dy and Ax";
CM_ SG_ 1324 RRR_Obj14A_DxVyCoVnce "Correlation coefficient of Dx and Vy";
CM_ SG_ 1324 RRR_Obj14A_DyVyCoVnce "Correlation coefficient of Dy and Vy";
CM_ SG_ 1324 RRR_Obj14A_VxVyCoVnce "Correlation coefficient of Vx and Vy";
CM_ SG_ 1324 RRR_Obj14A_DxAxCoVnce "Correlation coefficient of Dx and Ax";
CM_ SG_ 1324 RRR_Obj14A_DyAxCoVnce "Correlation coefficient of Dy and Ax";
CM_ SG_ 1324 RRR_Obj14A_VxAxCoVnce "Correlation coefficient of Vx and Ax";
CM_ SG_ 1324 RRR_Obj14A_ObjectID "Unique Object ID";
CM_ SG_ 1324 RRR_Obj14A_VyAxCoVnce "Correlation coefficient of Vy and Ax";
CM_ SG_ 1324 RRR_Obj14A_DxAyCoVnce "Correlation coefficient of Dx and Ay";
CM_ SG_ 1324 RRR_Obj14A_DyAyCoVnce "Correlation coefficient of Dy and Ay";
CM_ SG_ 1324 RRR_Obj14A_VxAyCoVnce "Correlation coefficient of Vx and Ay";
CM_ SG_ 1324 RRR_Obj14A_VyAyCoVnce "Correlation coefficient of Vy and Ay";
CM_ SG_ 1324 RRR_Obj14A_AxAyCoVnce "Correlation coefficient of Ax and Ay";
CM_ SG_ 1324 RRR_Obj14A_Measured "Object is measured or not";
CM_ SG_ 1324 RRR_Obj14A_HeadingYawVnce "Variance of Object heading yaw angle";
CM_ SG_ 1324 RRR_Obj14A_Dx "Object position in X direction";
CM_ SG_ 1324 RRR_Obj14A_LengthVnce "Variance of Object Length";
CM_ SG_ 1324 RRR_Obj14A_WidthVnce "Variance of Object Width";
CM_ SG_ 1324 RRR_Obj14A_HeightVnce "Variance of Object Height";
CM_ SG_ 1324 RRR_Obj14A_ExistProb "Existence probability of object";
CM_ SG_ 1324 RRR_Obj14A_ProbObstacle "Probability of the object being an Obstacle";
CM_ SG_ 1324 RRR_Obj14A_ProbNonObstacle "Probability of the object being a Non-Obstacle";
CM_ SG_ 1324 RRR_Obj14A_ProbMobileObst "Probability of the object being a mobile obstacle";
CM_ SG_ 1324 RRR_Obj14A_FV "SecOC Freshness Value (Profile 1)";
CM_ SG_ 1324 RRR_Obj14A_MAC "SecOC MAC (Profile 1)";
CM_ SG_ 1324 RRR_Obj14A_Dz "Object position in Z direction";
CM_ SG_ 1324 RRR_Obj14A_Dy "Object position in Y direction";
CM_ SG_ 1324 RRR_Obj14A_Valid "Object is valid or not";
CM_ SG_ 1324 RRR_Obj14A_Vx "Object velocity in X direction";
CM_ SG_ 1324 RRR_Obj14A_Vy "Object velocity in Y direction";
CM_ SG_ 1324 RRR_Obj14A_Ax "Object acceleration in X direction";
CM_ SG_ 1325 RRR_Obj14B_CRC "CRC - Autosar E2E Profile 5";
CM_ SG_ 1325 RRR_Obj14B_MAC "SecOC MAC (Profile 1)";
CM_ SG_ 1325 RRR_Obj14B_AliveCtr "Alive counter - Autosar E2E Profile 5";
CM_ SG_ 1325 RRR_Obj14B_BlockCtr "Block-Counter";
CM_ SG_ 1325 RRR_Obj14B_ProbMob4PlusWhl "Probability of a mobile object which has 4 or more wheels";
CM_ SG_ 1325 RRR_Obj14B_ProbMob2Whl "Probability of a mobile object being 2-wheels vehicle";
CM_ SG_ 1325 RRR_Obj14B_ProbMobPed "Probability of a mobile object being a pedestrian";
CM_ SG_ 1325 RRR_Obj14B_Prob4PlusWhlCAR "Probability of a mobile object which has 4 or more wheels--passenger car";
CM_ SG_ 1325 RRR_Obj14B_Prob4PlusWhlbHGV "Probability of a mobile object which has 4 or more wheels--commercial vehicle(Turck)";
CM_ SG_ 1325 RRR_Obj14B_ProbGNDReflex "Probability of the object being a ground reflex";
CM_ SG_ 1325 RRR_Obj14B_ProbStatBarrier "Probability of the object being a stationary road barrier";
CM_ SG_ 1325 RRR_Obj14B_ProbStatObst "Probability of the object being a stationary obstacle";
CM_ SG_ 1325 RRR_Obj14B_MovingProbability "Object has been observed moving over the ground";
CM_ SG_ 1325 RRR_Obj14B_MovingObserved "Object has been observed moving over the ground since it was first detected";
CM_ SG_ 1325 RRR_Obj14B_FV "SecOC Freshness Value (Profile 1)";
CM_ SG_ 1326 RRR_Obj15A_CRC "CRC - Autosar E2E Profile 5";
CM_ SG_ 1326 RRR_Obj15A_Ay "Object acceleration in Y direction";
CM_ SG_ 1326 RRR_Obj15A_HeadingYawAngle "Object heading yaw angle";
CM_ SG_ 1326 RRR_Obj15A_Length "Object Length";
CM_ SG_ 1326 RRR_Obj15A_Width "Object Width";
CM_ SG_ 1326 RRR_Obj15A_Height "Object Height";
CM_ SG_ 1326 RRR_Obj15A_DxVnce "Variance of object position in X direction";
CM_ SG_ 1326 RRR_Obj15A_DyVnce "Variance of object position in Y direction";
CM_ SG_ 1326 RRR_Obj15A_DzVnce "Variance of object position in Z direction";
CM_ SG_ 1326 RRR_Obj15A_AliveCtr "Alive counter - Autosar E2E Profile 5";
CM_ SG_ 1326 RRR_Obj15A_VxVnce "Variance of object velocity in X direction";
CM_ SG_ 1326 RRR_Obj15A_VyVnce "Variance of object velocity in Y direction";
CM_ SG_ 1326 RRR_Obj15A_AxVnce "Variance of object acceleration in X direction";
CM_ SG_ 1326 RRR_Obj15A_AyVnce "Variance of object acceleration in Y direction";
CM_ SG_ 1326 RRR_Obj15A_RefPosIndex "Reference Position of the detected objects";
CM_ SG_ 1326 RRR_Obj15A_DxDyCoVnce "Correlation coefficient of Dx and Dy";
CM_ SG_ 1326 RRR_Obj15A_DxVxCoVnce "Correlation coefficient of Dx and Vx";
CM_ SG_ 1326 RRR_Obj15A_BlockCtr "Block-Counter";
CM_ SG_ 1326 RRR_Obj15A_DyVxCoVnce "Correlation coefficient of Dy and Ax";
CM_ SG_ 1326 RRR_Obj15A_DxVyCoVnce "Correlation coefficient of Dx and Vy";
CM_ SG_ 1326 RRR_Obj15A_DyVyCoVnce "Correlation coefficient of Dy and Vy";
CM_ SG_ 1326 RRR_Obj15A_VxVyCoVnce "Correlation coefficient of Vx and Vy";
CM_ SG_ 1326 RRR_Obj15A_DxAxCoVnce "Correlation coefficient of Dx and Ax";
CM_ SG_ 1326 RRR_Obj15A_DyAxCoVnce "Correlation coefficient of Dy and Ax";
CM_ SG_ 1326 RRR_Obj15A_VxAxCoVnce "Correlation coefficient of Vx and Ax";
CM_ SG_ 1326 RRR_Obj15A_ObjectID "Unique Object ID";
CM_ SG_ 1326 RRR_Obj15A_VyAxCoVnce "Correlation coefficient of Vy and Ax";
CM_ SG_ 1326 RRR_Obj15A_DxAyCoVnce "Correlation coefficient of Dx and Ay";
CM_ SG_ 1326 RRR_Obj15A_DyAyCoVnce "Correlation coefficient of Dy and Ay";
CM_ SG_ 1326 RRR_Obj15A_VxAyCoVnce "Correlation coefficient of Vx and Ay";
CM_ SG_ 1326 RRR_Obj15A_VyAyCoVnce "Correlation coefficient of Vy and Ay";
CM_ SG_ 1326 RRR_Obj15A_AxAyCoVnce "Correlation coefficient of Ax and Ay";
CM_ SG_ 1326 RRR_Obj15A_Measured "Object is measured or not";
CM_ SG_ 1326 RRR_Obj15A_HeadingYawVnce "Variance of Object heading yaw angle";
CM_ SG_ 1326 RRR_Obj15A_Dx "Object position in X direction";
CM_ SG_ 1326 RRR_Obj15A_LengthVnce "Variance of Object Length";
CM_ SG_ 1326 RRR_Obj15A_WidthVnce "Variance of Object Width";
CM_ SG_ 1326 RRR_Obj15A_HeightVnce "Variance of Object Height";
CM_ SG_ 1326 RRR_Obj15A_ExistProb "Existence probability of object";
CM_ SG_ 1326 RRR_Obj15A_ProbObstacle "Probability of the object being an Obstacle";
CM_ SG_ 1326 RRR_Obj15A_ProbNonObstacle "Probability of the object being a Non-Obstacle";
CM_ SG_ 1326 RRR_Obj15A_ProbMobileObst "Probability of the object being a mobile obstacle";
CM_ SG_ 1326 RRR_Obj15A_FV "SecOC Freshness Value (Profile 1)";
CM_ SG_ 1326 RRR_Obj15A_MAC "SecOC MAC (Profile 1)";
CM_ SG_ 1326 RRR_Obj15A_Dz "Object position in Z direction";
CM_ SG_ 1326 RRR_Obj15A_Dy "Object position in Y direction";
CM_ SG_ 1326 RRR_Obj15A_Valid "Object is valid or not";
CM_ SG_ 1326 RRR_Obj15A_Vx "Object velocity in X direction";
CM_ SG_ 1326 RRR_Obj15A_Vy "Object velocity in Y direction";
CM_ SG_ 1326 RRR_Obj15A_Ax "Object acceleration in X direction";
CM_ SG_ 1327 RRR_Obj15B_CRC "CRC - Autosar E2E Profile 5";
CM_ SG_ 1327 RRR_Obj15B_MAC "SecOC MAC (Profile 1)";
CM_ SG_ 1327 RRR_Obj15B_AliveCtr "Alive counter - Autosar E2E Profile 5";
CM_ SG_ 1327 RRR_Obj15B_BlockCtr "Block-Counter";
CM_ SG_ 1327 RRR_Obj15B_ProbMob4PlusWhl "Probability of a mobile object which has 4 or more wheels";
CM_ SG_ 1327 RRR_Obj15B_ProbMob2Whl "Probability of a mobile object being 2-wheels vehicle";
CM_ SG_ 1327 RRR_Obj15B_ProbMobPed "Probability of a mobile object being a pedestrian";
CM_ SG_ 1327 RRR_Obj15B_Prob4PlusWhlCAR "Probability of a mobile object which has 4 or more wheels--passenger car";
CM_ SG_ 1327 RRR_Obj15B_Prob4PlusWhlbHGV "Probability of a mobile object which has 4 or more wheels--commercial vehicle(Turck)";
CM_ SG_ 1327 RRR_Obj15B_ProbGNDReflex "Probability of the object being a ground reflex";
CM_ SG_ 1327 RRR_Obj15B_ProbStatBarrier "Probability of the object being a stationary road barrier";
CM_ SG_ 1327 RRR_Obj15B_ProbStatObst "Probability of the object being a stationary obstacle";
CM_ SG_ 1327 RRR_Obj15B_MovingProbability "Object has been observed moving over the ground";
CM_ SG_ 1327 RRR_Obj15B_MovingObserved "Object has been observed moving over the ground since it was first detected";
CM_ SG_ 1327 RRR_Obj15B_FV "SecOC Freshness Value (Profile 1)";
CM_ SG_ 1328 RRR_Obj16A_CRC "CRC - Autosar E2E Profile 5";
CM_ SG_ 1328 RRR_Obj16A_Ay "Object acceleration in Y direction";
CM_ SG_ 1328 RRR_Obj16A_HeadingYawAngle "Object heading yaw angle";
CM_ SG_ 1328 RRR_Obj16A_Length "Object Length";
CM_ SG_ 1328 RRR_Obj16A_Width "Object Width";
CM_ SG_ 1328 RRR_Obj16A_Height "Object Height";
CM_ SG_ 1328 RRR_Obj16A_DxVnce "Variance of object position in X direction";
CM_ SG_ 1328 RRR_Obj16A_DyVnce "Variance of object position in Y direction";
CM_ SG_ 1328 RRR_Obj16A_DzVnce "Variance of object position in Z direction";
CM_ SG_ 1328 RRR_Obj16A_AliveCtr "Alive counter - Autosar E2E Profile 5";
CM_ SG_ 1328 RRR_Obj16A_VxVnce "Variance of object velocity in X direction";
CM_ SG_ 1328 RRR_Obj16A_VyVnce "Variance of object velocity in Y direction";
CM_ SG_ 1328 RRR_Obj16A_AxVnce "Variance of object acceleration in X direction";
CM_ SG_ 1328 RRR_Obj16A_AyVnce "Variance of object acceleration in Y direction";
CM_ SG_ 1328 RRR_Obj16A_RefPosIndex "Reference Position of the detected objects";
CM_ SG_ 1328 RRR_Obj16A_DxDyCoVnce "Correlation coefficient of Dx and Dy";
CM_ SG_ 1328 RRR_Obj16A_DxVxCoVnce "Correlation coefficient of Dx and Vx";
CM_ SG_ 1328 RRR_Obj16A_BlockCtr "Block-Counter";
CM_ SG_ 1328 RRR_Obj16A_DyVxCoVnce "Correlation coefficient of Dy and Ax";
CM_ SG_ 1328 RRR_Obj16A_DxVyCoVnce "Correlation coefficient of Dx and Vy";
CM_ SG_ 1328 RRR_Obj16A_DyVyCoVnce "Correlation coefficient of Dy and Vy";
CM_ SG_ 1328 RRR_Obj16A_VxVyCoVnce "Correlation coefficient of Vx and Vy";
CM_ SG_ 1328 RRR_Obj16A_DxAxCoVnce "Correlation coefficient of Dx and Ax";
CM_ SG_ 1328 RRR_Obj16A_DyAxCoVnce "Correlation coefficient of Dy and Ax";
CM_ SG_ 1328 RRR_Obj16A_VxAxCoVnce "Correlation coefficient of Vx and Ax";
CM_ SG_ 1328 RRR_Obj16A_ObjectID "Unique Object ID";
CM_ SG_ 1328 RRR_Obj16A_VyAxCoVnce "Correlation coefficient of Vy and Ax";
CM_ SG_ 1328 RRR_Obj16A_DxAyCoVnce "Correlation coefficient of Dx and Ay";
CM_ SG_ 1328 RRR_Obj16A_DyAyCoVnce "Correlation coefficient of Dy and Ay";
CM_ SG_ 1328 RRR_Obj16A_VxAyCoVnce "Correlation coefficient of Vx and Ay";
CM_ SG_ 1328 RRR_Obj16A_VyAyCoVnce "Correlation coefficient of Vy and Ay";
CM_ SG_ 1328 RRR_Obj16A_AxAyCoVnce "Correlation coefficient of Ax and Ay";
CM_ SG_ 1328 RRR_Obj16A_Measured "Object is measured or not";
CM_ SG_ 1328 RRR_Obj16A_HeadingYawVnce "Variance of Object heading yaw angle";
CM_ SG_ 1328 RRR_Obj16A_Dx "Object position in X direction";
CM_ SG_ 1328 RRR_Obj16A_LengthVnce "Variance of Object Length";
CM_ SG_ 1328 RRR_Obj16A_WidthVnce "Variance of Object Width";
CM_ SG_ 1328 RRR_Obj16A_HeightVnce "Variance of Object Height";
CM_ SG_ 1328 RRR_Obj16A_ExistProb "Existence probability of object";
CM_ SG_ 1328 RRR_Obj16A_ProbObstacle "Probability of the object being an Obstacle";
CM_ SG_ 1328 RRR_Obj16A_ProbNonObstacle "Probability of the object being a Non-Obstacle";
CM_ SG_ 1328 RRR_Obj16A_ProbMobileObst "Probability of the object being a mobile obstacle";
CM_ SG_ 1328 RRR_Obj16A_FV "SecOC Freshness Value (Profile 1)";
CM_ SG_ 1328 RRR_Obj16A_MAC "SecOC MAC (Profile 1)";
CM_ SG_ 1328 RRR_Obj16A_Dz "Object position in Z direction";
CM_ SG_ 1328 RRR_Obj16A_Dy "Object position in Y direction";
CM_ SG_ 1328 RRR_Obj16A_Valid "Object is valid or not";
CM_ SG_ 1328 RRR_Obj16A_Vx "Object velocity in X direction";
CM_ SG_ 1328 RRR_Obj16A_Vy "Object velocity in Y direction";
CM_ SG_ 1328 RRR_Obj16A_Ax "Object acceleration in X direction";
CM_ SG_ 1329 RRR_Obj16B_CRC "CRC - Autosar E2E Profile 5";
CM_ SG_ 1329 RRR_Obj16B_MAC "SecOC MAC (Profile 1)";
CM_ SG_ 1329 RRR_Obj16B_AliveCtr "Alive counter - Autosar E2E Profile 5";
CM_ SG_ 1329 RRR_Obj16B_BlockCtr "Block-Counter";
CM_ SG_ 1329 RRR_Obj16B_ProbMob4PlusWhl "Probability of a mobile object which has 4 or more wheels";
CM_ SG_ 1329 RRR_Obj16B_ProbMob2Whl "Probability of a mobile object being 2-wheels vehicle";
CM_ SG_ 1329 RRR_Obj16B_ProbMobPed "Probability of a mobile object being a pedestrian";
CM_ SG_ 1329 RRR_Obj16B_Prob4PlusWhlCAR "Probability of a mobile object which has 4 or more wheels--passenger car";
CM_ SG_ 1329 RRR_Obj16B_Prob4PlusWhlbHGV "Probability of a mobile object which has 4 or more wheels--commercial vehicle(Turck)";
CM_ SG_ 1329 RRR_Obj16B_ProbGNDReflex "Probability of the object being a ground reflex";
CM_ SG_ 1329 RRR_Obj16B_ProbStatBarrier "Probability of the object being a stationary road barrier";
CM_ SG_ 1329 RRR_Obj16B_ProbStatObst "Probability of the object being a stationary obstacle";
CM_ SG_ 1329 RRR_Obj16B_MovingProbability "Object has been observed moving over the ground";
CM_ SG_ 1329 RRR_Obj16B_MovingObserved "Object has been observed moving over the ground since it was first detected";
CM_ SG_ 1329 RRR_Obj16B_FV "SecOC Freshness Value (Profile 1)";
CM_ SG_ 1330 RRR_Obj17A_CRC "CRC - Autosar E2E Profile 5";
CM_ SG_ 1330 RRR_Obj17A_Ay "Object acceleration in Y direction";
CM_ SG_ 1330 RRR_Obj17A_HeadingYawAngle "Object heading yaw angle";
CM_ SG_ 1330 RRR_Obj17A_Length "Object Length";
CM_ SG_ 1330 RRR_Obj17A_Width "Object Width";
CM_ SG_ 1330 RRR_Obj17A_Height "Object Height";
CM_ SG_ 1330 RRR_Obj17A_DxVnce "Variance of object position in X direction";
CM_ SG_ 1330 RRR_Obj17A_DyVnce "Variance of object position in Y direction";
CM_ SG_ 1330 RRR_Obj17A_DzVnce "Variance of object position in Z direction";
CM_ SG_ 1330 RRR_Obj17A_AliveCtr "Alive counter - Autosar E2E Profile 5";
CM_ SG_ 1330 RRR_Obj17A_VxVnce "Variance of object velocity in X direction";
CM_ SG_ 1330 RRR_Obj17A_VyVnce "Variance of object velocity in Y direction";
CM_ SG_ 1330 RRR_Obj17A_AxVnce "Variance of object acceleration in X direction";
CM_ SG_ 1330 RRR_Obj17A_AyVnce "Variance of object acceleration in Y direction";
CM_ SG_ 1330 RRR_Obj17A_RefPosIndex "Reference Position of the detected objects";
CM_ SG_ 1330 RRR_Obj17A_DxDyCoVnce "Correlation coefficient of Dx and Dy";
CM_ SG_ 1330 RRR_Obj17A_DxVxCoVnce "Correlation coefficient of Dx and Vx";
CM_ SG_ 1330 RRR_Obj17A_BlockCtr "Block-Counter";
CM_ SG_ 1330 RRR_Obj17A_DyVxCoVnce "Correlation coefficient of Dy and Ax";
CM_ SG_ 1330 RRR_Obj17A_DxVyCoVnce "Correlation coefficient of Dx and Vy";
CM_ SG_ 1330 RRR_Obj17A_DyVyCoVnce "Correlation coefficient of Dy and Vy";
CM_ SG_ 1330 RRR_Obj17A_VxVyCoVnce "Correlation coefficient of Vx and Vy";
CM_ SG_ 1330 RRR_Obj17A_DxAxCoVnce "Correlation coefficient of Dx and Ax";
CM_ SG_ 1330 RRR_Obj17A_DyAxCoVnce "Correlation coefficient of Dy and Ax";
CM_ SG_ 1330 RRR_Obj17A_VxAxCoVnce "Correlation coefficient of Vx and Ax";
CM_ SG_ 1330 RRR_Obj17A_ObjectID "Unique Object ID";
CM_ SG_ 1330 RRR_Obj17A_VyAxCoVnce "Correlation coefficient of Vy and Ax";
CM_ SG_ 1330 RRR_Obj17A_DxAyCoVnce "Correlation coefficient of Dx and Ay";
CM_ SG_ 1330 RRR_Obj17A_DyAyCoVnce "Correlation coefficient of Dy and Ay";
CM_ SG_ 1330 RRR_Obj17A_VxAyCoVnce "Correlation coefficient of Vx and Ay";
CM_ SG_ 1330 RRR_Obj17A_VyAyCoVnce "Correlation coefficient of Vy and Ay";
CM_ SG_ 1330 RRR_Obj17A_AxAyCoVnce "Correlation coefficient of Ax and Ay";
CM_ SG_ 1330 RRR_Obj17A_Measured "Object is measured or not";
CM_ SG_ 1330 RRR_Obj17A_HeadingYawVnce "Variance of Object heading yaw angle";
CM_ SG_ 1330 RRR_Obj17A_Dx "Object position in X direction";
CM_ SG_ 1330 RRR_Obj17A_LengthVnce "Variance of Object Length";
CM_ SG_ 1330 RRR_Obj17A_WidthVnce "Variance of Object Width";
CM_ SG_ 1330 RRR_Obj17A_HeightVnce "Variance of Object Height";
CM_ SG_ 1330 RRR_Obj17A_ExistProb "Existence probability of object";
CM_ SG_ 1330 RRR_Obj17A_ProbObstacle "Probability of the object being an Obstacle";
CM_ SG_ 1330 RRR_Obj17A_ProbNonObstacle "Probability of the object being a Non-Obstacle";
CM_ SG_ 1330 RRR_Obj17A_ProbMobileObst "Probability of the object being a mobile obstacle";
CM_ SG_ 1330 RRR_Obj17A_FV "SecOC Freshness Value (Profile 1)";
CM_ SG_ 1330 RRR_Obj17A_MAC "SecOC MAC (Profile 1)";
CM_ SG_ 1330 RRR_Obj17A_Dz "Object position in Z direction";
CM_ SG_ 1330 RRR_Obj17A_Dy "Object position in Y direction";
CM_ SG_ 1330 RRR_Obj17A_Valid "Object is valid or not";
CM_ SG_ 1330 RRR_Obj17A_Vx "Object velocity in X direction";
CM_ SG_ 1330 RRR_Obj17A_Vy "Object velocity in Y direction";
CM_ SG_ 1330 RRR_Obj17A_Ax "Object acceleration in X direction";
CM_ SG_ 1331 RRR_Obj17B_CRC "CRC - Autosar E2E Profile 5";
CM_ SG_ 1331 RRR_Obj17B_MAC "SecOC MAC (Profile 1)";
CM_ SG_ 1331 RRR_Obj17B_AliveCtr "Alive counter - Autosar E2E Profile 5";
CM_ SG_ 1331 RRR_Obj17B_BlockCtr "Block-Counter";
CM_ SG_ 1331 RRR_Obj17B_ProbMob4PlusWhl "Probability of a mobile object which has 4 or more wheels";
CM_ SG_ 1331 RRR_Obj17B_ProbMob2Whl "Probability of a mobile object being 2-wheels vehicle";
CM_ SG_ 1331 RRR_Obj17B_ProbMobPed "Probability of a mobile object being a pedestrian";
CM_ SG_ 1331 RRR_Obj17B_Prob4PlusWhlCAR "Probability of a mobile object which has 4 or more wheels--passenger car";
CM_ SG_ 1331 RRR_Obj17B_Prob4PlusWhlbHGV "Probability of a mobile object which has 4 or more wheels--commercial vehicle(Turck)";
CM_ SG_ 1331 RRR_Obj17B_ProbGNDReflex "Probability of the object being a ground reflex";
CM_ SG_ 1331 RRR_Obj17B_ProbStatBarrier "Probability of the object being a stationary road barrier";
CM_ SG_ 1331 RRR_Obj17B_ProbStatObst "Probability of the object being a stationary obstacle";
CM_ SG_ 1331 RRR_Obj17B_MovingProbability "Object has been observed moving over the ground";
CM_ SG_ 1331 RRR_Obj17B_MovingObserved "Object has been observed moving over the ground since it was first detected";
CM_ SG_ 1331 RRR_Obj17B_FV "SecOC Freshness Value (Profile 1)";
CM_ SG_ 1332 RRR_Obj18A_CRC "CRC - Autosar E2E Profile 5";
CM_ SG_ 1332 RRR_Obj18A_Ay "Object acceleration in Y direction";
CM_ SG_ 1332 RRR_Obj18A_HeadingYawAngle "Object heading yaw angle";
CM_ SG_ 1332 RRR_Obj18A_Length "Object Length";
CM_ SG_ 1332 RRR_Obj18A_Width "Object Width";
CM_ SG_ 1332 RRR_Obj18A_Height "Object Height";
CM_ SG_ 1332 RRR_Obj18A_DxVnce "Variance of object position in X direction";
CM_ SG_ 1332 RRR_Obj18A_DyVnce "Variance of object position in Y direction";
CM_ SG_ 1332 RRR_Obj18A_DzVnce "Variance of object position in Z direction";
CM_ SG_ 1332 RRR_Obj18A_AliveCtr "Alive counter - Autosar E2E Profile 5";
CM_ SG_ 1332 RRR_Obj18A_VxVnce "Variance of object velocity in X direction";
CM_ SG_ 1332 RRR_Obj18A_VyVnce "Variance of object velocity in Y direction";
CM_ SG_ 1332 RRR_Obj18A_AxVnce "Variance of object acceleration in X direction";
CM_ SG_ 1332 RRR_Obj18A_AyVnce "Variance of object acceleration in Y direction";
CM_ SG_ 1332 RRR_Obj18A_RefPosIndex "Reference Position of the detected objects";
CM_ SG_ 1332 RRR_Obj18A_DxDyCoVnce "Correlation coefficient of Dx and Dy";
CM_ SG_ 1332 RRR_Obj18A_DxVxCoVnce "Correlation coefficient of Dx and Vx";
CM_ SG_ 1332 RRR_Obj18A_BlockCtr "Block-Counter";
CM_ SG_ 1332 RRR_Obj18A_DyVxCoVnce "Correlation coefficient of Dy and Ax";
CM_ SG_ 1332 RRR_Obj18A_DxVyCoVnce "Correlation coefficient of Dx and Vy";
CM_ SG_ 1332 RRR_Obj18A_DyVyCoVnce "Correlation coefficient of Dy and Vy";
CM_ SG_ 1332 RRR_Obj18A_VxVyCoVnce "Correlation coefficient of Vx and Vy";
CM_ SG_ 1332 RRR_Obj18A_DxAxCoVnce "Correlation coefficient of Dx and Ax";
CM_ SG_ 1332 RRR_Obj18A_DyAxCoVnce "Correlation coefficient of Dy and Ax";
CM_ SG_ 1332 RRR_Obj18A_VxAxCoVnce "Correlation coefficient of Vx and Ax";
CM_ SG_ 1332 RRR_Obj18A_ObjectID "Unique Object ID";
CM_ SG_ 1332 RRR_Obj18A_VyAxCoVnce "Correlation coefficient of Vy and Ax";
CM_ SG_ 1332 RRR_Obj18A_DxAyCoVnce "Correlation coefficient of Dx and Ay";
CM_ SG_ 1332 RRR_Obj18A_DyAyCoVnce "Correlation coefficient of Dy and Ay";
CM_ SG_ 1332 RRR_Obj18A_VxAyCoVnce "Correlation coefficient of Vx and Ay";
CM_ SG_ 1332 RRR_Obj18A_VyAyCoVnce "Correlation coefficient of Vy and Ay";
CM_ SG_ 1332 RRR_Obj18A_AxAyCoVnce "Correlation coefficient of Ax and Ay";
CM_ SG_ 1332 RRR_Obj18A_Measured "Object is measured or not";
CM_ SG_ 1332 RRR_Obj18A_HeadingYawVnce "Variance of Object heading yaw angle";
CM_ SG_ 1332 RRR_Obj18A_Dx "Object position in X direction";
CM_ SG_ 1332 RRR_Obj18A_LengthVnce "Variance of Object Length";
CM_ SG_ 1332 RRR_Obj18A_WidthVnce "Variance of Object Width";
CM_ SG_ 1332 RRR_Obj18A_HeightVnce "Variance of Object Height";
CM_ SG_ 1332 RRR_Obj18A_ExistProb "Existence probability of object";
CM_ SG_ 1332 RRR_Obj18A_ProbObstacle "Probability of the object being an Obstacle";
CM_ SG_ 1332 RRR_Obj18A_ProbNonObstacle "Probability of the object being a Non-Obstacle";
CM_ SG_ 1332 RRR_Obj18A_ProbMobileObst "Probability of the object being a mobile obstacle";
CM_ SG_ 1332 RRR_Obj18A_FV "SecOC Freshness Value (Profile 1)";
CM_ SG_ 1332 RRR_Obj18A_MAC "SecOC MAC (Profile 1)";
CM_ SG_ 1332 RRR_Obj18A_Dz "Object position in Z direction";
CM_ SG_ 1332 RRR_Obj18A_Dy "Object position in Y direction";
CM_ SG_ 1332 RRR_Obj18A_Valid "Object is valid or not";
CM_ SG_ 1332 RRR_Obj18A_Vx "Object velocity in X direction";
CM_ SG_ 1332 RRR_Obj18A_Vy "Object velocity in Y direction";
CM_ SG_ 1332 RRR_Obj18A_Ax "Object acceleration in X direction";
CM_ SG_ 1333 RRR_Obj18B_CRC "CRC - Autosar E2E Profile 5";
CM_ SG_ 1333 RRR_Obj18B_MAC "SecOC MAC (Profile 1)";
CM_ SG_ 1333 RRR_Obj18B_AliveCtr "Alive counter - Autosar E2E Profile 5";
CM_ SG_ 1333 RRR_Obj18B_BlockCtr "Block-Counter";
CM_ SG_ 1333 RRR_Obj18B_ProbMob4PlusWhl "Probability of a mobile object which has 4 or more wheels";
CM_ SG_ 1333 RRR_Obj18B_ProbMob2Whl "Probability of a mobile object being 2-wheels vehicle";
CM_ SG_ 1333 RRR_Obj18B_ProbMobPed "Probability of a mobile object being a pedestrian";
CM_ SG_ 1333 RRR_Obj18B_Prob4PlusWhlCAR "Probability of a mobile object which has 4 or more wheels--passenger car";
CM_ SG_ 1333 RRR_Obj18B_Prob4PlusWhlbHGV "Probability of a mobile object which has 4 or more wheels--commercial vehicle(Turck)";
CM_ SG_ 1333 RRR_Obj18B_ProbGNDReflex "Probability of the object being a ground reflex";
CM_ SG_ 1333 RRR_Obj18B_ProbStatBarrier "Probability of the object being a stationary road barrier";
CM_ SG_ 1333 RRR_Obj18B_ProbStatObst "Probability of the object being a stationary obstacle";
CM_ SG_ 1333 RRR_Obj18B_MovingProbability "Object has been observed moving over the ground";
CM_ SG_ 1333 RRR_Obj18B_MovingObserved "Object has been observed moving over the ground since it was first detected";
CM_ SG_ 1333 RRR_Obj18B_FV "SecOC Freshness Value (Profile 1)";
CM_ SG_ 1334 RRR_Obj19A_CRC "CRC - Autosar E2E Profile 5";
CM_ SG_ 1334 RRR_Obj19A_Ay "Object acceleration in Y direction";
CM_ SG_ 1334 RRR_Obj19A_HeadingYawAngle "Object heading yaw angle";
CM_ SG_ 1334 RRR_Obj19A_Length "Object Length";
CM_ SG_ 1334 RRR_Obj19A_Width "Object Width";
CM_ SG_ 1334 RRR_Obj19A_Height "Object Height";
CM_ SG_ 1334 RRR_Obj19A_DxVnce "Variance of object position in X direction";
CM_ SG_ 1334 RRR_Obj19A_DyVnce "Variance of object position in Y direction";
CM_ SG_ 1334 RRR_Obj19A_DzVnce "Variance of object position in Z direction";
CM_ SG_ 1334 RRR_Obj19A_AliveCtr "Alive counter - Autosar E2E Profile 5";
CM_ SG_ 1334 RRR_Obj19A_VxVnce "Variance of object velocity in X direction";
CM_ SG_ 1334 RRR_Obj19A_VyVnce "Variance of object velocity in Y direction";
CM_ SG_ 1334 RRR_Obj19A_AxVnce "Variance of object acceleration in X direction";
CM_ SG_ 1334 RRR_Obj19A_AyVnce "Variance of object acceleration in Y direction";
CM_ SG_ 1334 RRR_Obj19A_RefPosIndex "Reference Position of the detected objects";
CM_ SG_ 1334 RRR_Obj19A_DxDyCoVnce "Correlation coefficient of Dx and Dy";
CM_ SG_ 1334 RRR_Obj19A_DxVxCoVnce "Correlation coefficient of Dx and Vx";
CM_ SG_ 1334 RRR_Obj19A_BlockCtr "Block-Counter";
CM_ SG_ 1334 RRR_Obj19A_DyVxCoVnce "Correlation coefficient of Dy and Ax";
CM_ SG_ 1334 RRR_Obj19A_DxVyCoVnce "Correlation coefficient of Dx and Vy";
CM_ SG_ 1334 RRR_Obj19A_DyVyCoVnce "Correlation coefficient of Dy and Vy";
CM_ SG_ 1334 RRR_Obj19A_VxVyCoVnce "Correlation coefficient of Vx and Vy";
CM_ SG_ 1334 RRR_Obj19A_DxAxCoVnce "Correlation coefficient of Dx and Ax";
CM_ SG_ 1334 RRR_Obj19A_DyAxCoVnce "Correlation coefficient of Dy and Ax";
CM_ SG_ 1334 RRR_Obj19A_VxAxCoVnce "Correlation coefficient of Vx and Ax";
CM_ SG_ 1334 RRR_Obj19A_ObjectID "Unique Object ID";
CM_ SG_ 1334 RRR_Obj19A_VyAxCoVnce "Correlation coefficient of Vy and Ax";
CM_ SG_ 1334 RRR_Obj19A_DxAyCoVnce "Correlation coefficient of Dx and Ay";
CM_ SG_ 1334 RRR_Obj19A_DyAyCoVnce "Correlation coefficient of Dy and Ay";
CM_ SG_ 1334 RRR_Obj19A_VxAyCoVnce "Correlation coefficient of Vx and Ay";
CM_ SG_ 1334 RRR_Obj19A_VyAyCoVnce "Correlation coefficient of Vy and Ay";
CM_ SG_ 1334 RRR_Obj19A_AxAyCoVnce "Correlation coefficient of Ax and Ay";
CM_ SG_ 1334 RRR_Obj19A_Measured "Object is measured or not";
CM_ SG_ 1334 RRR_Obj19A_HeadingYawVnce "Variance of Object heading yaw angle";
CM_ SG_ 1334 RRR_Obj19A_Dx "Object position in X direction";
CM_ SG_ 1334 RRR_Obj19A_LengthVnce "Variance of Object Length";
CM_ SG_ 1334 RRR_Obj19A_WidthVnce "Variance of Object Width";
CM_ SG_ 1334 RRR_Obj19A_HeightVnce "Variance of Object Height";
CM_ SG_ 1334 RRR_Obj19A_ExistProb "Existence probability of object";
CM_ SG_ 1334 RRR_Obj19A_ProbObstacle "Probability of the object being an Obstacle";
CM_ SG_ 1334 RRR_Obj19A_ProbNonObstacle "Probability of the object being a Non-Obstacle";
CM_ SG_ 1334 RRR_Obj19A_ProbMobileObst "Probability of the object being a mobile obstacle";
CM_ SG_ 1334 RRR_Obj19A_FV "SecOC Freshness Value (Profile 1)";
CM_ SG_ 1334 RRR_Obj19A_MAC "SecOC MAC (Profile 1)";
CM_ SG_ 1334 RRR_Obj19A_Dz "Object position in Z direction";
CM_ SG_ 1334 RRR_Obj19A_Dy "Object position in Y direction";
CM_ SG_ 1334 RRR_Obj19A_Valid "Object is valid or not";
CM_ SG_ 1334 RRR_Obj19A_Vx "Object velocity in X direction";
CM_ SG_ 1334 RRR_Obj19A_Vy "Object velocity in Y direction";
CM_ SG_ 1334 RRR_Obj19A_Ax "Object acceleration in X direction";
CM_ SG_ 1335 RRR_Obj19B_CRC "CRC - Autosar E2E Profile 5";
CM_ SG_ 1335 RRR_Obj19B_MAC "SecOC MAC (Profile 1)";
CM_ SG_ 1335 RRR_Obj19B_AliveCtr "Alive counter - Autosar E2E Profile 5";
CM_ SG_ 1335 RRR_Obj19B_BlockCtr "Block-Counter";
CM_ SG_ 1335 RRR_Obj19B_ProbMob4PlusWhl "Probability of a mobile object which has 4 or more wheels";
CM_ SG_ 1335 RRR_Obj19B_ProbMob2Whl "Probability of a mobile object being 2-wheels vehicle";
CM_ SG_ 1335 RRR_Obj19B_ProbMobPed "Probability of a mobile object being a pedestrian";
CM_ SG_ 1335 RRR_Obj19B_Prob4PlusWhlCAR "Probability of a mobile object which has 4 or more wheels--passenger car";
CM_ SG_ 1335 RRR_Obj19B_Prob4PlusWhlbHGV "Probability of a mobile object which has 4 or more wheels--commercial vehicle(Turck)";
CM_ SG_ 1335 RRR_Obj19B_ProbGNDReflex "Probability of the object being a ground reflex";
CM_ SG_ 1335 RRR_Obj19B_ProbStatBarrier "Probability of the object being a stationary road barrier";
CM_ SG_ 1335 RRR_Obj19B_ProbStatObst "Probability of the object being a stationary obstacle";
CM_ SG_ 1335 RRR_Obj19B_MovingProbability "Object has been observed moving over the ground";
CM_ SG_ 1335 RRR_Obj19B_MovingObserved "Object has been observed moving over the ground since it was first detected";
CM_ SG_ 1335 RRR_Obj19B_FV "SecOC Freshness Value (Profile 1)";
CM_ SG_ 824 RCW_TTC "0x0:No Display
0x1-0x3F:valid value";
CM_ SG_ 824 BSD_LCA_Left_TTC "0x0:No Display
0x1-0x3F:valid value";
CM_ SG_ 824 BSD_SDAStsLeftR "Indicator the SDA status for Rear Left Radar";
CM_ SG_ 824 CRC_338 "Checksum of 301";
CM_ SG_ 824 Alive_Counter_338 "Alive counter 301";
CM_ SG_ 824 BSD_BSDLCAWarn_LeftR "BSD/LCA warning request";
CM_ SG_ 824 BSD_RCTAWarn_LeftR "RCTA warning request";
CM_ SG_ 824 BSD_DOWWarn_LeftR "DOW warning request";
CM_ SG_ 824 BSD_RCWWarn_LeftR "RCW warning rcw_warninguest";
CM_ SG_ 824 BSD_CtaDeceReq_LeftR "RCTB Request";
CM_ SG_ 824 BSD_CtaDeceleration_LeftR "RCTB target deceleration";
CM_ SG_ 824 BSD_Failure_LeftR "Rear corner failure status";
CM_ SG_ 824 BSD_Blindness_LeftR "Rear corner blindness flag";
CM_ SG_ 1336 BSD_SDAStsRightL "Indicator the SDA status of  Rear Right";
CM_ SG_ 1336 CRC_538 "Checksum of 302";
CM_ SG_ 1336 Alive_Counter_538 "Alive counter 302";
CM_ SG_ 1336 BSD_LcaSwitch_RightL "switch";
CM_ SG_ 1336 BSD_CtaSwitch_RightL "switch";
CM_ SG_ 1336 BSD_DowSwitch_RightL "switch";
CM_ SG_ 1336 BSD_RcwSwitch_RightL "switch";
CM_ SG_ 1336 BSD_CtaBrakeSwitch_RightL "switch";
CM_ SG_ 1336 BSD_Failure_RightL "Rear corner failure status";
CM_ SG_ 1336 BSD_Blindness_RightL "Rear corner blindness flag";
BA_DEF_ BO_  "GenMsgCycleTime" INT 0 65535;
BA_DEF_ BO_  "GenMsgSendType" ENUM  "Event","Cycle";
BA_DEF_ SG_  "GenSigStartValue" FLOAT 0 100000000000;
BA_DEF_ BO_  "CANFD_BRS" ENUM  "0","1";
BA_DEF_ BO_  "VFrameFormat" ENUM  "StandardCAN","ExtendedCAN","reserved","reserved","reserved","reserved","reserved","reserved","reserved","reserved","reserved","reserved","reserved","reserved","StandardCAN_FD","ExtendedCAN_FD";
BA_DEF_DEF_  "GenMsgCycleTime" 0;
BA_DEF_DEF_  "GenMsgSendType" "";
BA_DEF_DEF_  "GenSigStartValue" 0;
BA_DEF_DEF_  "CANFD_BRS" "1";
BA_DEF_DEF_  "VFrameFormat" "StandardCAN";
BA_ "GenMsgSendType" BO_ 1310 0;
BA_ "VFrameFormat" BO_ 1310 14;
BA_ "GenMsgSendType" BO_ 1311 0;
BA_ "VFrameFormat" BO_ 1311 14;
BA_ "GenMsgSendType" BO_ 1312 0;
BA_ "VFrameFormat" BO_ 1312 14;
BA_ "GenMsgSendType" BO_ 1313 0;
BA_ "VFrameFormat" BO_ 1313 14;
BA_ "GenMsgSendType" BO_ 1314 0;
BA_ "VFrameFormat" BO_ 1314 14;
BA_ "GenMsgSendType" BO_ 1315 0;
BA_ "VFrameFormat" BO_ 1315 14;
BA_ "GenMsgSendType" BO_ 1316 0;
BA_ "VFrameFormat" BO_ 1316 14;
BA_ "GenMsgSendType" BO_ 1317 0;
BA_ "VFrameFormat" BO_ 1317 14;
BA_ "GenMsgSendType" BO_ 1318 0;
BA_ "VFrameFormat" BO_ 1318 14;
BA_ "GenMsgSendType" BO_ 1319 0;
BA_ "VFrameFormat" BO_ 1319 14;
BA_ "GenMsgSendType" BO_ 1320 0;
BA_ "VFrameFormat" BO_ 1320 14;
BA_ "GenMsgSendType" BO_ 1321 0;
BA_ "VFrameFormat" BO_ 1321 14;
BA_ "GenMsgSendType" BO_ 1322 0;
BA_ "VFrameFormat" BO_ 1322 14;
BA_ "GenMsgSendType" BO_ 1323 0;
BA_ "VFrameFormat" BO_ 1323 14;
BA_ "GenMsgSendType" BO_ 1324 0;
BA_ "VFrameFormat" BO_ 1324 14;
BA_ "GenMsgSendType" BO_ 1325 0;
BA_ "VFrameFormat" BO_ 1325 14;
BA_ "GenMsgSendType" BO_ 1326 0;
BA_ "VFrameFormat" BO_ 1326 14;
BA_ "GenMsgSendType" BO_ 1327 0;
BA_ "VFrameFormat" BO_ 1327 14;
BA_ "GenMsgSendType" BO_ 1328 0;
BA_ "VFrameFormat" BO_ 1328 14;
BA_ "GenMsgSendType" BO_ 1329 0;
BA_ "VFrameFormat" BO_ 1329 14;
BA_ "GenMsgSendType" BO_ 1330 0;
BA_ "VFrameFormat" BO_ 1330 14;
BA_ "GenMsgSendType" BO_ 1331 0;
BA_ "VFrameFormat" BO_ 1331 14;
BA_ "GenMsgSendType" BO_ 1332 0;
BA_ "VFrameFormat" BO_ 1332 14;
BA_ "GenMsgSendType" BO_ 1333 0;
BA_ "VFrameFormat" BO_ 1333 14;
BA_ "GenMsgSendType" BO_ 1334 0;
BA_ "VFrameFormat" BO_ 1334 14;
BA_ "GenMsgSendType" BO_ 1335 0;
BA_ "VFrameFormat" BO_ 1335 14;
BA_ "GenMsgSendType" BO_ 824 1;
BA_ "GenMsgCycleTime" BO_ 824 20;
BA_ "VFrameFormat" BO_ 824 14;
BA_ "GenMsgSendType" BO_ 1336 1;
BA_ "GenMsgCycleTime" BO_ 1336 20;
BA_ "VFrameFormat" BO_ 1336 14;
BA_ "GenSigStartValue" SG_ 1310 RRR_Obj07A_Ay 256;
BA_ "GenSigStartValue" SG_ 1310 RRR_Obj07A_HeadingYawAngle 256;
BA_ "GenSigStartValue" SG_ 1310 RRR_Obj07A_Dx 4096;
BA_ "GenSigStartValue" SG_ 1310 RRR_Obj07A_Dz 20;
BA_ "GenSigStartValue" SG_ 1310 RRR_Obj07A_Dy 1024;
BA_ "GenSigStartValue" SG_ 1310 RRR_Obj07A_Vx 2048;
BA_ "GenSigStartValue" SG_ 1310 RRR_Obj07A_Vy 512;
BA_ "GenSigStartValue" SG_ 1310 RRR_Obj07A_Ax 512;
BA_ "GenSigStartValue" SG_ 1312 RRR_Obj08A_Ay 256;
BA_ "GenSigStartValue" SG_ 1312 RRR_Obj08A_HeadingYawAngle 256;
BA_ "GenSigStartValue" SG_ 1312 RRR_Obj08A_Dx 4096;
BA_ "GenSigStartValue" SG_ 1312 RRR_Obj08A_Dz 20;
BA_ "GenSigStartValue" SG_ 1312 RRR_Obj08A_Dy 1024;
BA_ "GenSigStartValue" SG_ 1312 RRR_Obj08A_Vx 2048;
BA_ "GenSigStartValue" SG_ 1312 RRR_Obj08A_Vy 512;
BA_ "GenSigStartValue" SG_ 1312 RRR_Obj08A_Ax 512;
BA_ "GenSigStartValue" SG_ 1314 RRR_Obj09A_Ay 256;
BA_ "GenSigStartValue" SG_ 1314 RRR_Obj09A_HeadingYawAngle 256;
BA_ "GenSigStartValue" SG_ 1314 RRR_Obj09A_Dx 4096;
BA_ "GenSigStartValue" SG_ 1314 RRR_Obj09A_Dz 20;
BA_ "GenSigStartValue" SG_ 1314 RRR_Obj09A_Dy 1024;
BA_ "GenSigStartValue" SG_ 1314 RRR_Obj09A_Vx 2048;
BA_ "GenSigStartValue" SG_ 1314 RRR_Obj09A_Vy 512;
BA_ "GenSigStartValue" SG_ 1314 RRR_Obj09A_Ax 512;
BA_ "GenSigStartValue" SG_ 1316 RRR_Obj10A_Ay 256;
BA_ "GenSigStartValue" SG_ 1316 RRR_Obj10A_HeadingYawAngle 256;
BA_ "GenSigStartValue" SG_ 1316 RRR_Obj10A_Dx 4096;
BA_ "GenSigStartValue" SG_ 1316 RRR_Obj10A_Dz 20;
BA_ "GenSigStartValue" SG_ 1316 RRR_Obj10A_Dy 1024;
BA_ "GenSigStartValue" SG_ 1316 RRR_Obj10A_Vx 2048;
BA_ "GenSigStartValue" SG_ 1316 RRR_Obj10A_Vy 512;
BA_ "GenSigStartValue" SG_ 1316 RRR_Obj10A_Ax 512;
BA_ "GenSigStartValue" SG_ 1318 RRR_Obj11A_Ay 256;
BA_ "GenSigStartValue" SG_ 1318 RRR_Obj11A_HeadingYawAngle 256;
BA_ "GenSigStartValue" SG_ 1318 RRR_Obj11A_Dx 4096;
BA_ "GenSigStartValue" SG_ 1318 RRR_Obj11A_Dz 20;
BA_ "GenSigStartValue" SG_ 1318 RRR_Obj11A_Dy 1024;
BA_ "GenSigStartValue" SG_ 1318 RRR_Obj11A_Vx 2048;
BA_ "GenSigStartValue" SG_ 1318 RRR_Obj11A_Vy 512;
BA_ "GenSigStartValue" SG_ 1318 RRR_Obj11A_Ax 512;
BA_ "GenSigStartValue" SG_ 1320 RRR_Obj12A_Ay 256;
BA_ "GenSigStartValue" SG_ 1320 RRR_Obj12A_HeadingYawAngle 256;
BA_ "GenSigStartValue" SG_ 1320 RRR_Obj12A_Dx 4096;
BA_ "GenSigStartValue" SG_ 1320 RRR_Obj12A_Dz 20;
BA_ "GenSigStartValue" SG_ 1320 RRR_Obj12A_Dy 1024;
BA_ "GenSigStartValue" SG_ 1320 RRR_Obj12A_Vx 2048;
BA_ "GenSigStartValue" SG_ 1320 RRR_Obj12A_Vy 512;
BA_ "GenSigStartValue" SG_ 1320 RRR_Obj12A_Ax 512;
BA_ "GenSigStartValue" SG_ 1322 RRR_Obj13A_Ay 256;
BA_ "GenSigStartValue" SG_ 1322 RRR_Obj13A_HeadingYawAngle 256;
BA_ "GenSigStartValue" SG_ 1322 RRR_Obj13A_Dx 4096;
BA_ "GenSigStartValue" SG_ 1322 RRR_Obj13A_Dz 20;
BA_ "GenSigStartValue" SG_ 1322 RRR_Obj13A_Dy 1024;
BA_ "GenSigStartValue" SG_ 1322 RRR_Obj13A_Vx 2048;
BA_ "GenSigStartValue" SG_ 1322 RRR_Obj13A_Vy 512;
BA_ "GenSigStartValue" SG_ 1322 RRR_Obj13A_Ax 512;
BA_ "GenSigStartValue" SG_ 1324 RRR_Obj14A_Ay 256;
BA_ "GenSigStartValue" SG_ 1324 RRR_Obj14A_HeadingYawAngle 256;
BA_ "GenSigStartValue" SG_ 1324 RRR_Obj14A_Dx 4096;
BA_ "GenSigStartValue" SG_ 1324 RRR_Obj14A_Dz 20;
BA_ "GenSigStartValue" SG_ 1324 RRR_Obj14A_Dy 1024;
BA_ "GenSigStartValue" SG_ 1324 RRR_Obj14A_Vx 2048;
BA_ "GenSigStartValue" SG_ 1324 RRR_Obj14A_Vy 512;
BA_ "GenSigStartValue" SG_ 1324 RRR_Obj14A_Ax 512;
BA_ "GenSigStartValue" SG_ 1326 RRR_Obj15A_Ay 256;
BA_ "GenSigStartValue" SG_ 1326 RRR_Obj15A_HeadingYawAngle 256;
BA_ "GenSigStartValue" SG_ 1326 RRR_Obj15A_Dx 4096;
BA_ "GenSigStartValue" SG_ 1326 RRR_Obj15A_Dz 20;
BA_ "GenSigStartValue" SG_ 1326 RRR_Obj15A_Dy 1024;
BA_ "GenSigStartValue" SG_ 1326 RRR_Obj15A_Vx 2048;
BA_ "GenSigStartValue" SG_ 1326 RRR_Obj15A_Vy 512;
BA_ "GenSigStartValue" SG_ 1326 RRR_Obj15A_Ax 512;
BA_ "GenSigStartValue" SG_ 1328 RRR_Obj16A_Ay 256;
BA_ "GenSigStartValue" SG_ 1328 RRR_Obj16A_HeadingYawAngle 256;
BA_ "GenSigStartValue" SG_ 1328 RRR_Obj16A_Dx 4096;
BA_ "GenSigStartValue" SG_ 1328 RRR_Obj16A_Dz 20;
BA_ "GenSigStartValue" SG_ 1328 RRR_Obj16A_Dy 1024;
BA_ "GenSigStartValue" SG_ 1328 RRR_Obj16A_Vx 2048;
BA_ "GenSigStartValue" SG_ 1328 RRR_Obj16A_Vy 512;
BA_ "GenSigStartValue" SG_ 1328 RRR_Obj16A_Ax 512;
BA_ "GenSigStartValue" SG_ 1330 RRR_Obj17A_Ay 256;
BA_ "GenSigStartValue" SG_ 1330 RRR_Obj17A_HeadingYawAngle 256;
BA_ "GenSigStartValue" SG_ 1330 RRR_Obj17A_Dx 4096;
BA_ "GenSigStartValue" SG_ 1330 RRR_Obj17A_Dz 20;
BA_ "GenSigStartValue" SG_ 1330 RRR_Obj17A_Dy 1024;
BA_ "GenSigStartValue" SG_ 1330 RRR_Obj17A_Vx 2048;
BA_ "GenSigStartValue" SG_ 1330 RRR_Obj17A_Vy 512;
BA_ "GenSigStartValue" SG_ 1330 RRR_Obj17A_Ax 512;
BA_ "GenSigStartValue" SG_ 1332 RRR_Obj18A_Ay 256;
BA_ "GenSigStartValue" SG_ 1332 RRR_Obj18A_HeadingYawAngle 256;
BA_ "GenSigStartValue" SG_ 1332 RRR_Obj18A_Dx 4096;
BA_ "GenSigStartValue" SG_ 1332 RRR_Obj18A_Dz 20;
BA_ "GenSigStartValue" SG_ 1332 RRR_Obj18A_Dy 1024;
BA_ "GenSigStartValue" SG_ 1332 RRR_Obj18A_Vx 2048;
BA_ "GenSigStartValue" SG_ 1332 RRR_Obj18A_Vy 512;
BA_ "GenSigStartValue" SG_ 1332 RRR_Obj18A_Ax 512;
BA_ "GenSigStartValue" SG_ 1334 RRR_Obj19A_Ay 256;
BA_ "GenSigStartValue" SG_ 1334 RRR_Obj19A_HeadingYawAngle 256;
BA_ "GenSigStartValue" SG_ 1334 RRR_Obj19A_Dx 4096;
BA_ "GenSigStartValue" SG_ 1334 RRR_Obj19A_Dz 20;
BA_ "GenSigStartValue" SG_ 1334 RRR_Obj19A_Dy 1024;
BA_ "GenSigStartValue" SG_ 1334 RRR_Obj19A_Vx 2048;
BA_ "GenSigStartValue" SG_ 1334 RRR_Obj19A_Vy 512;
BA_ "GenSigStartValue" SG_ 1334 RRR_Obj19A_Ax 512;
VAL_ 1310 RRR_Obj07A_RefPosIndex 0 "Front corner left" 1 "Front center" 2 "Front corner right" 3 "Front wheelcase left" 4 "Front wheelcase right" 5 "Side middle left" 6 "Side middle right" 7 "Rear wheelcase left" 8 "Rear wheelcase right" 9 "Rear corner left" 10 "Rear center" 11 "Rear corner right" 12 "Object center" 13 "Rear wheelcase center" 14 "Front wheelcase center" 15 "Invalid" ;
VAL_ 1310 RRR_Obj07A_Measured 0 "not measured" 1 "measured" ;
VAL_ 1310 RRR_Obj07A_Valid 0 "not valid" 1 "valid" ;
VAL_ 1312 RRR_Obj08A_RefPosIndex 0 "Front corner left" 1 "Front center" 2 "Front corner right" 3 "Front wheelcase left" 4 "Front wheelcase right" 5 "Side middle left" 6 "Side middle right" 7 "Rear wheelcase left" 8 "Rear wheelcase right" 9 "Rear corner left" 10 "Rear center" 11 "Rear corner right" 12 "Object center" 13 "Rear wheelcase center" 14 "Front wheelcase center" 15 "Invalid" ;
VAL_ 1312 RRR_Obj08A_Measured 0 "not measured" 1 "measured" ;
VAL_ 1312 RRR_Obj08A_Valid 0 "not valid" 1 "valid" ;
VAL_ 1314 RRR_Obj09A_RefPosIndex 0 "Front corner left" 1 "Front center" 2 "Front corner right" 3 "Front wheelcase left" 4 "Front wheelcase right" 5 "Side middle left" 6 "Side middle right" 7 "Rear wheelcase left" 8 "Rear wheelcase right" 9 "Rear corner left" 10 "Rear center" 11 "Rear corner right" 12 "Object center" 13 "Rear wheelcase center" 14 "Front wheelcase center" 15 "Invalid" ;
VAL_ 1314 RRR_Obj09A_Measured 0 "not measured" 1 "measured" ;
VAL_ 1314 RRR_Obj09A_Valid 0 "not valid" 1 "valid" ;
VAL_ 1316 RRR_Obj10A_RefPosIndex 0 "Front corner left" 1 "Front center" 2 "Front corner right" 3 "Front wheelcase left" 4 "Front wheelcase right" 5 "Side middle left" 6 "Side middle right" 7 "Rear wheelcase left" 8 "Rear wheelcase right" 9 "Rear corner left" 10 "Rear center" 11 "Rear corner right" 12 "Object center" 13 "Rear wheelcase center" 14 "Front wheelcase center" 15 "Invalid" ;
VAL_ 1316 RRR_Obj10A_Measured 0 "not measured" 1 "measured" ;
VAL_ 1316 RRR_Obj10A_Valid 0 "not valid" 1 "valid" ;
VAL_ 1318 RRR_Obj11A_RefPosIndex 0 "Front corner left" 1 "Front center" 2 "Front corner right" 3 "Front wheelcase left" 4 "Front wheelcase right" 5 "Side middle left" 6 "Side middle right" 7 "Rear wheelcase left" 8 "Rear wheelcase right" 9 "Rear corner left" 10 "Rear center" 11 "Rear corner right" 12 "Object center" 13 "Rear wheelcase center" 14 "Front wheelcase center" 15 "Invalid" ;
VAL_ 1318 RRR_Obj11A_Measured 0 "not measured" 1 "measured" ;
VAL_ 1318 RRR_Obj11A_Valid 0 "not valid" 1 "valid" ;
VAL_ 1320 RRR_Obj12A_RefPosIndex 0 "Front corner left" 1 "Front center" 2 "Front corner right" 3 "Front wheelcase left" 4 "Front wheelcase right" 5 "Side middle left" 6 "Side middle right" 7 "Rear wheelcase left" 8 "Rear wheelcase right" 9 "Rear corner left" 10 "Rear center" 11 "Rear corner right" 12 "Object center" 13 "Rear wheelcase center" 14 "Front wheelcase center" 15 "Invalid" ;
VAL_ 1320 RRR_Obj12A_Measured 0 "not measured" 1 "measured" ;
VAL_ 1320 RRR_Obj12A_Valid 0 "not valid" 1 "valid" ;
VAL_ 1322 RRR_Obj13A_RefPosIndex 0 "Front corner left" 1 "Front center" 2 "Front corner right" 3 "Front wheelcase left" 4 "Front wheelcase right" 5 "Side middle left" 6 "Side middle right" 7 "Rear wheelcase left" 8 "Rear wheelcase right" 9 "Rear corner left" 10 "Rear center" 11 "Rear corner right" 12 "Object center" 13 "Rear wheelcase center" 14 "Front wheelcase center" 15 "Invalid" ;
VAL_ 1322 RRR_Obj13A_Measured 0 "not measured" 1 "measured" ;
VAL_ 1322 RRR_Obj13A_Valid 0 "not valid" 1 "valid" ;
VAL_ 1324 RRR_Obj14A_RefPosIndex 0 "Front corner left" 1 "Front center" 2 "Front corner right" 3 "Front wheelcase left" 4 "Front wheelcase right" 5 "Side middle left" 6 "Side middle right" 7 "Rear wheelcase left" 8 "Rear wheelcase right" 9 "Rear corner left" 10 "Rear center" 11 "Rear corner right" 12 "Object center" 13 "Rear wheelcase center" 14 "Front wheelcase center" 15 "Invalid" ;
VAL_ 1324 RRR_Obj14A_Measured 0 "not measured" 1 "measured" ;
VAL_ 1324 RRR_Obj14A_Valid 0 "not valid" 1 "valid" ;
VAL_ 1326 RRR_Obj15A_RefPosIndex 0 "Front corner left" 1 "Front center" 2 "Front corner right" 3 "Front wheelcase left" 4 "Front wheelcase right" 5 "Side middle left" 6 "Side middle right" 7 "Rear wheelcase left" 8 "Rear wheelcase right" 9 "Rear corner left" 10 "Rear center" 11 "Rear corner right" 12 "Object center" 13 "Rear wheelcase center" 14 "Front wheelcase center" 15 "Invalid" ;
VAL_ 1326 RRR_Obj15A_Measured 0 "not measured" 1 "measured" ;
VAL_ 1326 RRR_Obj15A_Valid 0 "not valid" 1 "valid" ;
VAL_ 1328 RRR_Obj16A_RefPosIndex 0 "Front corner left" 1 "Front center" 2 "Front corner right" 3 "Front wheelcase left" 4 "Front wheelcase right" 5 "Side middle left" 6 "Side middle right" 7 "Rear wheelcase left" 8 "Rear wheelcase right" 9 "Rear corner left" 10 "Rear center" 11 "Rear corner right" 12 "Object center" 13 "Rear wheelcase center" 14 "Front wheelcase center" 15 "Invalid" ;
VAL_ 1328 RRR_Obj16A_Measured 0 "not measured" 1 "measured" ;
VAL_ 1328 RRR_Obj16A_Valid 0 "not valid" 1 "valid" ;
VAL_ 1330 RRR_Obj17A_RefPosIndex 0 "Front corner left" 1 "Front center" 2 "Front corner right" 3 "Front wheelcase left" 4 "Front wheelcase right" 5 "Side middle left" 6 "Side middle right" 7 "Rear wheelcase left" 8 "Rear wheelcase right" 9 "Rear corner left" 10 "Rear center" 11 "Rear corner right" 12 "Object center" 13 "Rear wheelcase center" 14 "Front wheelcase center" 15 "Invalid" ;
VAL_ 1330 RRR_Obj17A_Measured 0 "not measured" 1 "measured" ;
VAL_ 1330 RRR_Obj17A_Valid 0 "not valid" 1 "valid" ;
VAL_ 1332 RRR_Obj18A_RefPosIndex 0 "Front corner left" 1 "Front center" 2 "Front corner right" 3 "Front wheelcase left" 4 "Front wheelcase right" 5 "Side middle left" 6 "Side middle right" 7 "Rear wheelcase left" 8 "Rear wheelcase right" 9 "Rear corner left" 10 "Rear center" 11 "Rear corner right" 12 "Object center" 13 "Rear wheelcase center" 14 "Front wheelcase center" 15 "Invalid" ;
VAL_ 1332 RRR_Obj18A_Measured 0 "not measured" 1 "measured" ;
VAL_ 1332 RRR_Obj18A_Valid 0 "not valid" 1 "valid" ;
VAL_ 1334 RRR_Obj19A_RefPosIndex 0 "Front corner left" 1 "Front center" 2 "Front corner right" 3 "Front wheelcase left" 4 "Front wheelcase right" 5 "Side middle left" 6 "Side middle right" 7 "Rear wheelcase left" 8 "Rear wheelcase right" 9 "Rear corner left" 10 "Rear center" 11 "Rear corner right" 12 "Object center" 13 "Rear wheelcase center" 14 "Front wheelcase center" 15 "Invalid" ;
VAL_ 1334 RRR_Obj19A_Measured 0 "not measured" 1 "measured" ;
VAL_ 1334 RRR_Obj19A_Valid 0 "not valid" 1 "valid" ;
VAL_ 824 RCW_TTC 63 "valid value" 62 "valid value" 61 "valid value" 60 "valid value" 59 "valid value" 58 "valid value" 57 "valid value" 56 "valid value" 55 "valid value" 54 "valid value" 53 "valid value" 52 "valid value" 51 "valid value" 50 "valid value" 49 "valid value" 48 "valid value" 47 "valid value" 46 "valid value" 45 "valid value" 44 "valid value" 43 "valid value" 42 "valid value" 41 "valid value" 40 "valid value" 39 "valid value" 38 "valid value" 37 "valid value" 36 "valid value" 35 "valid value" 34 "valid value" 33 "valid value" 32 "valid value" 31 "valid value" 30 "valid value" 29 "valid value" 28 "valid value" 27 "valid value" 26 "valid value" 25 "valid value" 24 "valid value" 23 "valid value" 22 "valid value" 21 "valid value" 20 "valid value" 19 "valid value" 18 "valid value" 17 "valid value" 16 "valid value" 15 "valid value" 14 "valid value" 13 "valid value" 12 "valid value" 11 "valid value" 10 "valid value" 9 "valid value" 8 "valid value" 7 "valid value" 6 "valid value" 5 "valid value" 4 "valid value" 3 "valid value" 2 "valid value" 1 "valid value" 0 "No Display" ;
VAL_ 824 BSD_LCA_Left_TTC 63 "valid value" 62 "valid value" 61 "valid value" 60 "valid value" 59 "valid value" 58 "valid value" 57 "valid value" 56 "valid value" 55 "valid value" 54 "valid value" 53 "valid value" 52 "valid value" 51 "valid value" 50 "valid value" 49 "valid value" 48 "valid value" 47 "valid value" 46 "valid value" 45 "valid value" 44 "valid value" 43 "valid value" 42 "valid value" 41 "valid value" 40 "valid value" 39 "valid value" 38 "valid value" 37 "valid value" 36 "valid value" 35 "valid value" 34 "valid value" 33 "valid value" 32 "valid value" 31 "valid value" 30 "valid value" 29 "valid value" 28 "valid value" 27 "valid value" 26 "valid value" 25 "valid value" 24 "valid value" 23 "valid value" 22 "valid value" 21 "valid value" 20 "valid value" 19 "valid value" 18 "valid value" 17 "valid value" 16 "valid value" 15 "valid value" 14 "valid value" 13 "valid value" 12 "valid value" 11 "valid value" 10 "valid value" 9 "valid value" 8 "valid value" 7 "valid value" 6 "valid value" 5 "valid value" 4 "valid value" 3 "valid value" 2 "valid value" 1 "valid value" 0 "No Display" ;
VAL_ 824 RL_ModulationStatus_RR 3 "Reserved" 2 "Modulation off" 0 "normal" 1 "Time sync fail" ;
VAL_ 824 BSD_SDAStsLeftR 3 "Fail" 2 "Pass" 1 "Ongoing" 0 "Not start" ;
VAL_ 824 BSD_BSDLCAWarn_LeftR 0 "no warning" 1 "Warning level1" 2 "Warning level2" 3 "reserved" ;
VAL_ 824 BSD_RCTAWarn_LeftR 0 "no warning" 1 "Warning level1" 2 "Warning level2" 3 "reserved" ;
VAL_ 824 BSD_DOWWarn_LeftR 0 "no warning" 1 "Warning level1" 2 "Warning level2" 3 "reserved" ;
VAL_ 824 BSD_RCWWarn_LeftR 0 "no warning" 1 "Warning level1" 2 "Warning level2" 3 "reserved" ;
VAL_ 824 BSD_CtaDeceReq_LeftR 0 "No Demand" 1 "Demand" ;
VAL_ 824 BSD_Failure_LeftR 0 "No Failure" 1 "Reversible Failure" 2 "Irrversible Failure" 3 "Reserved" ;
VAL_ 824 BSD_Blindness_LeftR 1 "Blind" 0 "No Blind" ;
VAL_ 1336 BSD_SDAStsRightL 3 "Fail" 2 "Pass" 1 "Ongoing" 0 "Not start" ;
VAL_ 1336 BSD_LcaSwitch_RightL 0 "Off" 1 "ON" ;
VAL_ 1336 BSD_CtaSwitch_RightL 0 "Off" 1 "ON" ;
VAL_ 1336 BSD_DowSwitch_RightL 0 "Off" 1 "ON" ;
VAL_ 1336 BSD_RcwSwitch_RightL 0 "Off" 1 "ON" ;
VAL_ 1336 BSD_CtaBrakeSwitch_RightL 0 "Off" 1 "ON" ;
VAL_ 1336 BSD_Failure_RightL 0 "No failure" 1 "Reversible Failure" 2 "rrversible Failure" 3 "Reserved" ;
VAL_ 1336 BSD_Blindness_RightL 1 "Blind" 0 "No Blind" ;
